VERSION ""

NS_ :

BS_:

BU_: GW_ABFD ADCU3_ABFD

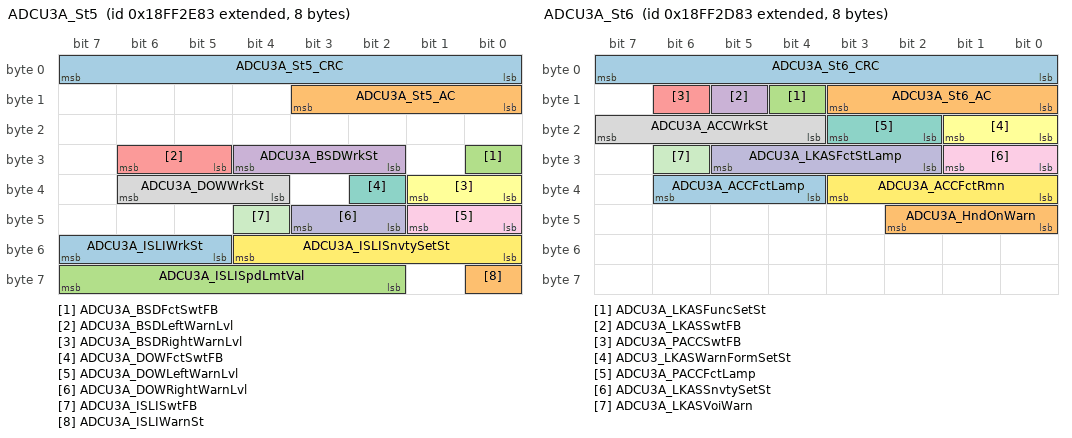
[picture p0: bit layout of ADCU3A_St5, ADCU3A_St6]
BO_ 2566860419 ADCU3A_St5: 8 ADCU3_ABFD
 SG_ ADCU3A_St5_CRC : 0|8@1+ (1,0) [0|255] "" Vector__XXX
 SG_ ADCU3A_St5_AC : 8|4@1+ (1,0) [0|14] "" Vector__XXX
 SG_ ADCU3A_BSDFctSwtFB : 24|1@1+ (1,0) [0|1] "" Vector__XXX
 SG_ ADCU3A_BSDWrkSt : 26|3@1+ (1,0) [0|7] "" Vector__XXX
 SG_ ADCU3A_BSDLeftWarnLvl : 29|2@1+ (1,0) [0|3] "" Vector__XXX
 SG_ ADCU3A_BSDRightWarnLvl : 32|2@1+ (1,0) [0|3] "" Vector__XXX
 SG_ ADCU3A_DOWFctSwtFB : 34|1@1+ (1,0) [0|1] "" Vector__XXX
 SG_ ADCU3A_DOWWrkSt : 36|3@1+ (1,0) [0|7] "" Vector__XXX
 SG_ ADCU3A_DOWLeftWarnLvl : 40|2@1+ (1,0) [0|3] "" Vector__XXX
 SG_ ADCU3A_DOWRightWarnLvl : 42|2@1+ (1,0) [0|3] "" Vector__XXX
 SG_ ADCU3A_ISLISwtFB : 44|1@1+ (1,0) [0|1] "" Vector__XXX
 SG_ ADCU3A_ISLISnvtySetSt : 48|5@1+ (1,-15) [-15|15] "km/h" Vector__XXX
 SG_ ADCU3A_ISLIWrkSt : 53|3@1+ (1,0) [0|7] "" Vector__XXX
 SG_ ADCU3A_ISLIWarnSt : 56|1@1+ (1,0) [0|1] "" Vector__XXX
 SG_ ADCU3A_ISLISpdLmtVal : 58|6@1+ (1,0) [0|63] "" Vector__XXX

BO_ 2566860163 ADCU3A_St6: 8 ADCU3_ABFD
 SG_ ADCU3A_St6_CRC : 0|8@1+ (1,0) [0|255] "" Vector__XXX
 SG_ ADCU3A_St6_AC : 8|4@1+ (1,0) [0|14] "" Vector__XXX
 SG_ ADCU3A_LKASFuncSetSt : 12|1@1+ (1,0) [0|1] "" Vector__XXX
 SG_ ADCU3A_LKASSwtFB : 13|1@1+ (1,0) [0|1] "" Vector__XXX
 SG_ ADCU3A_PACCSwtFB : 14|1@1+ (1,0) [0|1] "" Vector__XXX
 SG_ ADCU3_LKASWarnFormSetSt : 16|2@1+ (1,0) [0|3] "" Vector__XXX
 SG_ ADCU3A_PACCFctLamp : 18|2@1+ (1,0) [0|3] "" Vector__XXX
 SG_ ADCU3A_ACCWrkSt : 20|4@1+ (1,0) [0|15] "" Vector__XXX
 SG_ ADCU3A_LKASSnvtySetSt : 24|2@1+ (1,0) [0|3] "" Vector__XXX
 SG_ ADCU3A_LKASFctStLamp : 26|4@1+ (1,0) [0|15] "" Vector__XXX
 SG_ ADCU3A_LKASVoiWarn : 30|1@1+ (1,0) [0|1] "" Vector__XXX
 SG_ ADCU3A_ACCFctRmn : 32|4@1+ (1,0) [0|15] "" Vector__XXX
 SG_ ADCU3A_ACCFctLamp : 36|3@1+ (1,0) [0|7] "" Vector__XXX
 SG_ ADCU3A_HndOnWarn : 40|3@1+ (1,0) [0|7] "" Vector__XXX

BO_ 692 ADCU3A_St7: 16 ADCU3_ABFD
 SG_ ADCU3A_St7_CRC : 0|8@1+ (1,0) [0|255] "" Vector__XXX
 SG_ ADCU3A_St7_AC : 8|4@1+ (1,0) [0|14] "" Vector__XXX
 SG_ ADCU3A_AEBWrkSt : 12|3@1+ (1,0) [0|7] "" Vector__XXX
 SG_ ADCU3A_FwdCllsnPrevnSwtSt : 16|1@1+ (1,0) [0|1] "" Vector__XXX
 SG_ ADCU3A_FwdCllsnPrevnMdSwtSt : 17|1@1+ (1,0) [0|1] "" Vector__XXX
 SG_ ADCU3A_FwdCllsnPrevnSnvtySetSt : 18|2@1+ (1,0) [0|3] "" Vector__XXX
 SG_ ADCU3A_FCWAEBWarnLvl : 22|2@1+ (1,0) [0|3] "" Vector__XXX
 SG_ ADCU3A_FCWWrkSt : 24|3@1+ (1,0) [0|7] "" Vector__XXX
 SG_ ADCU3A_AEBTrgType : 27|2@1+ (1,0) [0|3] "" Vector__XXX
 SG_ ADCU3A_AEBTypeTar : 29|3@1+ (1,0) [0|7] "" Vector__XXX
 SG_ ADCU3A_AEBRelDst : 32|12@1+ (0.05,0) [0|204.75] "m" Vector__XXX
 SG_ ADCU3A_AEBRelSpd : 46|10@1+ (0.5,-255) [-255|255] "kph" Vector__XXX
 SG_ ADCU3A_AEBTTC : 56|8@1+ (0.05,0) [0|12.5] "s" Vector__XXX
 SG_ ADCU3A_FwdCllsnPrevnStLamp : 64|3@1+ (1,0) [0|7] "" Vector__XXX
 SG_ ADCU3A_FwdCllsnPrevnTstMsg : 67|3@1+ (1,0) [0|7] "" Vector__XXX
 SG_ ADCU3A_NightVisnSwtSt : 72|1@1+ (1,0) [0|1] "" Vector__XXX
 SG_ ADCU3A_NightVisnWarnMod : 73|2@1+ (1,0) [0|3] "" Vector__XXX
 SG_ ADCU3A_NightVisnFctWarn : 75|3@1+ (1,0) [0|7] "" Vector__XXX
 SG_ ADCU3A_NightVisnFctFlt : 78|1@1+ (1,0) [0|1] "" Vector__XXX

BO_ 1139 ADCU3A_Err: 16 ADCU3_ABFD
 SG_ ADCU3A_Err_CRC : 0|16@1+ (1,0) [0|65535] "" Vector__XXX
 SG_ ADCU3A_Err_AC : 16|8@1+ (1,0) [0|255] "" Vector__XXX
 SG_ ADCU3A_ADCU1Err : 24|2@1+ (1,0) [0|3] "" Vector__XXX
 SG_ ADCU3A_ADCU2Err : 26|2@1+ (1,0) [0|3] "" Vector__XXX
 SG_ ADCU3A_ADCU3Err : 28|2@1+ (1,0) [0|3] "" Vector__XXX
 SG_ ADCU3A_FrInfraredCamErr : 30|2@1+ (1,0) [0|3] "" Vector__XXX
 SG_ ADCU3A_FrRadarErr : 32|3@1+ (1,0) [0|7] "" Vector__XXX
 SG_ ADCU3A_LFCornrRadarErr : 35|3@1+ (1,0) [0|7] "" Vector__XXX
 SG_ ADCU3A_RFCornrRadarErr : 40|3@1+ (1,0) [0|7] "" Vector__XXX
 SG_ ADCU3A_LRCornrRadarErr : 43|3@1+ (1,0) [0|7] "" Vector__XXX
 SG_ ADCU3A_RRCornrRadarErr : 48|3@1+ (1,0) [0|7] "" Vector__XXX
 SG_ ADCU3A_LFSideViewCamErr : 53|2@1+ (1,0) [0|3] "" Vector__XXX
 SG_ ADCU3A_RFSideViewCamErr : 56|2@1+ (1,0) [0|3] "" Vector__XXX
 SG_ ADCU3A_LRSideViewCamErr : 58|2@1+ (1,0) [0|3] "" Vector__XXX
 SG_ ADCU3A_RRSideViewCamErr : 60|2@1+ (1,0) [0|3] "" Vector__XXX
 SG_ ADCU3A_FrSurrndViewCamErr : 62|2@1+ (1,0) [0|3] "" Vector__XXX
 SG_ ADCU3A_LFSurrndViewCamErr : 64|2@1+ (1,0) [0|3] "" Vector__XXX
 SG_ ADCU3A_RFSurrndViewCamErr : 66|2@1+ (1,0) [0|3] "" Vector__XXX
 SG_ ADCU3A_FrLidarErr : 68|2@1+ (1,0) [0|3] "" Vector__XXX
 SG_ ADCU3A_FrIntelgtCamErr : 72|3@1+ (1,0) [0|3] "" Vector__XXX
 SG_ ADCU3A_FrLongFocusCamErr : 75|2@1+ (1,0) [0|3] "" Vector__XXX
 SG_ ADCU3A_FrMidFocusCamErr : 77|2@1+ (1,0) [0|3] "" Vector__XXX
 SG_ ADCU3A_FrshrtFocusCamErr : 80|2@1+ (1,0) [0|3] "" Vector__XXX

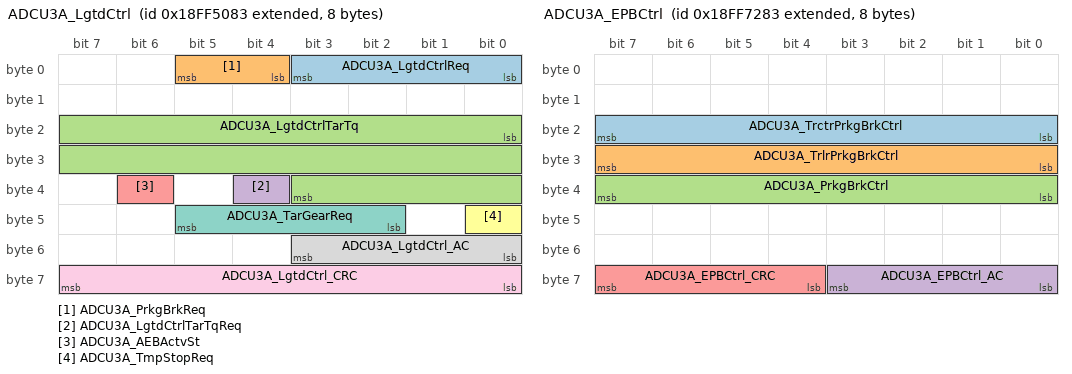
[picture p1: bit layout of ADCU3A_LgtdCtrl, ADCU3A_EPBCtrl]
BO_ 2566869123 ADCU3A_LgtdCtrl: 8 ADCU3_ABFD
 SG_ ADCU3A_LgtdCtrlReq : 0|4@1+ (1,0) [0|15] "" Vector__XXX
 SG_ ADCU3A_PrkgBrkReq : 4|2@1+ (1,0) [0|3] "" Vector__XXX
 SG_ ADCU3A_LgtdCtrlTarTq : 16|20@1+ (5,-150000) [-150000|150000] "Nm" Vector__XXX
 SG_ ADCU3A_LgtdCtrlTarTqReq : 36|1@1+ (1,0) [0|1] "" Vector__XXX
 SG_ ADCU3A_AEBActvSt : 38|1@1+ (1,0) [0|1] "" Vector__XXX
 SG_ ADCU3A_TmpStopReq : 40|1@1+ (1,0) [0|1] "" Vector__XXX
 SG_ ADCU3A_TarGearReq : 42|4@1+ (1,0) [0|15] "" Vector__XXX
 SG_ ADCU3A_LgtdCtrl_AC : 48|4@1+ (1,0) [0|14] "" Vector__XXX
 SG_ ADCU3A_LgtdCtrl_CRC : 56|8@1+ (1,0) [0|255] "" Vector__XXX

BO_ 2566877827 ADCU3A_EPBCtrl: 8 ADCU3_ABFD
 SG_ ADCU3A_TrctrPrkgBrkCtrl : 16|8@1+ (0.4,0) [0|100] "%" Vector__XXX
 SG_ ADCU3A_TrlrPrkgBrkCtrl : 24|8@1+ (0.4,0) [0|100] "%" Vector__XXX
 SG_ ADCU3A_PrkgBrkCtrl : 32|8@1+ (0.4,0) [0|100] "%" Vector__XXX
 SG_ ADCU3A_EPBCtrl_AC : 56|4@1+ (1,0) [0|15] "" Vector__XXX
 SG_ ADCU3A_EPBCtrl_CRC : 60|4@1+ (1,0) [0|15] "" Vector__XXX

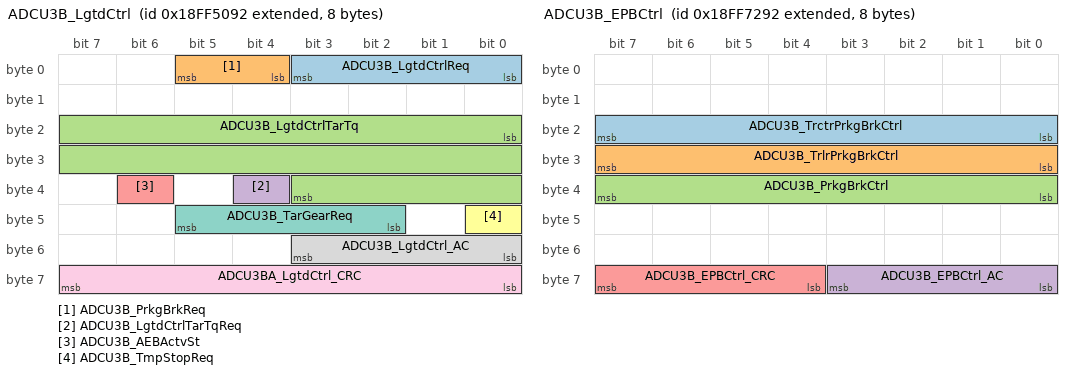
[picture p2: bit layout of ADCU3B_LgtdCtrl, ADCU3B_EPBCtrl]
BO_ 2566869138 ADCU3B_LgtdCtrl: 8 ADCU3_ABFD
 SG_ ADCU3B_LgtdCtrlReq : 0|4@1+ (1,0) [0|15] "" Vector__XXX
 SG_ ADCU3B_PrkgBrkReq : 4|2@1+ (1,0) [0|3] "" Vector__XXX
 SG_ ADCU3B_LgtdCtrlTarTq : 16|20@1+ (5,-150000) [-150000|150000] "Nm" Vector__XXX
 SG_ ADCU3B_LgtdCtrlTarTqReq : 36|1@1+ (1,0) [0|1] "" Vector__XXX
 SG_ ADCU3B_AEBActvSt : 38|1@1+ (1,0) [0|1] "" Vector__XXX
 SG_ ADCU3B_TmpStopReq : 40|1@1+ (1,0) [0|1] "" Vector__XXX
 SG_ ADCU3B_TarGearReq : 42|4@1+ (1,0) [0|15] "" Vector__XXX
 SG_ ADCU3B_LgtdCtrl_AC : 48|4@1+ (1,0) [0|14] "" Vector__XXX
 SG_ ADCU3BA_LgtdCtrl_CRC : 56|8@1+ (1,0) [0|255] "" Vector__XXX

BO_ 2566877842 ADCU3B_EPBCtrl: 8 ADCU3_ABFD
 SG_ ADCU3B_TrctrPrkgBrkCtrl : 16|8@1+ (0.4,0) [0|100] "%" Vector__XXX
 SG_ ADCU3B_TrlrPrkgBrkCtrl : 24|8@1+ (0.4,0) [0|100] "%" Vector__XXX
 SG_ ADCU3B_PrkgBrkCtrl : 32|8@1+ (0.4,0) [0|100] "%" Vector__XXX
 SG_ ADCU3B_EPBCtrl_AC : 56|4@1+ (1,0) [0|15] "" Vector__XXX
 SG_ ADCU3B_EPBCtrl_CRC : 60|4@1+ (1,0) [0|15] "" Vector__XXX

BO_ 2566860675 ADCU3A_BodyCtrl: 8 ADCU3_ABFD
 SG_ ADCU3A_BodyCtrl_CRC : 0|8@1+ (1,0) [0|255] "" Vector__XXX
 SG_ ADCU3A_BodyCtrl_AC : 8|4@1+ (1,0) [0|14] "" Vector__XXX
 SG_ ADCU3A_LeftTurnLgtReq : 12|2@1+ (1,0) [0|3] "" Vector__XXX
 SG_ ADCU3A_RightTurnLgtReq : 14|2@1+ (1,0) [0|3] "" Vector__XXX
 SG_ ADCU3A_HzrdLgtReq : 16|2@1+ (1,0) [0|3] "" Vector__XXX
 SG_ ADCU3A_LoLgtReq : 18|2@1+ (1,0) [0|3] "" Vector__XXX
 SG_ ADCU3A_OvtkLgtReq : 22|2@1+ (1,0) [0|3] "" Vector__XXX
 SG_ ADCU3A_SteerWhlVibrnReq : 24|2@1+ (1,0) [0|3] "" Vector__XXX
 SG_ ADCU3A_DrvrSeatVibrnReq : 26|2@1+ (1,0) [0|3] "" Vector__XXX
 SG_ ADCU3A_ClrCamReq : 28|2@1+ (1,0) [0|3] "" Vector__XXX
 SG_ ADCU3A_ClrLidarReq : 30|2@1+ (1,0) [0|3] "" Vector__XXX
 SG_ ADCU3A_DrvrSbltTightenUpReq : 32|2@1+ (1,0) [0|3] "" Vector__XXX
 SG_ ADCU3A_PsngerSbltTightenUpReq : 34|2@1+ (1,0) [0|3] "" Vector__XXX
 SG_ ADCU3A_WhistleReq : 36|2@1+ (1,0) [0|3] "" Vector__XXX
 SG_ ADCU3A_WindwClsdReq : 38|2@1+ (1,0) [0|3] "" Vector__XXX
 SG_ ADCU3A_VehLockdReq : 40|2@1+ (1,0) [0|3] "" Vector__XXX
 SG_ ADCU3A_MCUAErr : 43|1@1+ (1,0) [0|1] "" Vector__XXX
 SG_ ADCU3A_DrvgAutoGrd : 44|3@1+ (1,0) [0|7] "" Vector__XXX

BO_ 2566860690 ADCU3B_BodyCtrl: 8 ADCU3_ABFD
 SG_ ADCU3B_BodyCtrl_CRC : 0|8@1+ (1,0) [0|255] "" Vector__XXX
 SG_ ADCU3B_BodyCtrl_AC : 8|4@1+ (1,0) [0|14] "" Vector__XXX
 SG_ ADCU3B_LeftTurnLgtReq : 12|2@1+ (1,0) [0|3] "" Vector__XXX
 SG_ ADCU3B_RightTurnLgtReq : 14|2@1+ (1,0) [0|3] "" Vector__XXX
 SG_ ADCU3B_HzrdLgtReq : 16|2@1+ (1,0) [0|3] "" Vector__XXX
 SG_ ADCU3B_LoLgtReq : 18|2@1+ (1,0) [0|3] "" Vector__XXX
 SG_ ADCU3B_OvtkLgtReq : 22|2@1+ (1,0) [0|3] "" Vector__XXX
 SG_ ADCU3B_DrvrSeatVibrnReq : 26|2@1+ (1,0) [0|3] "" Vector__XXX
 SG_ ADCU3B_ClrCamReq : 28|2@1+ (1,0) [0|3] "" Vector__XXX
 SG_ ADCU3B_ClrLidarReq : 30|2@1+ (1,0) [0|3] "" Vector__XXX
 SG_ ADCU3B_DrvrSbltTightenUpReq : 32|2@1+ (1,0) [0|3] "" Vector__XXX
 SG_ ADCU3B_PsngerSbltTightenUpReq : 34|2@1+ (1,0) [0|3] "" Vector__XXX
 SG_ ADCU3B_WhistleReq : 36|2@1+ (1,0) [0|3] "" Vector__XXX
 SG_ ADCU3B_WindwClsdReq : 38|2@1+ (1,0) [0|3] "" Vector__XXX
 SG_ ADCU3B_VehLockdReq : 40|2@1+ (1,0) [0|3] "" Vector__XXX
 SG_ ADCU3B_MCUBErr : 43|1@1+ (1,0) [0|1] "" Vector__XXX
 SG_ ADCU3B_DrvgAutoGrd : 44|3@1+ (1,0) [0|7] "" Vector__XXX

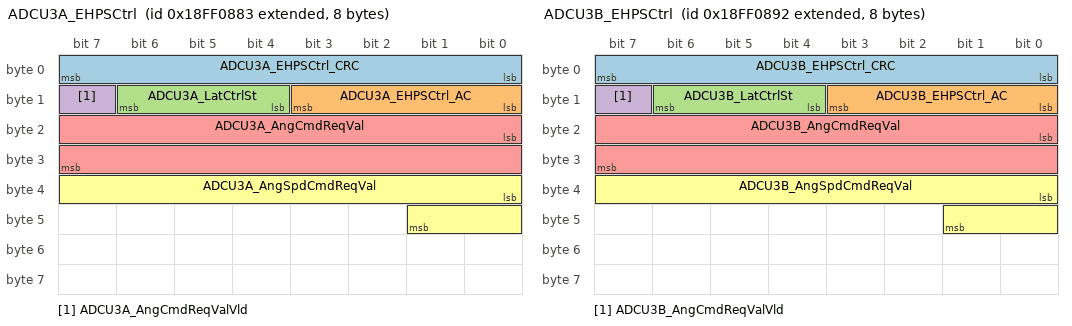
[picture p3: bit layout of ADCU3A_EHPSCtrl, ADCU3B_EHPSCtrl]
BO_ 2566850691 ADCU3A_EHPSCtrl: 8 ADCU3_ABFD
 SG_ ADCU3A_EHPSCtrl_CRC : 0|8@1+ (1,0) [0|255] "" Vector__XXX
 SG_ ADCU3A_EHPSCtrl_AC : 8|4@1+ (1,0) [0|14] "" Vector__XXX
 SG_ ADCU3A_LatCtrlSt : 12|3@1+ (1,0) [0|7] "" Vector__XXX
 SG_ ADCU3A_AngCmdReqValVld : 15|1@1+ (1,0) [0|1] "" Vector__XXX
 SG_ ADCU3A_AngCmdReqVal : 16|16@1+ (0.1,-1575) [-1575|1575] "" Vector__XXX
 SG_ ADCU3A_AngSpdCmdReqVal : 32|10@1+ (4,-1016) [-1016|1016] "" Vector__XXX

BO_ 2566850706 ADCU3B_EHPSCtrl: 8 ADCU3_ABFD
 SG_ ADCU3B_EHPSCtrl_CRC : 0|8@1+ (1,0) [0|255] "" Vector__XXX
 SG_ ADCU3B_EHPSCtrl_AC : 8|4@1+ (1,0) [0|14] "" Vector__XXX
 SG_ ADCU3B_LatCtrlSt : 12|3@1+ (1,0) [0|7] "" Vector__XXX
 SG_ ADCU3B_AngCmdReqValVld : 15|1@1+ (1,0) [0|1] "" Vector__XXX
 SG_ ADCU3B_AngCmdReqVal : 16|16@1+ (0.1,-1575) [-1575|1575] "deg" Vector__XXX
 SG_ ADCU3B_AngSpdCmdReqVal : 32|10@1+ (4,-1016) [-1016|1016] "deg/s" Vector__XXX

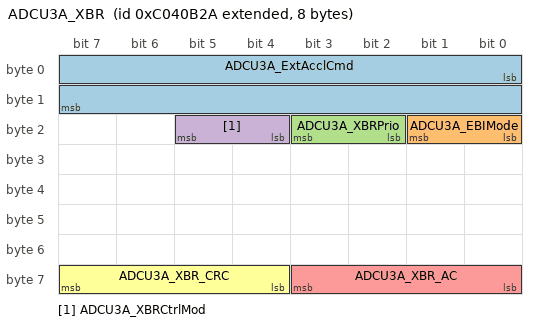
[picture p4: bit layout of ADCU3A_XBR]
BO_ 2349075242 ADCU3A_XBR: 8 ADCU3_ABFD
 SG_ ADCU3A_ExtAcclCmd : 0|16@1+ (0.00048828125,-15.687) [-10|10] "m/s^2" Vector__XXX
 SG_ ADCU3A_EBIMode : 16|2@1+ (1,0) [0|3] "" Vector__XXX
 SG_ ADCU3A_XBRPrio : 18|2@1+ (1,0) [0|3] "" Vector__XXX
 SG_ ADCU3A_XBRCtrlMod : 20|2@1+ (1,0) [0|3] "" Vector__XXX
 SG_ ADCU3A_XBR_AC : 56|4@1+ (1,0) [0|15] "" Vector__XXX
 SG_ ADCU3A_XBR_CRC : 60|4@1+ (1,0) [0|15] "" Vector__XXX

BO_ 563 ADCU3A_IMU: 16 ADCU3_ABFD
 SG_ ADCU3A_IMU_CRC : 0|16@1+ (1,0) [0|65535] "" Vector__XXX
 SG_ ADCU3A_IMU_AC : 16|8@1+ (1,0) [0|255] "" Vector__XXX
 SG_ ADCU3A_LgtdAccl : 24|12@1+ (0.01,-15) [-15|15] "m/s^2" Vector__XXX
 SG_ ADCU3A_LgtdAcclVld : 39|1@1+ (1,0) [0|1] "" Vector__XXX
 SG_ ADCU3A_LatAccl : 40|12@1+ (0.01,-15) [-15|15] "m/s^2" Vector__XXX
 SG_ ADCU3A_LatAcclVld : 55|1@1+ (1,0) [0|1] "" Vector__XXX
 SG_ ADCU3A_VertAccl : 56|12@1+ (0.01,-15) [-15|15] "m/s^2" Vector__XXX
 SG_ ADCU3A_VertAcclVld : 71|1@1+ (1,0) [0|1] "" Vector__XXX

CM_ SG_ 2566860419 ADCU3A_St5_CRC "CRC8";
CM_ SG_ 2566860419 ADCU3A_St5_AC "Alive Counter";
CM_ SG_ 2566860419 ADCU3A_BSDFctSwtFB "BSD function switch Feedback
BSD功能开关反馈状态";
CM_ SG_ 2566860419 ADCU3A_BSDWrkSt "BSD work state
BSD工作状态";
CM_ SG_ 2566860419 ADCU3A_BSDLeftWarnLvl "BSD left warning Level
BSD左侧报警等级";
CM_ SG_ 2566860419 ADCU3A_BSDRightWarnLvl "BSD right warning Level
BSD右侧报警等级";
CM_ SG_ 2566860419 ADCU3A_DOWFctSwtFB "DOW function switch Feedback
DOW功能开关状态";
CM_ SG_ 2566860419 ADCU3A_DOWWrkSt "DOW work state
DOW工作状态";
CM_ SG_ 2566860419 ADCU3A_DOWLeftWarnLvl "DOW left warning Level
DOW左侧报警等级";
CM_ SG_ 2566860419 ADCU3A_DOWRightWarnLvl "DOW right warning Level
DOW右侧报警等级";
CM_ SG_ 2566860419 ADCU3A_ISLISwtFB "ISLI switch Feedback
ISLI开关状态反馈";
CM_ SG_ 2566860419 ADCU3A_ISLISnvtySetSt "ISLI sensitivity set Feedback
ISLI限速灵敏度设置反馈状态";
CM_ SG_ 2566860419 ADCU3A_ISLIWrkSt "ISLI work state
ISLI工作状态";
CM_ SG_ 2566860419 ADCU3A_ISLIWarnSt "ISLI warning state
ISLI报警等级";
CM_ SG_ 2566860419 ADCU3A_ISLISpdLmtVal "ISLI speed limit Value
ISLI限速值";
CM_ SG_ 2566860163 ADCU3A_St6_CRC "CRC8";
CM_ SG_ 2566860163 ADCU3A_St6_AC "Alive Counter";
CM_ SG_ 2566860163 ADCU3A_LKASFuncSetSt "LKAS Function Setting state
LKAS辅助等级设置反馈状态";
CM_ SG_ 2566860163 ADCU3A_LKASSwtFB "LKAS switch Feedback
LKAS功能开关反馈状态";
CM_ SG_ 2566860163 ADCU3A_PACCSwtFB "PACC switch Feedback
PACC功能开关反馈状态";
CM_ SG_ 2566860163 ADCU3_LKASWarnFormSetSt "LKAS Warnning Form Setting state
LKAS提醒方式设置反馈状态";
CM_ SG_ 2566860163 ADCU3A_PACCFctLamp "PACC function state Indicated
PACC功能状态指示灯";
CM_ SG_ 2566860163 ADCU3A_ACCWrkSt "ACC Work State
ACC工作状态";
CM_ SG_ 2566860163 ADCU3A_LKASSnvtySetSt "LKAS Snvty Setting state
LKAS灵敏度设置反馈状态";
CM_ SG_ 2566860163 ADCU3A_LKASFctStLamp "LKAS Function State Lamp
LKAS功能指示灯";
CM_ SG_ 2566860163 ADCU3A_LKASVoiWarn "LKAS Function Sound Warnning
LKAS功能声音提醒";
CM_ SG_ 2566860163 ADCU3A_ACCFctRmn "ACC function reminder
ACC功能提醒";
CM_ SG_ 2566860163 ADCU3A_ACCFctLamp "ACC Function State Indicated
ACC功能状态指示灯";
CM_ SG_ 2566860163 ADCU3A_HndOnWarn "Hands off warning
脱手提醒";
CM_ SG_ 692 ADCU3A_St7_CRC "CRC8";
CM_ SG_ 692 ADCU3A_St7_AC "Alive Counter";
CM_ SG_ 692 ADCU3A_AEBWrkSt "AEB function state
AEB功能状态";
CM_ SG_ 692 ADCU3A_FwdCllsnPrevnSwtSt "Forward Collision Prevention  Switch State
前向防撞辅助开关反馈状态";
CM_ SG_ 692 ADCU3A_FwdCllsnPrevnMdSwtSt "Forward Collision Prevention  Mode Switch State
前向防撞辅助模式反馈状态";
CM_ SG_ 692 ADCU3A_FwdCllsnPrevnSnvtySetSt "Forward Collision Prevention  Sensitivity Set State
前向防撞辅助灵敏度设置确认反馈状态";
CM_ SG_ 692 ADCU3A_FCWAEBWarnLvl "FCW AEBwarning Level
FCW AEB报警等级";
CM_ SG_ 692 ADCU3A_FCWWrkSt "FCW functional state
FCW功能状态";
CM_ SG_ 692 ADCU3A_AEBTrgType "AEB trigger type
AEB触发类型";
CM_ SG_ 692 ADCU3A_AEBTypeTar "AEB type target
目标类型";
CM_ SG_ 692 ADCU3A_AEBRelDst "AEB relative distance
目标相对距离";
CM_ SG_ 692 ADCU3A_AEBRelSpd "AEB relative speed
目标相对速度";
CM_ SG_ 692 ADCU3A_AEBTTC "Time to collision with relevant object
距离碰撞时间TTC";
CM_ SG_ 692 ADCU3A_FwdCllsnPrevnStLamp "Forward Collision Prevention State Lamp
前向防撞辅助功能状态灯";
CM_ SG_ 692 ADCU3A_FwdCllsnPrevnTstMsg "Forward Collision Prevention Toast Message
前向防撞辅助弹窗提示信息";
CM_ SG_ 692 ADCU3A_NightVisnSwtSt "Night Vision Switch State
夜视辅助开关状态";
CM_ SG_ 692 ADCU3A_NightVisnWarnMod "Night Vision  Warning Mode
夜视辅助报警模式";
CM_ SG_ 692 ADCU3A_NightVisnFctWarn "Night Vision Function Warning
夜视辅助功能报警";
CM_ SG_ 692 ADCU3A_NightVisnFctFlt "Night Vision Function Fault
夜视辅助功能故障";
CM_ SG_ 1139 ADCU3A_Err_CRC "CRC16";
CM_ SG_ 1139 ADCU3A_Err_AC "Alive Counter";
CM_ SG_ 1139 ADCU3A_ADCU1Err "ADCU1 fault State
ADCU1故障状态";
CM_ SG_ 1139 ADCU3A_ADCU2Err "ADCU3 fault State
ADCU2故障状态";
CM_ SG_ 1139 ADCU3A_ADCU3Err "ADCU3 fault State
ADCU3故障状态";
CM_ SG_ 1139 ADCU3A_FrInfraredCamErr "Front Infrared camera Error
前红外摄像头故障";
CM_ SG_ 1139 ADCU3A_FrRadarErr "Front radar Error
前毫米波雷达故障";
CM_ SG_ 1139 ADCU3A_LFCornrRadarErr "Front left corner radar Error
左前角毫米波雷达故障";
CM_ SG_ 1139 ADCU3A_RFCornrRadarErr "Front Right corner radar Error
右前角毫米波雷达故障";
CM_ SG_ 1139 ADCU3A_LRCornrRadarErr "Rear Left corner radar Error
左后角毫米波雷达故障";
CM_ SG_ 1139 ADCU3A_RRCornrRadarErr "Rear Right corner radar Error
右后角毫米波雷达故障";
CM_ SG_ 1139 ADCU3A_LFSideViewCamErr "Left front Side View camera Error
侧视摄像头_左前故障";
CM_ SG_ 1139 ADCU3A_RFSideViewCamErr "Right front Side View camera Error
侧视摄像头_右前故障";
CM_ SG_ 1139 ADCU3A_LRSideViewCamErr "Left Rear Side View camera Error
侧视摄像头_左后故障";
CM_ SG_ 1139 ADCU3A_RRSideViewCamErr "Right Rear Side View camera Error
侧视摄像头_右后故障";
CM_ SG_ 1139 ADCU3A_FrSurrndViewCamErr "Front surround View camera Error
环视摄像头_前故障";
CM_ SG_ 1139 ADCU3A_LFSurrndViewCamErr "Left Front surround View camera Error
环视摄像头_左前故障";
CM_ SG_ 1139 ADCU3A_RFSurrndViewCamErr "Right Front surround View camera Error
环视摄像头_右前故障";
CM_ SG_ 1139 ADCU3A_FrLidarErr "Front Lidar Error
激光雷达故障";
CM_ SG_ 1139 ADCU3A_FrIntelgtCamErr "Front Intelligent camera Error
前视智能摄像头故障";
CM_ SG_ 1139 ADCU3A_FrLongFocusCamErr "Front long focus camera Error
前视摄像头_远距故障";
CM_ SG_ 1139 ADCU3A_FrMidFocusCamErr "Front middle focus camera Error
前视摄像头_中距故障";
CM_ SG_ 1139 ADCU3A_FrshrtFocusCamErr "Front short focus camera Error
前视摄像头_短距故障";
CM_ SG_ 2566869123 ADCU3A_LgtdCtrlReq "Longitudial control request
纵向控制请求";
CM_ SG_ 2566869123 ADCU3A_PrkgBrkReq "Parking brake Request
驻车制动请求";
CM_ SG_ 2566869123 ADCU3A_LgtdCtrlTarTq "Longitudial control Target Torque
纵向控制目标扭矩";
CM_ SG_ 2566869123 ADCU3A_LgtdCtrlTarTqReq "Longitudinal control target torque request
纵向控制目标扭矩请求";
CM_ SG_ 2566869123 ADCU3A_AEBActvSt "AEB Active State
AEB激活状态";
CM_ SG_ 2566869123 ADCU3A_TmpStopReq "EBS Temporary Stop Request
EBS临停保压请求";
CM_ SG_ 2566869123 ADCU3A_TarGearReq "Targer Gear request
目标档位请求";
CM_ SG_ 2566869123 ADCU3A_LgtdCtrl_AC "Alive Counter";
CM_ SG_ 2566877827 ADCU3A_TrctrPrkgBrkCtrl "Tractor Parking brake control
主车驻车制动控制";
CM_ SG_ 2566877827 ADCU3A_TrlrPrkgBrkCtrl "Trailer Parking brake control
挂车驻车制动控制";
CM_ SG_ 2566877827 ADCU3A_PrkgBrkCtrl "Tractor and Trailer Parking brake control
主车挂车驻车制动控制";
CM_ SG_ 2566877827 ADCU3A_EPBCtrl_AC "Alive Counter";
CM_ SG_ 2566877827 ADCU3A_EPBCtrl_CRC "CRC";
CM_ SG_ 2566869138 ADCU3B_LgtdCtrlReq "Longitudial control request
纵向控制请求";
CM_ SG_ 2566869138 ADCU3B_PrkgBrkReq "Parking brake Request
驻车制动请求";
CM_ SG_ 2566869138 ADCU3B_LgtdCtrlTarTq "Longitudial control Target Torque
纵向控制目标扭矩";
CM_ SG_ 2566869138 ADCU3B_LgtdCtrlTarTqReq "Longitudinal control target torque request
纵向控制目标扭矩请求";
CM_ SG_ 2566869138 ADCU3B_AEBActvSt "AEB Active State
AEB激活状态";
CM_ SG_ 2566869138 ADCU3B_TmpStopReq "EBS  pressure holding request
EBS临停保压请求";
CM_ SG_ 2566869138 ADCU3B_TarGearReq "Targer Gear request
目标档位请求";
CM_ SG_ 2566869138 ADCU3B_LgtdCtrl_AC "Alive Counter";
CM_ SG_ 2566877842 ADCU3B_TrctrPrkgBrkCtrl "Tractor Parking brake control
主车驻车制动控制";
CM_ SG_ 2566877842 ADCU3B_TrlrPrkgBrkCtrl "Trailer Parking brake control
挂车驻车制动控制";
CM_ SG_ 2566877842 ADCU3B_PrkgBrkCtrl "Tractor and Trailer Parking brake control
主车挂车驻车制动控制";
CM_ SG_ 2566877842 ADCU3B_EPBCtrl_AC "Alive Counter";
CM_ SG_ 2566860675 ADCU3A_BodyCtrl_CRC "CRC8";
CM_ SG_ 2566860675 ADCU3A_BodyCtrl_AC "Alive Counter";
CM_ SG_ 2566860675 ADCU3A_LeftTurnLgtReq "Left turn light request
左转向灯请求";
CM_ SG_ 2566860675 ADCU3A_RightTurnLgtReq "Right trun light request
右转向灯请求";
CM_ SG_ 2566860675 ADCU3A_HzrdLgtReq "Hazard light request
双闪灯请求";
CM_ SG_ 2566860675 ADCU3A_LoLgtReq "Low Light request
近光灯请求";
CM_ SG_ 2566860675 ADCU3A_OvtkLgtReq "Overtake Light request
超车灯请求";
CM_ SG_ 2566860675 ADCU3A_SteerWhlVibrnReq "Steering Wheel Vibrate request 
方向盘振动请求";
CM_ SG_ 2566860675 ADCU3A_DrvrSeatVibrnReq "Driver Seat Vibration request
主驾座椅振动请求";
CM_ SG_ 2566860675 ADCU3A_ClrCamReq "Clear Camera request
摄像头清洁请求";
CM_ SG_ 2566860675 ADCU3A_ClrLidarReq "Clear Lidar request
激光雷达清洁请求";
CM_ SG_ 2566860675 ADCU3A_DrvrSbltTightenUpReq "Driver Seatbelt Tighten Up request
主驾安全带预紧请求";
CM_ SG_ 2566860675 ADCU3A_PsngerSbltTightenUpReq "Passenger Seatbelt Tighten Up request
副驾安全带预紧请求";
CM_ SG_ 2566860675 ADCU3A_WhistleReq "Whistle request
鸣笛请求";
CM_ SG_ 2566860675 ADCU3A_WindwClsdReq "Window Closed request
自动代客泊车关窗请求";
CM_ SG_ 2566860675 ADCU3A_VehLockdReq "Vehicle Locked request
锁车请求";
CM_ SG_ 2566860675 ADCU3A_MCUAErr "MCUA fault state
MCUA故障状态";
CM_ SG_ 2566860675 ADCU3A_DrvgAutoGrd "Driving Atuomation Grade
自动驾驶等级";
CM_ SG_ 2566860690 ADCU3B_BodyCtrl_CRC "CRC8";
CM_ SG_ 2566860690 ADCU3B_BodyCtrl_AC "Alive Counter";
CM_ SG_ 2566860690 ADCU3B_LeftTurnLgtReq "Left turn light request
左转向灯请求";
CM_ SG_ 2566860690 ADCU3B_RightTurnLgtReq "Right trun light request
右转向灯请求";
CM_ SG_ 2566860690 ADCU3B_HzrdLgtReq "Hazard light request
双闪灯请求";
CM_ SG_ 2566860690 ADCU3B_LoLgtReq "Low light request
近光灯请求";
CM_ SG_ 2566860690 ADCU3B_OvtkLgtReq "Overtake light request
超车灯请求";
CM_ SG_ 2566860690 ADCU3B_DrvrSeatVibrnReq "Driver seat vibration request
主驾座椅振动请求";
CM_ SG_ 2566860690 ADCU3B_ClrCamReq "Clear camera request
摄像头清洁请求";
CM_ SG_ 2566860690 ADCU3B_ClrLidarReq "Clear lidar request
激光雷达清洁请求";
CM_ SG_ 2566860690 ADCU3B_DrvrSbltTightenUpReq "Driver seatbelt tighten up request
主驾安全带预紧请求";
CM_ SG_ 2566860690 ADCU3B_PsngerSbltTightenUpReq "Passenger seatbelt tighten up request
副驾安全带预紧请求";
CM_ SG_ 2566860690 ADCU3B_WhistleReq "Whistle request
鸣笛请求";
CM_ SG_ 2566860690 ADCU3B_WindwClsdReq "Window closed request
自动代客泊车关窗请求";
CM_ SG_ 2566860690 ADCU3B_VehLockdReq "Vehicle locked request
锁车请求";
CM_ SG_ 2566860690 ADCU3B_MCUBErr "MCUA fault state
MCUB故障状态";
CM_ SG_ 2566860690 ADCU3B_DrvgAutoGrd "Driving atuomation grade
自动驾驶等级";
CM_ SG_ 2566850691 ADCU3A_EHPSCtrl_CRC "CRC8";
CM_ SG_ 2566850691 ADCU3A_EHPSCtrl_AC "Alive Counter";
CM_ SG_ 2566850691 ADCU3A_LatCtrlSt "Lateral control request
横向控制请求";
CM_ SG_ 2566850691 ADCU3A_AngCmdReqValVld "Angle command request Value Valid
方向盘目标转角有效性";
CM_ SG_ 2566850691 ADCU3A_AngCmdReqVal "Angle command request Value
方向盘目标转角请求值";
CM_ SG_ 2566850691 ADCU3A_AngSpdCmdReqVal "Angle speed command request Value
方向盘转速目标";
CM_ SG_ 2566850706 ADCU3B_EHPSCtrl_CRC "CRC8";
CM_ SG_ 2566850706 ADCU3B_EHPSCtrl_AC "Alive Counter";
CM_ SG_ 2566850706 ADCU3B_LatCtrlSt "Lateral control request
横向控制请求";
CM_ SG_ 2566850706 ADCU3B_AngCmdReqValVld "Angle command request Value Valid
方向盘目标转角有效性";
CM_ SG_ 2566850706 ADCU3B_AngCmdReqVal "Angle command request Value
方向盘目标转角请求值";
CM_ SG_ 2566850706 ADCU3B_AngSpdCmdReqVal "Angle speed command request Value
方向盘转速目标";
CM_ SG_ 2349075242 ADCU3A_ExtAcclCmd "External acceleration command
外部加速度命令";
CM_ SG_ 2349075242 ADCU3A_EBIMode "XBR EBI mode
持久制动集成模式";
CM_ SG_ 2349075242 ADCU3A_XBRPrio "XBR priority
优先级";
CM_ SG_ 2349075242 ADCU3A_XBRCtrlMod "XBR Control Mode
XBR控制模式";
CM_ SG_ 2349075242 ADCU3A_XBR_AC "XBR Message Counter";
CM_ SG_ 2349075242 ADCU3A_XBR_CRC "XBR Message Checksum";
CM_ SG_ 563 ADCU3A_IMU_CRC "CRC16";
CM_ SG_ 563 ADCU3A_IMU_AC "Alive Counter";
CM_ SG_ 563 ADCU3A_LgtdAccl "Longitudinal Acceleration
IMU纵向加速度";
CM_ SG_ 563 ADCU3A_LgtdAcclVld "Longitudinal Acceleration Validity
IMU纵向加速度有效性";
CM_ SG_ 563 ADCU3A_LatAccl "Lateral Acceleration
IMU横向加速度";
CM_ SG_ 563 ADCU3A_LatAcclVld "Lateral Acceleration Validity
IMU横向加速度有效性";
CM_ SG_ 563 ADCU3A_VertAccl "Vertical Acceleration
IMU垂向加速度";
CM_ SG_ 563 ADCU3A_VertAcclVld "Vertical Acceleration Validity
IMU垂向加速度有效性";
BA_DEF_ BO_  "DiagState" ENUM  "No","Yes";
BA_DEF_ BO_  "GenMsgSendType" ENUM  "Cyclic","Event","IfActive","CE","CA","NoMsgSendType";
BA_DEF_ BO_  "GenMsgCycleTime" INT 0 0;
BA_DEF_ SG_  "GenSigSendType" ENUM  "Cyclic","OnChange","OnWrite","IfActive","OnChangeWithRepetition","OnWriteWithRepetition","IfActiveWithRepetition","NoSigSendType","OnChangeAndIfActive","OnChangeAndIfActiveWithRepetition","CA","CE","Event";
BA_DEF_ SG_  "GenSigStartValue" INT 0 0;
BA_DEF_ BO_  "GenMsgCycleTimeFast" INT 0 0;
BA_DEF_ BO_  "CANFD_BRS" ENUM  "0","1";
BA_DEF_ BO_  "VFrameFormat" ENUM  "StandardCAN","ExtendedCAN","reserved","reserved","reserved","reserved","reserved","reserved","reserved","reserved","reserved","reserved","reserved","reserved","StandardCAN_FD","ExtendedCAN_FD";
BA_DEF_DEF_  "DiagState" "No";
BA_DEF_DEF_  "GenMsgSendType" "Cyclic";
BA_DEF_DEF_  "GenMsgCycleTime" 0;
BA_DEF_DEF_  "GenSigSendType" "Cyclic";
BA_DEF_DEF_  "GenSigStartValue" 0;
BA_DEF_DEF_  "GenMsgCycleTimeFast" 0;
BA_DEF_DEF_  "CANFD_BRS" "1";
BA_DEF_DEF_  "VFrameFormat" "StandardCAN_FD";
BA_ "GenMsgCycleTime" BO_ 2566860419 50;
BA_ "VFrameFormat" BO_ 2566860419 15;
BA_ "GenMsgCycleTime" BO_ 2566860163 50;
BA_ "VFrameFormat" BO_ 2566860163 15;
BA_ "GenMsgCycleTime" BO_ 692 50;
BA_ "GenMsgCycleTime" BO_ 1139 200;
BA_ "GenMsgCycleTime" BO_ 2566869123 20;
BA_ "VFrameFormat" BO_ 2566869123 15;
BA_ "GenMsgCycleTime" BO_ 2566877827 20;
BA_ "VFrameFormat" BO_ 2566877827 15;
BA_ "GenMsgCycleTime" BO_ 2566869138 20;
BA_ "VFrameFormat" BO_ 2566869138 15;
BA_ "GenMsgCycleTime" BO_ 2566877842 20;
BA_ "VFrameFormat" BO_ 2566877842 15;
BA_ "GenMsgCycleTime" BO_ 2566860675 50;
BA_ "VFrameFormat" BO_ 2566860675 15;
BA_ "GenMsgCycleTime" BO_ 2566860690 50;
BA_ "VFrameFormat" BO_ 2566860690 15;
BA_ "GenMsgCycleTime" BO_ 2566850691 20;
BA_ "VFrameFormat" BO_ 2566850691 15;
BA_ "GenMsgCycleTime" BO_ 2566850706 20;
BA_ "VFrameFormat" BO_ 2566850706 15;
BA_ "GenMsgCycleTimeFast" BO_ 2349075242 20;
BA_ "GenMsgCycleTime" BO_ 2349075242 200;
BA_ "GenMsgSendType" BO_ 2349075242 4;
BA_ "VFrameFormat" BO_ 2349075242 15;
BA_ "GenMsgCycleTime" BO_ 563 20;
BA_ "GenSigStartValue" SG_ 2566860419 ADCU3A_ISLISnvtySetSt 15;
BA_ "GenSigStartValue" SG_ 2566860163 ADCU3A_LKASSwtFB 1;
BA_ "GenSigStartValue" SG_ 692 ADCU3A_FwdCllsnPrevnSwtSt 1;
BA_ "GenSigStartValue" SG_ 692 ADCU3A_FwdCllsnPrevnMdSwtSt 1;
BA_ "GenSigStartValue" SG_ 692 ADCU3A_AEBRelDst 4094;
BA_ "GenSigStartValue" SG_ 692 ADCU3A_AEBRelSpd 1020;
BA_ "GenSigStartValue" SG_ 692 ADCU3A_AEBTTC 250;
BA_ "GenSigSendType" SG_ 2349075242 ADCU3A_ExtAcclCmd 3;
BA_ "GenSigSendType" SG_ 2349075242 ADCU3A_EBIMode 3;
BA_ "GenSigSendType" SG_ 2349075242 ADCU3A_XBRPrio 3;
BA_ "GenSigSendType" SG_ 2349075242 ADCU3A_XBRCtrlMod 3;
VAL_ 2566860419 ADCU3A_BSDFctSwtFB 1 "On" 0 "Off" ;
VAL_ 2566860419 ADCU3A_BSDWrkSt 7 "Reserved" 6 "Reserved" 5 "Reserved" 4 "Reserved" 3 "Fault" 2 "Active" 1 "Stand by" 0 "Off" ;
VAL_ 2566860419 ADCU3A_BSDLeftWarnLvl 3 "Reserved" 2 "Warning Level 2-Highest" 1 "Warning Level 1 - Lowest" 0 "No Warning" ;
VAL_ 2566860419 ADCU3A_BSDRightWarnLvl 3 "Reserved" 2 "Warning Level 2-Highest" 1 "Warning Level 1 - Lowest" 0 "No Warning" ;
VAL_ 2566860419 ADCU3A_DOWFctSwtFB 1 "On" 0 "Off" ;
VAL_ 2566860419 ADCU3A_DOWWrkSt 7 "Reserved" 6 "Reserved" 5 "Reserved" 4 "Reserved" 3 "Fault" 2 "Active" 1 "Stand by" 0 "Off" ;
VAL_ 2566860419 ADCU3A_DOWLeftWarnLvl 3 "Reserved" 2 "Warning Level 2-Highest" 1 "Warning Level 1 - Lowest" 0 "No Warning" ;
VAL_ 2566860419 ADCU3A_DOWRightWarnLvl 3 "Reserved" 2 "Warning Level 2-Highest" 1 "Warning Level 1 - Lowest" 0 "No Warning" ;
VAL_ 2566860419 ADCU3A_ISLISwtFB 1 "On" 0 "Off" ;
VAL_ 2566860419 ADCU3A_ISLISnvtySetSt 31 "Invalid" ;
VAL_ 2566860419 ADCU3A_ISLIWrkSt 7 "Reserved" 6 "Reserved" 5 "Reserved" 4 "Reserved" 3 "Fault" 2 "Active" 1 "Stand by" 0 "Off" ;
VAL_ 2566860419 ADCU3A_ISLIWarnSt 1 "Warning" 0 "No Warning" ;
VAL_ 2566860419 ADCU3A_ISLISpdLmtVal 63 "Invalid" 62 "Reserved" 61 "Reserved" 60 "Reserved" 59 "Reserved" 58 "Reserved" 57 "Reserved" 56 "Reserved" 55 "Reserved" 54 "Reserved" 53 "Reserved" 52 "Reserved" 51 "Reserved" 50 "Reserved" 49 "Reserved" 48 "Reserved" 47 "Reserved" 46 "Reserved" 45 "Reserved" 44 "Reserved" 43 "Reserved" 42 "Reserved" 41 "Reserved" 40 "Reserved" 39 "Reserved" 38 "Reserved" 37 "Reserved" 36 "Reserved" 35 "Reserved" 34 "Reserved" 33 "Reserved" 32 "Reserved" 31 "Reserved" 30 "SPL 150" 29 "SPL 145" 28 "SPL 140" 27 "SPL 135" 26 "SPL 130" 25 "SPL 125" 24 "SPL 120" 23 "SPL 115" 22 "SPL 110" 21 "SPL 105" 20 "SPL 100" 19 "SPL 95" 18 "SPL 90" 17 "SPL 85" 16 "SPL 80" 15 "SPL 75" 14 "SPL 70" 13 "SPL 65" 12 "SPL 60" 11 "SPL 55" 10 "SPL 50" 9 "SPL 45" 8 "SPL 40" 7 "SPL 35" 6 "SPL 30" 5 "SPL 25" 4 "SPL 20" 3 "SPL 15" 2 "SPL 10" 1 "SPL 5" 0 "No Display" ;
VAL_ 2566860163 ADCU3A_LKASFuncSetSt 1 "LKA on" 0 "LDW on" ;
VAL_ 2566860163 ADCU3A_LKASSwtFB 1 "On" 0 "Off" ;
VAL_ 2566860163 ADCU3A_PACCSwtFB 1 "On" 0 "Off" ;
VAL_ 2566860163 ADCU3_LKASWarnFormSetSt 3 "Reserved" 2 "Voice and Haptic" 1 "Haptic" 0 "Voice" ;
VAL_ 2566860163 ADCU3A_PACCFctLamp 3 "Reserved" 2 "Reserved" 1 "On" 0 "Off" ;
VAL_ 2566860163 ADCU3A_ACCWrkSt 15 "Reserved" 14 "Reserved" 13 "Reserved" 12 "Reserved" 11 "Reserved" 10 "Reserved" 9 "Reserved" 8 "BrakeOnly" 7 "Override" 6 "StandWait" 5 "StandActive" 4 "Active Control" 3 "Ready" 2 "Reject" 1 "Failure" 0 "Off" ;
VAL_ 2566860163 ADCU3A_LKASSnvtySetSt 3 "Reserved" 2 "Low Sensitivity" 1 "High Sensitivity" 0 "Normal" ;
VAL_ 2566860163 ADCU3A_LKASFctStLamp 15 "Reserved" 14 "Reserved" 13 "Reserved" 12 "Reserved" 11 "Reserved" 10 "Reserved" 9 "Reserved" 8 "Reserved" 7 "LKAS Fail" 6 "LKA Right Active" 5 "LKA Left Active" 4 "LDW Right Active" 3 "LDW Left Active" 2 "LKAS Ready" 1 "LKAS Reject" 0 "LKAS Off" ;
VAL_ 2566860163 ADCU3A_LKASVoiWarn 1 "Warning" 0 "No Warning" ;
VAL_ 2566860163 ADCU3A_ACCFctRmn 15 "Reserved" 14 "Reserved" 13 "Reserved" 12 "Reserved" 11 "Reserved" 10 "ACC Function Degraded" 9 "Out of Operational Design Domain" 8 "ACC Function Override" 7 "ACC Function Standwait" 6 "ACC Function Failure" 5 "ACC Function Active" 4 "ACC Function Cancel" 3 "Take Over Request" 2 "Object too Near" 1 "ACC Function Not Active" 0 "No Display" ;
VAL_ 2566860163 ADCU3A_ACCFctLamp 7 "Reserved" 6 "Reserved" 5 "Reserved" 4 "Failure" 3 "Active" 2 "Ready" 1 "Reject" 0 "Off" ;
VAL_ 2566860163 ADCU3A_HndOnWarn 7 "Reserved" 6 "Reserved" 5 "Reserved" 4 "Level 4 Warning" 3 "Level 3 Warning" 2 "Level 2 Warning" 1 "Level 1 Warning" 0 "No Warning" ;
VAL_ 692 ADCU3A_AEBWrkSt 7 "Reserved" 6 "Reserved" 5 "Reserved" 4 "Reserved" 3 "fault" 2 "Active" 1 "Stand by" 0 "Off" ;
VAL_ 692 ADCU3A_FwdCllsnPrevnSwtSt 1 "On" 0 "Off" ;
VAL_ 692 ADCU3A_FwdCllsnPrevnMdSwtSt 1 "AEB On" 0 "FCW On" ;
VAL_ 692 ADCU3A_FwdCllsnPrevnSnvtySetSt 3 "Reserved" 2 "low Sensitivity" 1 "High Sensitivity" 0 "Normal" ;
VAL_ 692 ADCU3A_FCWAEBWarnLvl 3 "Warning Level 3" 2 "Warning Level 2" 1 "Warning Level 1" 0 "No Warning" ;
VAL_ 692 ADCU3A_FCWWrkSt 7 "Reserved" 6 "Reserved" 5 "Reserved" 4 "Reserved" 3 "fault" 2 "Active" 1 "Stand by" 0 "Off" ;
VAL_ 692 ADCU3A_AEBTrgType 3 "Reserved" 2 "EBA Trigger" 1 "AEB Trigger" 0 "No Trigger" ;
VAL_ 692 ADCU3A_AEBTypeTar 7 "Reserved" 6 "Reserved" 5 "Reserved" 4 "others" 3 "Bicycle" 2 "Pedestrian" 1 "Vehicle" 0 "No target" ;
VAL_ 692 ADCU3A_AEBRelDst 4095 "Invalid value" ;
VAL_ 692 ADCU3A_AEBRelSpd 1023 "Invalid value" ;
VAL_ 692 ADCU3A_AEBTTC 255 "Invalid value" ;
VAL_ 692 ADCU3A_FwdCllsnPrevnStLamp 7 "Reserved" 6 "Reserved" 5 "fault" 4 "AEB Active" 3 "FCW Ative" 2 "Ready" 1 "Reject" 0 "Off" ;
VAL_ 692 ADCU3A_FwdCllsnPrevnTstMsg 7 "Reserved" 6 "Reserved" 5 "Reserved" 4 "Reserved" 3 "Reserved" 2 "AEB Off" 1 "AEB On" 0 "No toast" ;
VAL_ 692 ADCU3A_NightVisnSwtSt 1 "On" 0 "Off" ;
VAL_ 692 ADCU3A_NightVisnWarnMod 3 "Reserved" 2 "Pedestrian and Animal Warning" 1 "Pedestrian Warning" 0 "No Warning" ;
VAL_ 692 ADCU3A_NightVisnFctWarn 7 "Reserved" 6 "Reserved" 5 "Reserved" 4 "Animal Collision Warning Level 2" 3 "Animal Collision Warning Level 1" 2 "Pedestrian Collision Warning Level 2" 1 "Pedestrian Collision Warning Level 1" 0 "No Warning" ;
VAL_ 692 ADCU3A_NightVisnFctFlt 1 "Fault" 0 "Normal" ;
VAL_ 1139 ADCU3A_ADCU1Err 3 "Reserved" 2 "Reserved" 1 "Failure" 0 "Normal" ;
VAL_ 1139 ADCU3A_ADCU2Err 3 "Reserved" 2 "Reserved" 1 "Failure" 0 "Normal" ;
VAL_ 1139 ADCU3A_ADCU3Err 3 "Reserved" 2 "Reserved" 1 "Failure" 0 "Normal" ;
VAL_ 1139 ADCU3A_FrInfraredCamErr 3 "Reserved" 2 "Obstruct" 1 "Failure" 0 "Normal" ;
VAL_ 1139 ADCU3A_FrRadarErr 7 "Reserved" 6 "Reserved" 5 "Failure in Vertical" 4 "Failure in Horizontal" 3 "Calibration Missing Or Failure" 2 "Obstruct" 1 "Failure" 0 "Normal" ;
VAL_ 1139 ADCU3A_LFCornrRadarErr 7 "Reserved" 6 "Reserved" 5 "Failure in Vertical" 4 "Failure in Horizontal" 3 "Calibration Missing Or Failure" 2 "Obstruct" 1 "Failure" 0 "Normal" ;
VAL_ 1139 ADCU3A_RFCornrRadarErr 7 "Reserved" 6 "Reserved" 5 "Failure in Vertical" 4 "Failure in Horizontal" 3 "Calibration Missing Or Failure" 2 "Obstruct" 1 "Failure" 0 "Normal" ;
VAL_ 1139 ADCU3A_LRCornrRadarErr 7 "Reserved" 6 "Reserved" 5 "Failure in Vertical" 4 "Failure in Horizontal" 3 "Calibration Missing Or Failure" 2 "Obstruct" 1 "Failure" 0 "Normal" ;
VAL_ 1139 ADCU3A_RRCornrRadarErr 7 "Reserved" 6 "Reserved" 5 "Failure in Vertical" 4 "Failure in Horizontal" 3 "Calibration Missing Or Failure" 2 "Obstruct" 1 "Failure" 0 "Normal" ;
VAL_ 1139 ADCU3A_LFSideViewCamErr 3 "Reserved" 2 "Obstruct" 1 "Failure" 0 "Normal" ;
VAL_ 1139 ADCU3A_RFSideViewCamErr 3 "Reserved" 2 "Obstruct" 1 "Failure" 0 "Normal" ;
VAL_ 1139 ADCU3A_LRSideViewCamErr 3 "Reserved" 2 "Obstruct" 1 "Failure" 0 "Normal" ;
VAL_ 1139 ADCU3A_RRSideViewCamErr 3 "Reserved" 2 "Obstruct" 1 "Failure" 0 "Normal" ;
VAL_ 1139 ADCU3A_FrSurrndViewCamErr 3 "Reserved" 2 "Obstruct" 1 "Failure" 0 "Normal" ;
VAL_ 1139 ADCU3A_LFSurrndViewCamErr 3 "Reserved" 2 "Obstruct" 1 "Failure" 0 "Normal" ;
VAL_ 1139 ADCU3A_RFSurrndViewCamErr 3 "Reserved" 2 "Obstruct" 1 "Failure" 0 "Normal" ;
VAL_ 1139 ADCU3A_FrLidarErr 3 "Reserved" 2 "Obstruct" 1 "Failure" 0 "Normal" ;
VAL_ 1139 ADCU3A_FrIntelgtCamErr 7 "Reserved" 6 "Reserved" 5 "Reserved" 4 "Reserved" 3 "Calibration Missing Or Failure" 2 "Obstruct" 1 "Failure" 0 "Normal" ;
VAL_ 1139 ADCU3A_FrLongFocusCamErr 3 "Reserved" 2 "Obstruct" 1 "Failure" 0 "Normal" ;
VAL_ 1139 ADCU3A_FrMidFocusCamErr 3 "Reserved" 2 "Obstruct" 1 "Failure" 0 "Normal" ;
VAL_ 1139 ADCU3A_FrshrtFocusCamErr 3 "Reserved" 2 "Obstruct" 1 "Failure" 0 "Normal" ;
VAL_ 2566869123 ADCU3A_LgtdCtrlReq 7 "Failure" 6 "Reserved" 5 "Reserved" 4 "Reserved" 3 "Reserved" 2 "L3" 1 "L2 and Below" 0 "Disabled" ;
VAL_ 2566869123 ADCU3A_PrkgBrkReq 3 "Not Available" 2 "Error" 1 "Request" 0 "No Request" ;
VAL_ 2566869123 ADCU3A_LgtdCtrlTarTqReq 1 "Request" 0 "No Request" ;
VAL_ 2566869123 ADCU3A_AEBActvSt 1 "Active" 0 "Inactive" ;
VAL_ 2566869123 ADCU3A_TmpStopReq 1 "Request" 0 "Not Request" ;
VAL_ 2566869123 ADCU3A_TarGearReq 15 "Invalid" 14 "Invalid" 13 "Invalid" 12 "Invalid" 11 "Invalid" 10 "Invalid" 9 "Invalid" 8 "Invalid" 7 "Invalid" 6 "Invalid" 5 "Invalid" 4 "D" 3 "N" 2 "R" 1 "Reserved" 0 "No Request" ;
VAL_ 2566869123 ADCU3A_LgtdCtrl_AC 15 "Error" ;
VAL_ 2566877827 ADCU3A_EPBCtrl_AC 15 "Error" ;
VAL_ 2566869138 ADCU3B_LgtdCtrlReq 7 "Failure" 6 "Reserved" 5 "Reserved" 4 "Reserved" 3 "Reserved" 2 "L3" 1 "L2 and Below" 0 "Disabled" ;
VAL_ 2566869138 ADCU3B_PrkgBrkReq 3 "Not Available" 2 "Error" 1 "Request" 0 "No Request" ;
VAL_ 2566869138 ADCU3B_LgtdCtrlTarTqReq 1 "Request" 0 "No Request" ;
VAL_ 2566869138 ADCU3B_AEBActvSt 1 "Active" 0 "Inactive" ;
VAL_ 2566869138 ADCU3B_TmpStopReq 1 "Request" 0 "Not Request" ;
VAL_ 2566869138 ADCU3B_TarGearReq 15 "Invalid" 14 "Invalid" 13 "Invalid" 12 "Invalid" 11 "Invalid" 10 "Invalid" 9 "Invalid" 8 "Invalid" 7 "Invalid" 6 "Invalid" 5 "Invalid" 4 "D" 3 "N" 2 "R" 1 "Reserved" 0 "No Request" ;
VAL_ 2566869138 ADCU3B_LgtdCtrl_AC 15 "Error" ;
VAL_ 2566877842 ADCU3B_EPBCtrl_AC 15 "Error" ;
VAL_ 2566860675 ADCU3A_LeftTurnLgtReq 3 "Reserved" 2 "ON" 1 "OFF" 0 "No Request" ;
VAL_ 2566860675 ADCU3A_RightTurnLgtReq 3 "Reserved" 2 "ON" 1 "OFF" 0 "No Request" ;
VAL_ 2566860675 ADCU3A_HzrdLgtReq 3 "Reserved" 2 "ON" 1 "OFF" 0 "No Request" ;
VAL_ 2566860675 ADCU3A_LoLgtReq 3 "Reserved" 2 "Reserved" 1 "On" 0 "Off" ;
VAL_ 2566860675 ADCU3A_OvtkLgtReq 3 "Reserved" 2 "Reserved" 1 "Request" 0 "No Request" ;
VAL_ 2566860675 ADCU3A_SteerWhlVibrnReq 3 "Reserved" 2 "Request Level2" 1 "Request Level1" 0 "No Request" ;
VAL_ 2566860675 ADCU3A_DrvrSeatVibrnReq 3 "Reserved" 2 "Reserved" 1 "Request" 0 "No Request" ;
VAL_ 2566860675 ADCU3A_ClrCamReq 3 "Reserved" 2 "Reserved" 1 "Request" 0 "No Request" ;
VAL_ 2566860675 ADCU3A_ClrLidarReq 3 "Reserved" 2 "Reserved" 1 "Request" 0 "No Request" ;
VAL_ 2566860675 ADCU3A_DrvrSbltTightenUpReq 3 "Reserved" 2 "Reserved" 1 "Request" 0 "No Request" ;
VAL_ 2566860675 ADCU3A_PsngerSbltTightenUpReq 3 "Reserved" 2 "Reserved" 1 "Request" 0 "No Request" ;
VAL_ 2566860675 ADCU3A_WhistleReq 3 "Reseved" 2 "Air Horn Request" 1 "Electric Horn Request" 0 "No Request" ;
VAL_ 2566860675 ADCU3A_WindwClsdReq 3 "Reserved" 2 "Reserved" 1 "Request" 0 "No Request" ;
VAL_ 2566860675 ADCU3A_VehLockdReq 3 "Reseved" 2 "Unlock" 1 "Lock" 0 "No Request" ;
VAL_ 2566860675 ADCU3A_MCUAErr 1 "Warning" 0 "No Warning" ;
VAL_ 2566860675 ADCU3A_DrvgAutoGrd 7 "Resered" 6 "Level 5 Driving Automation" 5 "Level 4 Driving Automation" 4 "Level 3 Driving Automation" 3 "Level 2 Driving Automation" 2 "Level 1 Driving Automation" 1 "Level 0 Driving Automation" 0 "No HIS" ;
VAL_ 2566860690 ADCU3B_LeftTurnLgtReq 3 "Reserved" 2 "ON" 1 "OFF" 0 "No Request" ;
VAL_ 2566860690 ADCU3B_RightTurnLgtReq 3 "Reserved" 2 "ON" 1 "OFF" 0 "No Request" ;
VAL_ 2566860690 ADCU3B_HzrdLgtReq 3 "Reserved" 2 "ON" 1 "OFF" 0 "No Request" ;
VAL_ 2566860690 ADCU3B_LoLgtReq 3 "Reserved" 2 "Reserved" 1 "ON" 0 "OFF" ;
VAL_ 2566860690 ADCU3B_OvtkLgtReq 3 "Reserved" 2 "Reserved" 1 "Request" 0 "No Request" ;
VAL_ 2566860690 ADCU3B_DrvrSeatVibrnReq 3 "Reserved" 2 "Reserved" 1 "Request" 0 "No Request" ;
VAL_ 2566860690 ADCU3B_ClrCamReq 3 "Reserved" 2 "Reserved" 1 "Request" 0 "No Request" ;
VAL_ 2566860690 ADCU3B_ClrLidarReq 3 "Reserved" 2 "Reserved" 1 "Request" 0 "No Request" ;
VAL_ 2566860690 ADCU3B_DrvrSbltTightenUpReq 3 "Reserved" 2 "Reserved" 1 "Request" 0 "No Request" ;
VAL_ 2566860690 ADCU3B_PsngerSbltTightenUpReq 3 "Reserved" 2 "Reserved" 1 "Request" 0 "No Request" ;
VAL_ 2566860690 ADCU3B_WhistleReq 3 "Reseved" 2 "Air Horn Request" 1 "Electric Horn Request" 0 "No Request" ;
VAL_ 2566860690 ADCU3B_WindwClsdReq 3 "Reserved" 2 "Reserved" 1 "Request" 0 "No Request" ;
VAL_ 2566860690 ADCU3B_VehLockdReq 3 "Reseved" 2 "Unlock" 1 "Lock" 0 "No Request" ;
VAL_ 2566860690 ADCU3B_MCUBErr 1 "Warning" 0 "No Warning" ;
VAL_ 2566860690 ADCU3B_DrvgAutoGrd 7 "Reseeved" 6 "Level 5 Driving Atuomation" 5 "Level 4 Driving Atuomation" 4 "Level 3 Driving Atuomation" 3 "Level 2 Driving Atuomation" 2 "Level 1 Driving Atuomation" 1 "Level 0 Driving Atuomation" 0 "No HIS" ;
VAL_ 2566850691 ADCU3A_LatCtrlSt 7 "Failure" 6 "Reserved" 5 "Reserved" 4 "Reserved" 3 "HWP Request" 2 "ESA Request" 1 "LKA Request" 0 "No Request" ;
VAL_ 2566850691 ADCU3A_AngCmdReqValVld 1 "valid" 0 "Invalid" ;
VAL_ 2566850706 ADCU3B_LatCtrlSt 7 "Failure" 6 "Reserved" 5 "Reserved" 4 "Reserved" 3 "HWP Request" 2 "ESA Request" 1 "LKA Request" 0 "No Request" ;
VAL_ 2566850706 ADCU3B_AngCmdReqValVld 1 "valid" 0 "Invalid" ;
VAL_ 2349075242 ADCU3A_EBIMode 3 "Not defined" 2 "Endurance Brake Integration allowed" 1 "Only Endurance Brakes allowed" 0 "No Endurance Brake Integration allowed" ;
VAL_ 2349075242 ADCU3A_XBRPrio 3 "Low" 2 "Medium" 1 "High" 0 "Highest" ;
VAL_ 2349075242 ADCU3A_XBRCtrlMod 3 "Not Available" 2 "Maximum Mode" 1 "Addition Mode" 0 "Override Disabled" ;
VAL_ 563 ADCU3A_LgtdAccl 4095 "Invalid" 3000 "Value" 2999 "Value" 2998 "Value" 2997 "Value" 2996 "Value" 2995 "Value" 2994 "Value" 2993 "Value" 2992 "Value" 2991 "Value" 2990 "Value" 2989 "Value" 2988 "Value" 2987 "Value" 2986 "Value" 2985 "Value" 2984 "Value" 2983 "Value" 2982 "Value" 2981 "Value" 2980 "Value" 2979 "Value" 2978 "Value" 2977 "Value" 2976 "Value" 2975 "Value" 2974 "Value" 2973 "Value" 2972 "Value" 2971 "Value" 2970 "Value" 2969 "Value" 2968 "Value" 2967 "Value" 2966 "Value" 2965 "Value" 2964 "Value" 2963 "Value" 2962 "Value" 2961 "Value" 2960 "Value" 2959 "Value" 2958 "Value" 2957 "Value" 2956 "Value" 2955 "Value" 2954 "Value" 2953 "Value" 2952 "Value" 2951 "Value" 2950 "Value" 2949 "Value" 2948 "Value" 2947 "Value" 2946 "Value" 2945 "Value" 2944 "Value" 2943 "Value" 2942 "Value" 2941 "Value" 2940 "Value" 2939 "Value" 2938 "Value" 2937 "Value" 2936 "Value" 2935 "Value" 2934 "Value" 2933 "Value" 2932 "Value" 2931 "Value" 2930 "Value" 2929 "Value" 2928 "Value" 2927 "Value" 2926 "Value" 2925 "Value" 2924 "Value" 2923 "Value" 2922 "Value" 2921 "Value" 2920 "Value" 2919 "Value" 2918 "Value" 2917 "Value" 2916 "Value" 2915 "Value" 2914 "Value" 2913 "Value" 2912 "Value" 2911 "Value" 2910 "Value" 2909 "Value" 2908 "Value" 2907 "Value" 2906 "Value" 2905 "Value" 2904 "Value" 2903 "Value" 2902 "Value" 2901 "Value" 2900 "Value" 2899 "Value" 2898 "Value" 2897 "Value" 2896 "Value" 2895 "Value" 2894 "Value" 2893 "Value" 2892 "Value" 2891 "Value" 2890 "Value" 2889 "Value" 2888 "Value" 2887 "Value" 2886 "Value" 2885 "Value" 2884 "Value" 2883 "Value" 2882 "Value" 2881 "Value" 2880 "Value" 2879 "Value" 2878 "Value" 2877 "Value" 2876 "Value" 2875 "Value" 2874 "Value" 2873 "Value" 2872 "Value" 2871 "Value" 2870 "Value" 2869 "Value" 2868 "Value" 2867 "Value" 2866 "Value" 2865 "Value" 2864 "Value" 2863 "Value" 2862 "Value" 2861 "Value" 2860 "Value" 2859 "Value" 2858 "Value" 2857 "Value" 2856 "Value" 2855 "Value" 2854 "Value" 2853 "Value" 2852 "Value" 2851 "Value" 2850 "Value" 2849 "Value" 2848 "Value" 2847 "Value" 2846 "Value" 2845 "Value" 2844 "Value" 2843 "Value" 2842 "Value" 2841 "Value" 2840 "Value" 2839 "Value" 2838 "Value" 2837 "Value" 2836 "Value" 2835 "Value" 2834 "Value" 2833 "Value" 2832 "Value" 2831 "Value" 2830 "Value" 2829 "Value" 2828 "Value" 2827 "Value" 2826 "Value" 2825 "Value" 2824 "Value" 2823 "Value" 2822 "Value" 2821 "Value" 2820 "Value" 2819 "Value" 2818 "Value" 2817 "Value" 2816 "Value" 2815 "Value" 2814 "Value" 2813 "Value" 2812 "Value" 2811 "Value" 2810 "Value" 2809 "Value" 2808 "Value" 2807 "Value" 2806 "Value" 2805 "Value" 2804 "Value" 2803 "Value" 2802 "Value" 2801 "Value" 2800 "Value" 2799 "Value" 2798 "Value" 2797 "Value" 2796 "Value" 2795 "Value" 2794 "Value" 2793 "Value" 2792 "Value" 2791 "Value" 2790 "Value" 2789 "Value" 2788 "Value" 2787 "Value" 2786 "Value" 2785 "Value" 2784 "Value" 2783 "Value" 2782 "Value" 2781 "Value" 2780 "Value" 2779 "Value" 2778 "Value" 2777 "Value" 2776 "Value" 2775 "Value" 2774 "Value" 2773 "Value" 2772 "Value" 2771 "Value" 2770 "Value" 2769 "Value" 2768 "Value" 2767 "Value" 2766 "Value" 2765 "Value" 2764 "Value" 2763 "Value" 2762 "Value" 2761 "Value" 2760 "Value" 2759 "Value" 2758 "Value" 2757 "Value" 2756 "Value" 2755 "Value" 2754 "Value" 2753 "Value" 2752 "Value" 2751 "Value" 2750 "Value" 2749 "Value" 2748 "Value" 2747 "Value" 2746 "Value" 2745 "Value" 2744 "Value" 2743 "Value" 2742 "Value" 2741 "Value" 2740 "Value" 2739 "Value" 2738 "Value" 2737 "Value" 2736 "Value" 2735 "Value" 2734 "Value" 2733 "Value" 2732 "Value" 2731 "Value" 2730 "Value" 2729 "Value" 2728 "Value" 2727 "Value" 2726 "Value" 2725 "Value" 2724 "Value" 2723 "Value" 2722 "Value" 2721 "Value" 2720 "Value" 2719 "Value" 2718 "Value" 2717 "Value" 2716 "Value" 2715 "Value" 2714 "Value" 2713 "Value" 2712 "Value" 2711 "Value" 2710 "Value" 2709 "Value" 2708 "Value" 2707 "Value" 2706 "Value" 2705 "Value" 2704 "Value" 2703 "Value" 2702 "Value" 2701 "Value" 2700 "Value" 2699 "Value" 2698 "Value" 2697 "Value" 2696 "Value" 2695 "Value" 2694 "Value" 2693 "Value" 2692 "Value" 2691 "Value" 2690 "Value" 2689 "Value" 2688 "Value" 2687 "Value" 2686 "Value" 2685 "Value" 2684 "Value" 2683 "Value" 2682 "Value" 2681 "Value" 2680 "Value" 2679 "Value" 2678 "Value" 2677 "Value" 2676 "Value" 2675 "Value" 2674 "Value" 2673 "Value" 2672 "Value" 2671 "Value" 2670 "Value" 2669 "Value" 2668 "Value" 2667 "Value" 2666 "Value" 2665 "Value" 2664 "Value" 2663 "Value" 2662 "Value" 2661 "Value" 2660 "Value" 2659 "Value" 2658 "Value" 2657 "Value" 2656 "Value" 2655 "Value" 2654 "Value" 2653 "Value" 2652 "Value" 2651 "Value" 2650 "Value" 2649 "Value" 2648 "Value" 2647 "Value" 2646 "Value" 2645 "Value" 2644 "Value" 2643 "Value" 2642 "Value" 2641 "Value" 2640 "Value" 2639 "Value" 2638 "Value" 2637 "Value" 2636 "Value" 2635 "Value" 2634 "Value" 2633 "Value" 2632 "Value" 2631 "Value" 2630 "Value" 2629 "Value" 2628 "Value" 2627 "Value" 2626 "Value" 2625 "Value" 2624 "Value" 2623 "Value" 2622 "Value" 2621 "Value" 2620 "Value" 2619 "Value" 2618 "Value" 2617 "Value" 2616 "Value" 2615 "Value" 2614 "Value" 2613 "Value" 2612 "Value" 2611 "Value" 2610 "Value" 2609 "Value" 2608 "Value" 2607 "Value" 2606 "Value" 2605 "Value" 2604 "Value" 2603 "Value" 2602 "Value" 2601 "Value" 2600 "Value" 2599 "Value" 2598 "Value" 2597 "Value" 2596 "Value" 2595 "Value" 2594 "Value" 2593 "Value" 2592 "Value" 2591 "Value" 2590 "Value" 2589 "Value" 2588 "Value" 2587 "Value" 2586 "Value" 2585 "Value" 2584 "Value" 2583 "Value" 2582 "Value" 2581 "Value" 2580 "Value" 2579 "Value" 2578 "Value" 2577 "Value" 2576 "Value" 2575 "Value" 2574 "Value" 2573 "Value" 2572 "Value" 2571 "Value" 2570 "Value" 2569 "Value" 2568 "Value" 2567 "Value" 2566 "Value" 2565 "Value" 2564 "Value" 2563 "Value" 2562 "Value" 2561 "Value" 2560 "Value" 2559 "Value" 2558 "Value" 2557 "Value" 2556 "Value" 2555 "Value" 2554 "Value" 2553 "Value" 2552 "Value" 2551 "Value" 2550 "Value" 2549 "Value" 2548 "Value" 2547 "Value" 2546 "Value" 2545 "Value" 2544 "Value" 2543 "Value" 2542 "Value" 2541 "Value" 2540 "Value" 2539 "Value" 2538 "Value" 2537 "Value" 2536 "Value" 2535 "Value" 2534 "Value" 2533 "Value" 2532 "Value" 2531 "Value" 2530 "Value" 2529 "Value" 2528 "Value" 2527 "Value" 2526 "Value" 2525 "Value" 2524 "Value" 2523 "Value" 2522 "Value" 2521 "Value" 2520 "Value" 2519 "Value" 2518 "Value" 2517 "Value" 2516 "Value" 2515 "Value" 2514 "Value" 2513 "Value" 2512 "Value" 2511 "Value" 2510 "Value" 2509 "Value" 2508 "Value" 2507 "Value" 2506 "Value" 2505 "Value" 2504 "Value" 2503 "Value" 2502 "Value" 2501 "Value" 2500 "Value" 2499 "Value" 2498 "Value" 2497 "Value" 2496 "Value" 2495 "Value" 2494 "Value" 2493 "Value" 2492 "Value" 2491 "Value" 2490 "Value" 2489 "Value" 2488 "Value" 2487 "Value" 2486 "Value" 2485 "Value" 2484 "Value" 2483 "Value" 2482 "Value" 2481 "Value" 2480 "Value" 2479 "Value" 2478 "Value" 2477 "Value" 2476 "Value" 2475 "Value" 2474 "Value" 2473 "Value" 2472 "Value" 2471 "Value" 2470 "Value" 2469 "Value" 2468 "Value" 2467 "Value" 2466 "Value" 2465 "Value" 2464 "Value" 2463 "Value" 2462 "Value" 2461 "Value" 2460 "Value" 2459 "Value" 2458 "Value" 2457 "Value" 2456 "Value" 2455 "Value" 2454 "Value" 2453 "Value" 2452 "Value" 2451 "Value" 2450 "Value" 2449 "Value" 2448 "Value" 2447 "Value" 2446 "Value" 2445 "Value" 2444 "Value" 2443 "Value" 2442 "Value" 2441 "Value" 2440 "Value" 2439 "Value" 2438 "Value" 2437 "Value" 2436 "Value" 2435 "Value" 2434 "Value" 2433 "Value" 2432 "Value" 2431 "Value" 2430 "Value" 2429 "Value" 2428 "Value" 2427 "Value" 2426 "Value" 2425 "Value" 2424 "Value" 2423 "Value" 2422 "Value" 2421 "Value" 2420 "Value" 2419 "Value" 2418 "Value" 2417 "Value" 2416 "Value" 2415 "Value" 2414 "Value" 2413 "Value" 2412 "Value" 2411 "Value" 2410 "Value" 2409 "Value" 2408 "Value" 2407 "Value" 2406 "Value" 2405 "Value" 2404 "Value" 2403 "Value" 2402 "Value" 2401 "Value" 2400 "Value" 2399 "Value" 2398 "Value" 2397 "Value" 2396 "Value" 2395 "Value" 2394 "Value" 2393 "Value" 2392 "Value" 2391 "Value" 2390 "Value" 2389 "Value" 2388 "Value" 2387 "Value" 2386 "Value" 2385 "Value" 2384 "Value" 2383 "Value" 2382 "Value" 2381 "Value" 2380 "Value" 2379 "Value" 2378 "Value" 2377 "Value" 2376 "Value" 2375 "Value" 2374 "Value" 2373 "Value" 2372 "Value" 2371 "Value" 2370 "Value" 2369 "Value" 2368 "Value" 2367 "Value" 2366 "Value" 2365 "Value" 2364 "Value" 2363 "Value" 2362 "Value" 2361 "Value" 2360 "Value" 2359 "Value" 2358 "Value" 2357 "Value" 2356 "Value" 2355 "Value" 2354 "Value" 2353 "Value" 2352 "Value" 2351 "Value" 2350 "Value" 2349 "Value" 2348 "Value" 2347 "Value" 2346 "Value" 2345 "Value" 2344 "Value" 2343 "Value" 2342 "Value" 2341 "Value" 2340 "Value" 2339 "Value" 2338 "Value" 2337 "Value" 2336 "Value" 2335 "Value" 2334 "Value" 2333 "Value" 2332 "Value" 2331 "Value" 2330 "Value" 2329 "Value" 2328 "Value" 2327 "Value" 2326 "Value" 2325 "Value" 2324 "Value" 2323 "Value" 2322 "Value" 2321 "Value" 2320 "Value" 2319 "Value" 2318 "Value" 2317 "Value" 2316 "Value" 2315 "Value" 2314 "Value" 2313 "Value" 2312 "Value" 2311 "Value" 2310 "Value" 2309 "Value" 2308 "Value" 2307 "Value" 2306 "Value" 2305 "Value" 2304 "Value" 2303 "Value" 2302 "Value" 2301 "Value" 2300 "Value" 2299 "Value" 2298 "Value" 2297 "Value" 2296 "Value" 2295 "Value" 2294 "Value" 2293 "Value" 2292 "Value" 2291 "Value" 2290 "Value" 2289 "Value" 2288 "Value" 2287 "Value" 2286 "Value" 2285 "Value" 2284 "Value" 2283 "Value" 2282 "Value" 2281 "Value" 2280 "Value" 2279 "Value" 2278 "Value" 2277 "Value" 2276 "Value" 2275 "Value" 2274 "Value" 2273 "Value" 2272 "Value" 2271 "Value" 2270 "Value" 2269 "Value" 2268 "Value" 2267 "Value" 2266 "Value" 2265 "Value" 2264 "Value" 2263 "Value" 2262 "Value" 2261 "Value" 2260 "Value" 2259 "Value" 2258 "Value" 2257 "Value" 2256 "Value" 2255 "Value" 2254 "Value" 2253 "Value" 2252 "Value" 2251 "Value" 2250 "Value" 2249 "Value" 2248 "Value" 2247 "Value" 2246 "Value" 2245 "Value" 2244 "Value" 2243 "Value" 2242 "Value" 2241 "Value" 2240 "Value" 2239 "Value" 2238 "Value" 2237 "Value" 2236 "Value" 2235 "Value" 2234 "Value" 2233 "Value" 2232 "Value" 2231 "Value" 2230 "Value" 2229 "Value" 2228 "Value" 2227 "Value" 2226 "Value" 2225 "Value" 2224 "Value" 2223 "Value" 2222 "Value" 2221 "Value" 2220 "Value" 2219 "Value" 2218 "Value" 2217 "Value" 2216 "Value" 2215 "Value" 2214 "Value" 2213 "Value" 2212 "Value" 2211 "Value" 2210 "Value" 2209 "Value" 2208 "Value" 2207 "Value" 2206 "Value" 2205 "Value" 2204 "Value" 2203 "Value" 2202 "Value" 2201 "Value" 2200 "Value" 2199 "Value" 2198 "Value" 2197 "Value" 2196 "Value" 2195 "Value" 2194 "Value" 2193 "Value" 2192 "Value" 2191 "Value" 2190 "Value" 2189 "Value" 2188 "Value" 2187 "Value" 2186 "Value" 2185 "Value" 2184 "Value" 2183 "Value" 2182 "Value" 2181 "Value" 2180 "Value" 2179 "Value" 2178 "Value" 2177 "Value" 2176 "Value" 2175 "Value" 2174 "Value" 2173 "Value" 2172 "Value" 2171 "Value" 2170 "Value" 2169 "Value" 2168 "Value" 2167 "Value" 2166 "Value" 2165 "Value" 2164 "Value" 2163 "Value" 2162 "Value" 2161 "Value" 2160 "Value" 2159 "Value" 2158 "Value" 2157 "Value" 2156 "Value" 2155 "Value" 2154 "Value" 2153 "Value" 2152 "Value" 2151 "Value" 2150 "Value" 2149 "Value" 2148 "Value" 2147 "Value" 2146 "Value" 2145 "Value" 2144 "Value" 2143 "Value" 2142 "Value" 2141 "Value" 2140 "Value" 2139 "Value" 2138 "Value" 2137 "Value" 2136 "Value" 2135 "Value" 2134 "Value" 2133 "Value" 2132 "Value" 2131 "Value" 2130 "Value" 2129 "Value" 2128 "Value" 2127 "Value" 2126 "Value" 2125 "Value" 2124 "Value" 2123 "Value" 2122 "Value" 2121 "Value" 2120 "Value" 2119 "Value" 2118 "Value" 2117 "Value" 2116 "Value" 2115 "Value" 2114 "Value" 2113 "Value" 2112 "Value" 2111 "Value" 2110 "Value" 2109 "Value" 2108 "Value" 2107 "Value" 2106 "Value" 2105 "Value" 2104 "Value" 2103 "Value" 2102 "Value" 2101 "Value" 2100 "Value" 2099 "Value" 2098 "Value" 2097 "Value" 2096 "Value" 2095 "Value" 2094 "Value" 2093 "Value" 2092 "Value" 2091 "Value" 2090 "Value" 2089 "Value" 2088 "Value" 2087 "Value" 2086 "Value" 2085 "Value" 2084 "Value" 2083 "Value" 2082 "Value" 2081 "Value" 2080 "Value" 2079 "Value" 2078 "Value" 2077 "Value" 2076 "Value" 2075 "Value" 2074 "Value" 2073 "Value" 2072 "Value" 2071 "Value" 2070 "Value" 2069 "Value" 2068 "Value" 2067 "Value" 2066 "Value" 2065 "Value" 2064 "Value" 2063 "Value" 2062 "Value" 2061 "Value" 2060 "Value" 2059 "Value" 2058 "Value" 2057 "Value" 2056 "Value" 2055 "Value" 2054 "Value" 2053 "Value" 2052 "Value" 2051 "Value" 2050 "Value" 2049 "Value" 2048 "Value" 2047 "Value" 2046 "Value" 2045 "Value" 2044 "Value" 2043 "Value" 2042 "Value" 2041 "Value" 2040 "Value" 2039 "Value" 2038 "Value" 2037 "Value" 2036 "Value" 2035 "Value" 2034 "Value" 2033 "Value" 2032 "Value" 2031 "Value" 2030 "Value" 2029 "Value" 2028 "Value" 2027 "Value" 2026 "Value" 2025 "Value" 2024 "Value" 2023 "Value" 2022 "Value" 2021 "Value" 2020 "Value" 2019 "Value" 2018 "Value" 2017 "Value" 2016 "Value" 2015 "Value" 2014 "Value" 2013 "Value" 2012 "Value" 2011 "Value" 2010 "Value" 2009 "Value" 2008 "Value" 2007 "Value" 2006 "Value" 2005 "Value" 2004 "Value" 2003 "Value" 2002 "Value" 2001 "Value" 2000 "Value" 1999 "Value" 1998 "Value" 1997 "Value" 1996 "Value" 1995 "Value" 1994 "Value" 1993 "Value" 1992 "Value" 1991 "Value" 1990 "Value" 1989 "Value" 1988 "Value" 1987 "Value" 1986 "Value" 1985 "Value" 1984 "Value" 1983 "Value" 1982 "Value" 1981 "Value" 1980 "Value" 1979 "Value" 1978 "Value" 1977 "Value" 1976 "Value" 1975 "Value" 1974 "Value" 1973 "Value" 1972 "Value" 1971 "Value" 1970 "Value" 1969 "Value" 1968 "Value" 1967 "Value" 1966 "Value" 1965 "Value" 1964 "Value" 1963 "Value" 1962 "Value" 1961 "Value" 1960 "Value" 1959 "Value" 1958 "Value" 1957 "Value" 1956 "Value" 1955 "Value" 1954 "Value" 1953 "Value" 1952 "Value" 1951 "Value" 1950 "Value" 1949 "Value" 1948 "Value" 1947 "Value" 1946 "Value" 1945 "Value" 1944 "Value" 1943 "Value" 1942 "Value" 1941 "Value" 1940 "Value" 1939 "Value" 1938 "Value" 1937 "Value" 1936 "Value" 1935 "Value" 1934 "Value" 1933 "Value" 1932 "Value" 1931 "Value" 1930 "Value" 1929 "Value" 1928 "Value" 1927 "Value" 1926 "Value" 1925 "Value" 1924 "Value" 1923 "Value" 1922 "Value" 1921 "Value" 1920 "Value" 1919 "Value" 1918 "Value" 1917 "Value" 1916 "Value" 1915 "Value" 1914 "Value" 1913 "Value" 1912 "Value" 1911 "Value" 1910 "Value" 1909 "Value" 1908 "Value" 1907 "Value" 1906 "Value" 1905 "Value" 1904 "Value" 1903 "Value" 1902 "Value" 1901 "Value" 1900 "Value" 1899 "Value" 1898 "Value" 1897 "Value" 1896 "Value" 1895 "Value" 1894 "Value" 1893 "Value" 1892 "Value" 1891 "Value" 1890 "Value" 1889 "Value" 1888 "Value" 1887 "Value" 1886 "Value" 1885 "Value" 1884 "Value" 1883 "Value" 1882 "Value" 1881 "Value" 1880 "Value" 1879 "Value" 1878 "Value" 1877 "Value" 1876 "Value" 1875 "Value" 1874 "Value" 1873 "Value" 1872 "Value" 1871 "Value" 1870 "Value" 1869 "Value" 1868 "Value" 1867 "Value" 1866 "Value" 1865 "Value" 1864 "Value" 1863 "Value" 1862 "Value" 1861 "Value" 1860 "Value" 1859 "Value" 1858 "Value" 1857 "Value" 1856 "Value" 1855 "Value" 1854 "Value" 1853 "Value" 1852 "Value" 1851 "Value" 1850 "Value" 1849 "Value" 1848 "Value" 1847 "Value" 1846 "Value" 1845 "Value" 1844 "Value" 1843 "Value" 1842 "Value" 1841 "Value" 1840 "Value" 1839 "Value" 1838 "Value" 1837 "Value" 1836 "Value" 1835 "Value" 1834 "Value" 1833 "Value" 1832 "Value" 1831 "Value" 1830 "Value" 1829 "Value" 1828 "Value" 1827 "Value" 1826 "Value" 1825 "Value" 1824 "Value" 1823 "Value" 1822 "Value" 1821 "Value" 1820 "Value" 1819 "Value" 1818 "Value" 1817 "Value" 1816 "Value" 1815 "Value" 1814 "Value" 1813 "Value" 1812 "Value" 1811 "Value" 1810 "Value" 1809 "Value" 1808 "Value" 1807 "Value" 1806 "Value" 1805 "Value" 1804 "Value" 1803 "Value" 1802 "Value" 1801 "Value" 1800 "Value" 1799 "Value" 1798 "Value" 1797 "Value" 1796 "Value" 1795 "Value" 1794 "Value" 1793 "Value" 1792 "Value" 1791 "Value" 1790 "Value" 1789 "Value" 1788 "Value" 1787 "Value" 1786 "Value" 1785 "Value" 1784 "Value" 1783 "Value" 1782 "Value" 1781 "Value" 1780 "Value" 1779 "Value" 1778 "Value" 1777 "Value" 1776 "Value" 1775 "Value" 1774 "Value" 1773 "Value" 1772 "Value" 1771 "Value" 1770 "Value" 1769 "Value" 1768 "Value" 1767 "Value" 1766 "Value" 1765 "Value" 1764 "Value" 1763 "Value" 1762 "Value" 1761 "Value" 1760 "Value" 1759 "Value" 1758 "Value" 1757 "Value" 1756 "Value" 1755 "Value" 1754 "Value" 1753 "Value" 1752 "Value" 1751 "Value" 1750 "Value" 1749 "Value" 1748 "Value" 1747 "Value" 1746 "Value" 1745 "Value" 1744 "Value" 1743 "Value" 1742 "Value" 1741 "Value" 1740 "Value" 1739 "Value" 1738 "Value" 1737 "Value" 1736 "Value" 1735 "Value" 1734 "Value" 1733 "Value" 1732 "Value" 1731 "Value" 1730 "Value" 1729 "Value" 1728 "Value" 1727 "Value" 1726 "Value" 1725 "Value" 1724 "Value" 1723 "Value" 1722 "Value" 1721 "Value" 1720 "Value" 1719 "Value" 1718 "Value" 1717 "Value" 1716 "Value" 1715 "Value" 1714 "Value" 1713 "Value" 1712 "Value" 1711 "Value" 1710 "Value" 1709 "Value" 1708 "Value" 1707 "Value" 1706 "Value" 1705 "Value" 1704 "Value" 1703 "Value" 1702 "Value" 1701 "Value" 1700 "Value" 1699 "Value" 1698 "Value" 1697 "Value" 1696 "Value" 1695 "Value" 1694 "Value" 1693 "Value" 1692 "Value" 1691 "Value" 1690 "Value" 1689 "Value" 1688 "Value" 1687 "Value" 1686 "Value" 1685 "Value" 1684 "Value" 1683 "Value" 1682 "Value" 1681 "Value" 1680 "Value" 1679 "Value" 1678 "Value" 1677 "Value" 1676 "Value" 1675 "Value" 1674 "Value" 1673 "Value" 1672 "Value" 1671 "Value" 1670 "Value" 1669 "Value" 1668 "Value" 1667 "Value" 1666 "Value" 1665 "Value" 1664 "Value" 1663 "Value" 1662 "Value" 1661 "Value" 1660 "Value" 1659 "Value" 1658 "Value" 1657 "Value" 1656 "Value" 1655 "Value" 1654 "Value" 1653 "Value" 1652 "Value" 1651 "Value" 1650 "Value" 1649 "Value" 1648 "Value" 1647 "Value" 1646 "Value" 1645 "Value" 1644 "Value" 1643 "Value" 1642 "Value" 1641 "Value" 1640 "Value" 1639 "Value" 1638 "Value" 1637 "Value" 1636 "Value" 1635 "Value" 1634 "Value" 1633 "Value" 1632 "Value" 1631 "Value" 1630 "Value" 1629 "Value" 1628 "Value" 1627 "Value" 1626 "Value" 1625 "Value" 1624 "Value" 1623 "Value" 1622 "Value" 1621 "Value" 1620 "Value" 1619 "Value" 1618 "Value" 1617 "Value" 1616 "Value" 1615 "Value" 1614 "Value" 1613 "Value" 1612 "Value" 1611 "Value" 1610 "Value" 1609 "Value" 1608 "Value" 1607 "Value" 1606 "Value" 1605 "Value" 1604 "Value" 1603 "Value" 1602 "Value" 1601 "Value" 1600 "Value" 1599 "Value" 1598 "Value" 1597 "Value" 1596 "Value" 1595 "Value" 1594 "Value" 1593 "Value" 1592 "Value" 1591 "Value" 1590 "Value" 1589 "Value" 1588 "Value" 1587 "Value" 1586 "Value" 1585 "Value" 1584 "Value" 1583 "Value" 1582 "Value" 1581 "Value" 1580 "Value" 1579 "Value" 1578 "Value" 1577 "Value" 1576 "Value" 1575 "Value" 1574 "Value" 1573 "Value" 1572 "Value" 1571 "Value" 1570 "Value" 1569 "Value" 1568 "Value" 1567 "Value" 1566 "Value" 1565 "Value" 1564 "Value" 1563 "Value" 1562 "Value" 1561 "Value" 1560 "Value" 1559 "Value" 1558 "Value" 1557 "Value" 1556 "Value" 1555 "Value" 1554 "Value" 1553 "Value" 1552 "Value" 1551 "Value" 1550 "Value" 1549 "Value" 1548 "Value" 1547 "Value" 1546 "Value" 1545 "Value" 1544 "Value" 1543 "Value" 1542 "Value" 1541 "Value" 1540 "Value" 1539 "Value" 1538 "Value" 1537 "Value" 1536 "Value" 1535 "Value" 1534 "Value" 1533 "Value" 1532 "Value" 1531 "Value" 1530 "Value" 1529 "Value" 1528 "Value" 1527 "Value" 1526 "Value" 1525 "Value" 1524 "Value" 1523 "Value" 1522 "Value" 1521 "Value" 1520 "Value" 1519 "Value" 1518 "Value" 1517 "Value" 1516 "Value" 1515 "Value" 1514 "Value" 1513 "Value" 1512 "Value" 1511 "Value" 1510 "Value" 1509 "Value" 1508 "Value" 1507 "Value" 1506 "Value" 1505 "Value" 1504 "Value" 1503 "Value" 1502 "Value" 1501 "Value" 1500 "Value" 1499 "Value" 1498 "Value" 1497 "Value" 1496 "Value" 1495 "Value" 1494 "Value" 1493 "Value" 1492 "Value" 1491 "Value" 1490 "Value" 1489 "Value" 1488 "Value" 1487 "Value" 1486 "Value" 1485 "Value" 1484 "Value" 1483 "Value" 1482 "Value" 1481 "Value" 1480 "Value" 1479 "Value" 1478 "Value" 1477 "Value" 1476 "Value" 1475 "Value" 1474 "Value" 1473 "Value" 1472 "Value" 1471 "Value" 1470 "Value" 1469 "Value" 1468 "Value" 1467 "Value" 1466 "Value" 1465 "Value" 1464 "Value" 1463 "Value" 1462 "Value" 1461 "Value" 1460 "Value" 1459 "Value" 1458 "Value" 1457 "Value" 1456 "Value" 1455 "Value" 1454 "Value" 1453 "Value" 1452 "Value" 1451 "Value" 1450 "Value" 1449 "Value" 1448 "Value" 1447 "Value" 1446 "Value" 1445 "Value" 1444 "Value" 1443 "Value" 1442 "Value" 1441 "Value" 1440 "Value" 1439 "Value" 1438 "Value" 1437 "Value" 1436 "Value" 1435 "Value" 1434 "Value" 1433 "Value" 1432 "Value" 1431 "Value" 1430 "Value" 1429 "Value" 1428 "Value" 1427 "Value" 1426 "Value" 1425 "Value" 1424 "Value" 1423 "Value" 1422 "Value" 1421 "Value" 1420 "Value" 1419 "Value" 1418 "Value" 1417 "Value" 1416 "Value" 1415 "Value" 1414 "Value" 1413 "Value" 1412 "Value" 1411 "Value" 1410 "Value" 1409 "Value" 1408 "Value" 1407 "Value" 1406 "Value" 1405 "Value" 1404 "Value" 1403 "Value" 1402 "Value" 1401 "Value" 1400 "Value" 1399 "Value" 1398 "Value" 1397 "Value" 1396 "Value" 1395 "Value" 1394 "Value" 1393 "Value" 1392 "Value" 1391 "Value" 1390 "Value" 1389 "Value" 1388 "Value" 1387 "Value" 1386 "Value" 1385 "Value" 1384 "Value" 1383 "Value" 1382 "Value" 1381 "Value" 1380 "Value" 1379 "Value" 1378 "Value" 1377 "Value" 1376 "Value" 1375 "Value" 1374 "Value" 1373 "Value" 1372 "Value" 1371 "Value" 1370 "Value" 1369 "Value" 1368 "Value" 1367 "Value" 1366 "Value" 1365 "Value" 1364 "Value" 1363 "Value" 1362 "Value" 1361 "Value" 1360 "Value" 1359 "Value" 1358 "Value" 1357 "Value" 1356 "Value" 1355 "Value" 1354 "Value" 1353 "Value" 1352 "Value" 1351 "Value" 1350 "Value" 1349 "Value" 1348 "Value" 1347 "Value" 1346 "Value" 1345 "Value" 1344 "Value" 1343 "Value" 1342 "Value" 1341 "Value" 1340 "Value" 1339 "Value" 1338 "Value" 1337 "Value" 1336 "Value" 1335 "Value" 1334 "Value" 1333 "Value" 1332 "Value" 1331 "Value" 1330 "Value" 1329 "Value" 1328 "Value" 1327 "Value" 1326 "Value" 1325 "Value" 1324 "Value" 1323 "Value" 1322 "Value" 1321 "Value" 1320 "Value" 1319 "Value" 1318 "Value" 1317 "Value" 1316 "Value" 1315 "Value" 1314 "Value" 1313 "Value" 1312 "Value" 1311 "Value" 1310 "Value" 1309 "Value" 1308 "Value" 1307 "Value" 1306 "Value" 1305 "Value" 1304 "Value" 1303 "Value" 1302 "Value" 1301 "Value" 1300 "Value" 1299 "Value" 1298 "Value" 1297 "Value" 1296 "Value" 1295 "Value" 1294 "Value" 1293 "Value" 1292 "Value" 1291 "Value" 1290 "Value" 1289 "Value" 1288 "Value" 1287 "Value" 1286 "Value" 1285 "Value" 1284 "Value" 1283 "Value" 1282 "Value" 1281 "Value" 1280 "Value" 1279 "Value" 1278 "Value" 1277 "Value" 1276 "Value" 1275 "Value" 1274 "Value" 1273 "Value" 1272 "Value" 1271 "Value" 1270 "Value" 1269 "Value" 1268 "Value" 1267 "Value" 1266 "Value" 1265 "Value" 1264 "Value" 1263 "Value" 1262 "Value" 1261 "Value" 1260 "Value" 1259 "Value" 1258 "Value" 1257 "Value" 1256 "Value" 1255 "Value" 1254 "Value" 1253 "Value" 1252 "Value" 1251 "Value" 1250 "Value" 1249 "Value" 1248 "Value" 1247 "Value" 1246 "Value" 1245 "Value" 1244 "Value" 1243 "Value" 1242 "Value" 1241 "Value" 1240 "Value" 1239 "Value" 1238 "Value" 1237 "Value" 1236 "Value" 1235 "Value" 1234 "Value" 1233 "Value" 1232 "Value" 1231 "Value" 1230 "Value" 1229 "Value" 1228 "Value" 1227 "Value" 1226 "Value" 1225 "Value" 1224 "Value" 1223 "Value" 1222 "Value" 1221 "Value" 1220 "Value" 1219 "Value" 1218 "Value" 1217 "Value" 1216 "Value" 1215 "Value" 1214 "Value" 1213 "Value" 1212 "Value" 1211 "Value" 1210 "Value" 1209 "Value" 1208 "Value" 1207 "Value" 1206 "Value" 1205 "Value" 1204 "Value" 1203 "Value" 1202 "Value" 1201 "Value" 1200 "Value" 1199 "Value" 1198 "Value" 1197 "Value" 1196 "Value" 1195 "Value" 1194 "Value" 1193 "Value" 1192 "Value" 1191 "Value" 1190 "Value" 1189 "Value" 1188 "Value" 1187 "Value" 1186 "Value" 1185 "Value" 1184 "Value" 1183 "Value" 1182 "Value" 1181 "Value" 1180 "Value" 1179 "Value" 1178 "Value" 1177 "Value" 1176 "Value" 1175 "Value" 1174 "Value" 1173 "Value" 1172 "Value" 1171 "Value" 1170 "Value" 1169 "Value" 1168 "Value" 1167 "Value" 1166 "Value" 1165 "Value" 1164 "Value" 1163 "Value" 1162 "Value" 1161 "Value" 1160 "Value" 1159 "Value" 1158 "Value" 1157 "Value" 1156 "Value" 1155 "Value" 1154 "Value" 1153 "Value" 1152 "Value" 1151 "Value" 1150 "Value" 1149 "Value" 1148 "Value" 1147 "Value" 1146 "Value" 1145 "Value" 1144 "Value" 1143 "Value" 1142 "Value" 1141 "Value" 1140 "Value" 1139 "Value" 1138 "Value" 1137 "Value" 1136 "Value" 1135 "Value" 1134 "Value" 1133 "Value" 1132 "Value" 1131 "Value" 1130 "Value" 1129 "Value" 1128 "Value" 1127 "Value" 1126 "Value" 1125 "Value" 1124 "Value" 1123 "Value" 1122 "Value" 1121 "Value" 1120 "Value" 1119 "Value" 1118 "Value" 1117 "Value" 1116 "Value" 1115 "Value" 1114 "Value" 1113 "Value" 1112 "Value" 1111 "Value" 1110 "Value" 1109 "Value" 1108 "Value" 1107 "Value" 1106 "Value" 1105 "Value" 1104 "Value" 1103 "Value" 1102 "Value" 1101 "Value" 1100 "Value" 1099 "Value" 1098 "Value" 1097 "Value" 1096 "Value" 1095 "Value" 1094 "Value" 1093 "Value" 1092 "Value" 1091 "Value" 1090 "Value" 1089 "Value" 1088 "Value" 1087 "Value" 1086 "Value" 1085 "Value" 1084 "Value" 1083 "Value" 1082 "Value" 1081 "Value" 1080 "Value" 1079 "Value" 1078 "Value" 1077 "Value" 1076 "Value" 1075 "Value" 1074 "Value" 1073 "Value" 1072 "Value" 1071 "Value" 1070 "Value" 1069 "Value" 1068 "Value" 1067 "Value" 1066 "Value" 1065 "Value" 1064 "Value" 1063 "Value" 1062 "Value" 1061 "Value" 1060 "Value" 1059 "Value" 1058 "Value" 1057 "Value" 1056 "Value" 1055 "Value" 1054 "Value" 1053 "Value" 1052 "Value" 1051 "Value" 1050 "Value" 1049 "Value" 1048 "Value" 1047 "Value" 1046 "Value" 1045 "Value" 1044 "Value" 1043 "Value" 1042 "Value" 1041 "Value" 1040 "Value" 1039 "Value" 1038 "Value" 1037 "Value" 1036 "Value" 1035 "Value" 1034 "Value" 1033 "Value" 1032 "Value" 1031 "Value" 1030 "Value" 1029 "Value" 1028 "Value" 1027 "Value" 1026 "Value" 1025 "Value" 1024 "Value" 1023 "Value" 1022 "Value" 1021 "Value" 1020 "Value" 1019 "Value" 1018 "Value" 1017 "Value" 1016 "Value" 1015 "Value" 1014 "Value" 1013 "Value" 1012 "Value" 1011 "Value" 1010 "Value" 1009 "Value" 1008 "Value" 1007 "Value" 1006 "Value" 1005 "Value" 1004 "Value" 1003 "Value" 1002 "Value" 1001 "Value" 1000 "Value" 999 "Value" 998 "Value" 997 "Value" 996 "Value" 995 "Value" 994 "Value" 993 "Value" 992 "Value" 991 "Value" 990 "Value" 989 "Value" 988 "Value" 987 "Value" 986 "Value" 985 "Value" 984 "Value" 983 "Value" 982 "Value" 981 "Value" 980 "Value" 979 "Value" 978 "Value" 977 "Value" 976 "Value" 975 "Value" 974 "Value" 973 "Value" 972 "Value" 971 "Value" 970 "Value" 969 "Value" 968 "Value" 967 "Value" 966 "Value" 965 "Value" 964 "Value" 963 "Value" 962 "Value" 961 "Value" 960 "Value" 959 "Value" 958 "Value" 957 "Value" 956 "Value" 955 "Value" 954 "Value" 953 "Value" 952 "Value" 951 "Value" 950 "Value" 949 "Value" 948 "Value" 947 "Value" 946 "Value" 945 "Value" 944 "Value" 943 "Value" 942 "Value" 941 "Value" 940 "Value" 939 "Value" 938 "Value" 937 "Value" 936 "Value" 935 "Value" 934 "Value" 933 "Value" 932 "Value" 931 "Value" 930 "Value" 929 "Value" 928 "Value" 927 "Value" 926 "Value" 925 "Value" 924 "Value" 923 "Value" 922 "Value" 921 "Value" 920 "Value" 919 "Value" 918 "Value" 917 "Value" 916 "Value" 915 "Value" 914 "Value" 913 "Value" 912 "Value" 911 "Value" 910 "Value" 909 "Value" 908 "Value" 907 "Value" 906 "Value" 905 "Value" 904 "Value" 903 "Value" 902 "Value" 901 "Value" 900 "Value" 899 "Value" 898 "Value" 897 "Value" 896 "Value" 895 "Value" 894 "Value" 893 "Value" 892 "Value" 891 "Value" 890 "Value" 889 "Value" 888 "Value" 887 "Value" 886 "Value" 885 "Value" 884 "Value" 883 "Value" 882 "Value" 881 "Value" 880 "Value" 879 "Value" 878 "Value" 877 "Value" 876 "Value" 875 "Value" 874 "Value" 873 "Value" 872 "Value" 871 "Value" 870 "Value" 869 "Value" 868 "Value" 867 "Value" 866 "Value" 865 "Value" 864 "Value" 863 "Value" 862 "Value" 861 "Value" 860 "Value" 859 "Value" 858 "Value" 857 "Value" 856 "Value" 855 "Value" 854 "Value" 853 "Value" 852 "Value" 851 "Value" 850 "Value" 849 "Value" 848 "Value" 847 "Value" 846 "Value" 845 "Value" 844 "Value" 843 "Value" 842 "Value" 841 "Value" 840 "Value" 839 "Value" 838 "Value" 837 "Value" 836 "Value" 835 "Value" 834 "Value" 833 "Value" 832 "Value" 831 "Value" 830 "Value" 829 "Value" 828 "Value" 827 "Value" 826 "Value" 825 "Value" 824 "Value" 823 "Value" 822 "Value" 821 "Value" 820 "Value" 819 "Value" 818 "Value" 817 "Value" 816 "Value" 815 "Value" 814 "Value" 813 "Value" 812 "Value" 811 "Value" 810 "Value" 809 "Value" 808 "Value" 807 "Value" 806 "Value" 805 "Value" 804 "Value" 803 "Value" 802 "Value" 801 "Value" 800 "Value" 799 "Value" 798 "Value" 797 "Value" 796 "Value" 795 "Value" 794 "Value" 793 "Value" 792 "Value" 791 "Value" 790 "Value" 789 "Value" 788 "Value" 787 "Value" 786 "Value" 785 "Value" 784 "Value" 783 "Value" 782 "Value" 781 "Value" 780 "Value" 779 "Value" 778 "Value" 777 "Value" 776 "Value" 775 "Value" 774 "Value" 773 "Value" 772 "Value" 771 "Value" 770 "Value" 769 "Value" 768 "Value" 767 "Value" 766 "Value" 765 "Value" 764 "Value" 763 "Value" 762 "Value" 761 "Value" 760 "Value" 759 "Value" 758 "Value" 757 "Value" 756 "Value" 755 "Value" 754 "Value" 753 "Value" 752 "Value" 751 "Value" 750 "Value" 749 "Value" 748 "Value" 747 "Value" 746 "Value" 745 "Value" 744 "Value" 743 "Value" 742 "Value" 741 "Value" 740 "Value" 739 "Value" 738 "Value" 737 "Value" 736 "Value" 735 "Value" 734 "Value" 733 "Value" 732 "Value" 731 "Value" 730 "Value" 729 "Value" 728 "Value" 727 "Value" 726 "Value" 725 "Value" 724 "Value" 723 "Value" 722 "Value" 721 "Value" 720 "Value" 719 "Value" 718 "Value" 717 "Value" 716 "Value" 715 "Value" 714 "Value" 713 "Value" 712 "Value" 711 "Value" 710 "Value" 709 "Value" 708 "Value" 707 "Value" 706 "Value" 705 "Value" 704 "Value" 703 "Value" 702 "Value" 701 "Value" 700 "Value" 699 "Value" 698 "Value" 697 "Value" 696 "Value" 695 "Value" 694 "Value" 693 "Value" 692 "Value" 691 "Value" 690 "Value" 689 "Value" 688 "Value" 687 "Value" 686 "Value" 685 "Value" 684 "Value" 683 "Value" 682 "Value" 681 "Value" 680 "Value" 679 "Value" 678 "Value" 677 "Value" 676 "Value" 675 "Value" 674 "Value" 673 "Value" 672 "Value" 671 "Value" 670 "Value" 669 "Value" 668 "Value" 667 "Value" 666 "Value" 665 "Value" 664 "Value" 663 "Value" 662 "Value" 661 "Value" 660 "Value" 659 "Value" 658 "Value" 657 "Value" 656 "Value" 655 "Value" 654 "Value" 653 "Value" 652 "Value" 651 "Value" 650 "Value" 649 "Value" 648 "Value" 647 "Value" 646 "Value" 645 "Value" 644 "Value" 643 "Value" 642 "Value" 641 "Value" 640 "Value" 639 "Value" 638 "Value" 637 "Value" 636 "Value" 635 "Value" 634 "Value" 633 "Value" 632 "Value" 631 "Value" 630 "Value" 629 "Value" 628 "Value" 627 "Value" 626 "Value" 625 "Value" 624 "Value" 623 "Value" 622 "Value" 621 "Value" 620 "Value" 619 "Value" 618 "Value" 617 "Value" 616 "Value" 615 "Value" 614 "Value" 613 "Value" 612 "Value" 611 "Value" 610 "Value" 609 "Value" 608 "Value" 607 "Value" 606 "Value" 605 "Value" 604 "Value" 603 "Value" 602 "Value" 601 "Value" 600 "Value" 599 "Value" 598 "Value" 597 "Value" 596 "Value" 595 "Value" 594 "Value" 593 "Value" 592 "Value" 591 "Value" 590 "Value" 589 "Value" 588 "Value" 587 "Value" 586 "Value" 585 "Value" 584 "Value" 583 "Value" 582 "Value" 581 "Value" 580 "Value" 579 "Value" 578 "Value" 577 "Value" 576 "Value" 575 "Value" 574 "Value" 573 "Value" 572 "Value" 571 "Value" 570 "Value" 569 "Value" 568 "Value" 567 "Value" 566 "Value" 565 "Value" 564 "Value" 563 "Value" 562 "Value" 561 "Value" 560 "Value" 559 "Value" 558 "Value" 557 "Value" 556 "Value" 555 "Value" 554 "Value" 553 "Value" 552 "Value" 551 "Value" 550 "Value" 549 "Value" 548 "Value" 547 "Value" 546 "Value" 545 "Value" 544 "Value" 543 "Value" 542 "Value" 541 "Value" 540 "Value" 539 "Value" 538 "Value" 537 "Value" 536 "Value" 535 "Value" 534 "Value" 533 "Value" 532 "Value" 531 "Value" 530 "Value" 529 "Value" 528 "Value" 527 "Value" 526 "Value" 525 "Value" 524 "Value" 523 "Value" 522 "Value" 521 "Value" 520 "Value" 519 "Value" 518 "Value" 517 "Value" 516 "Value" 515 "Value" 514 "Value" 513 "Value" 512 "Value" 511 "Value" 510 "Value" 509 "Value" 508 "Value" 507 "Value" 506 "Value" 505 "Value" 504 "Value" 503 "Value" 502 "Value" 501 "Value" 500 "Value" 499 "Value" 498 "Value" 497 "Value" 496 "Value" 495 "Value" 494 "Value" 493 "Value" 492 "Value" 491 "Value" 490 "Value" 489 "Value" 488 "Value" 487 "Value" 486 "Value" 485 "Value" 484 "Value" 483 "Value" 482 "Value" 481 "Value" 480 "Value" 479 "Value" 478 "Value" 477 "Value" 476 "Value" 475 "Value" 474 "Value" 473 "Value" 472 "Value" 471 "Value" 470 "Value" 469 "Value" 468 "Value" 467 "Value" 466 "Value" 465 "Value" 464 "Value" 463 "Value" 462 "Value" 461 "Value" 460 "Value" 459 "Value" 458 "Value" 457 "Value" 456 "Value" 455 "Value" 454 "Value" 453 "Value" 452 "Value" 451 "Value" 450 "Value" 449 "Value" 448 "Value" 447 "Value" 446 "Value" 445 "Value" 444 "Value" 443 "Value" 442 "Value" 441 "Value" 440 "Value" 439 "Value" 438 "Value" 437 "Value" 436 "Value" 435 "Value" 434 "Value" 433 "Value" 432 "Value" 431 "Value" 430 "Value" 429 "Value" 428 "Value" 427 "Value" 426 "Value" 425 "Value" 424 "Value" 423 "Value" 422 "Value" 421 "Value" 420 "Value" 419 "Value" 418 "Value" 417 "Value" 416 "Value" 415 "Value" 414 "Value" 413 "Value" 412 "Value" 411 "Value" 410 "Value" 409 "Value" 408 "Value" 407 "Value" 406 "Value" 405 "Value" 404 "Value" 403 "Value" 402 "Value" 401 "Value" 400 "Value" 399 "Value" 398 "Value" 397 "Value" 396 "Value" 395 "Value" 394 "Value" 393 "Value" 392 "Value" 391 "Value" 390 "Value" 389 "Value" 388 "Value" 387 "Value" 386 "Value" 385 "Value" 384 "Value" 383 "Value" 382 "Value" 381 "Value" 380 "Value" 379 "Value" 378 "Value" 377 "Value" 376 "Value" 375 "Value" 374 "Value" 373 "Value" 372 "Value" 371 "Value" 370 "Value" 369 "Value" 368 "Value" 367 "Value" 366 "Value" 365 "Value" 364 "Value" 363 "Value" 362 "Value" 361 "Value" 360 "Value" 359 "Value" 358 "Value" 357 "Value" 356 "Value" 355 "Value" 354 "Value" 353 "Value" 352 "Value" 351 "Value" 350 "Value" 349 "Value" 348 "Value" 347 "Value" 346 "Value" 345 "Value" 344 "Value" 343 "Value" 342 "Value" 341 "Value" 340 "Value" 339 "Value" 338 "Value" 337 "Value" 336 "Value" 335 "Value" 334 "Value" 333 "Value" 332 "Value" 331 "Value" 330 "Value" 329 "Value" 328 "Value" 327 "Value" 326 "Value" 325 "Value" 324 "Value" 323 "Value" 322 "Value" 321 "Value" 320 "Value" 319 "Value" 318 "Value" 317 "Value" 316 "Value" 315 "Value" 314 "Value" 313 "Value" 312 "Value" 311 "Value" 310 "Value" 309 "Value" 308 "Value" 307 "Value" 306 "Value" 305 "Value" 304 "Value" 303 "Value" 302 "Value" 301 "Value" 300 "Value" 299 "Value" 298 "Value" 297 "Value" 296 "Value" 295 "Value" 294 "Value" 293 "Value" 292 "Value" 291 "Value" 290 "Value" 289 "Value" 288 "Value" 287 "Value" 286 "Value" 285 "Value" 284 "Value" 283 "Value" 282 "Value" 281 "Value" 280 "Value" 279 "Value" 278 "Value" 277 "Value" 276 "Value" 275 "Value" 274 "Value" 273 "Value" 272 "Value" 271 "Value" 270 "Value" 269 "Value" 268 "Value" 267 "Value" 266 "Value" 265 "Value" 264 "Value" 263 "Value" 262 "Value" 261 "Value" 260 "Value" 259 "Value" 258 "Value" 257 "Value" 256 "Value" 255 "Value" 254 "Value" 253 "Value" 252 "Value" 251 "Value" 250 "Value" 249 "Value" 248 "Value" 247 "Value" 246 "Value" 245 "Value" 244 "Value" 243 "Value" 242 "Value" 241 "Value" 240 "Value" 239 "Value" 238 "Value" 237 "Value" 236 "Value" 235 "Value" 234 "Value" 233 "Value" 232 "Value" 231 "Value" 230 "Value" 229 "Value" 228 "Value" 227 "Value" 226 "Value" 225 "Value" 224 "Value" 223 "Value" 222 "Value" 221 "Value" 220 "Value" 219 "Value" 218 "Value" 217 "Value" 216 "Value" 215 "Value" 214 "Value" 213 "Value" 212 "Value" 211 "Value" 210 "Value" 209 "Value" 208 "Value" 207 "Value" 206 "Value" 205 "Value" 204 "Value" 203 "Value" 202 "Value" 201 "Value" 200 "Value" 199 "Value" 198 "Value" 197 "Value" 196 "Value" 195 "Value" 194 "Value" 193 "Value" 192 "Value" 191 "Value" 190 "Value" 189 "Value" 188 "Value" 187 "Value" 186 "Value" 185 "Value" 184 "Value" 183 "Value" 182 "Value" 181 "Value" 180 "Value" 179 "Value" 178 "Value" 177 "Value" 176 "Value" 175 "Value" 174 "Value" 173 "Value" 172 "Value" 171 "Value" 170 "Value" 169 "Value" 168 "Value" 167 "Value" 166 "Value" 165 "Value" 164 "Value" 163 "Value" 162 "Value" 161 "Value" 160 "Value" 159 "Value" 158 "Value" 157 "Value" 156 "Value" 155 "Value" 154 "Value" 153 "Value" 152 "Value" 151 "Value" 150 "Value" 149 "Value" 148 "Value" 147 "Value" 146 "Value" 145 "Value" 144 "Value" 143 "Value" 142 "Value" 141 "Value" 140 "Value" 139 "Value" 138 "Value" 137 "Value" 136 "Value" 135 "Value" 134 "Value" 133 "Value" 132 "Value" 131 "Value" 130 "Value" 129 "Value" 128 "Value" 127 "Value" 126 "Value" 125 "Value" 124 "Value" 123 "Value" 122 "Value" 121 "Value" 120 "Value" 119 "Value" 118 "Value" 117 "Value" 116 "Value" 115 "Value" 114 "Value" 113 "Value" 112 "Value" 111 "Value" 110 "Value" 109 "Value" 108 "Value" 107 "Value" 106 "Value" 105 "Value" 104 "Value" 103 "Value" 102 "Value" 101 "Value" 100 "Value" 99 "Value" 98 "Value" 97 "Value" 96 "Value" 95 "Value" 94 "Value" 93 "Value" 92 "Value" 91 "Value" 90 "Value" 89 "Value" 88 "Value" 87 "Value" 86 "Value" 85 "Value" 84 "Value" 83 "Value" 82 "Value" 81 "Value" 80 "Value" 79 "Value" 78 "Value" 77 "Value" 76 "Value" 75 "Value" 74 "Value" 73 "Value" 72 "Value" 71 "Value" 70 "Value" 69 "Value" 68 "Value" 67 "Value" 66 "Value" 65 "Value" 64 "Value" 63 "Value" 62 "Value" 61 "Value" 60 "Value" 59 "Value" 58 "Value" 57 "Value" 56 "Value" 55 "Value" 54 "Value" 53 "Value" 52 "Value" 51 "Value" 50 "Value" 49 "Value" 48 "Value" 47 "Value" 46 "Value" 45 "Value" 44 "Value" 43 "Value" 42 "Value" 41 "Value" 40 "Value" 39 "Value" 38 "Value" 37 "Value" 36 "Value" 35 "Value" 34 "Value" 33 "Value" 32 "Value" 31 "Value" 30 "Value" 29 "Value" 28 "Value" 27 "Value" 26 "Value" 25 "Value" 24 "Value" 23 "Value" 22 "Value" 21 "Value" 20 "Value" 19 "Value" 18 "Value" 17 "Value" 16 "Value" 15 "Value" 14 "Value" 13 "Value" 12 "Value" 11 "Value" 10 "Value" 9 "Value" 8 "Value" 7 "Value" 6 "Value" 5 "Value" 4 "Value" 3 "Value" 2 "Value" 1 "Value" 0 "Value" ;
VAL_ 563 ADCU3A_LgtdAcclVld 1 "Valid" 0 "Invalid" ;
VAL_ 563 ADCU3A_LatAccl 4095 "Invalid" 3000 "Value" 2999 "Value" 2998 "Value" 2997 "Value" 2996 "Value" 2995 "Value" 2994 "Value" 2993 "Value" 2992 "Value" 2991 "Value" 2990 "Value" 2989 "Value" 2988 "Value" 2987 "Value" 2986 "Value" 2985 "Value" 2984 "Value" 2983 "Value" 2982 "Value" 2981 "Value" 2980 "Value" 2979 "Value" 2978 "Value" 2977 "Value" 2976 "Value" 2975 "Value" 2974 "Value" 2973 "Value" 2972 "Value" 2971 "Value" 2970 "Value" 2969 "Value" 2968 "Value" 2967 "Value" 2966 "Value" 2965 "Value" 2964 "Value" 2963 "Value" 2962 "Value" 2961 "Value" 2960 "Value" 2959 "Value" 2958 "Value" 2957 "Value" 2956 "Value" 2955 "Value" 2954 "Value" 2953 "Value" 2952 "Value" 2951 "Value" 2950 "Value" 2949 "Value" 2948 "Value" 2947 "Value" 2946 "Value" 2945 "Value" 2944 "Value" 2943 "Value" 2942 "Value" 2941 "Value" 2940 "Value" 2939 "Value" 2938 "Value" 2937 "Value" 2936 "Value" 2935 "Value" 2934 "Value" 2933 "Value" 2932 "Value" 2931 "Value" 2930 "Value" 2929 "Value" 2928 "Value" 2927 "Value" 2926 "Value" 2925 "Value" 2924 "Value" 2923 "Value" 2922 "Value" 2921 "Value" 2920 "Value" 2919 "Value" 2918 "Value" 2917 "Value" 2916 "Value" 2915 "Value" 2914 "Value" 2913 "Value" 2912 "Value" 2911 "Value" 2910 "Value" 2909 "Value" 2908 "Value" 2907 "Value" 2906 "Value" 2905 "Value" 2904 "Value" 2903 "Value" 2902 "Value" 2901 "Value" 2900 "Value" 2899 "Value" 2898 "Value" 2897 "Value" 2896 "Value" 2895 "Value" 2894 "Value" 2893 "Value" 2892 "Value" 2891 "Value" 2890 "Value" 2889 "Value" 2888 "Value" 2887 "Value" 2886 "Value" 2885 "Value" 2884 "Value" 2883 "Value" 2882 "Value" 2881 "Value" 2880 "Value" 2879 "Value" 2878 "Value" 2877 "Value" 2876 "Value" 2875 "Value" 2874 "Value" 2873 "Value" 2872 "Value" 2871 "Value" 2870 "Value" 2869 "Value" 2868 "Value" 2867 "Value" 2866 "Value" 2865 "Value" 2864 "Value" 2863 "Value" 2862 "Value" 2861 "Value" 2860 "Value" 2859 "Value" 2858 "Value" 2857 "Value" 2856 "Value" 2855 "Value" 2854 "Value" 2853 "Value" 2852 "Value" 2851 "Value" 2850 "Value" 2849 "Value" 2848 "Value" 2847 "Value" 2846 "Value" 2845 "Value" 2844 "Value" 2843 "Value" 2842 "Value" 2841 "Value" 2840 "Value" 2839 "Value" 2838 "Value" 2837 "Value" 2836 "Value" 2835 "Value" 2834 "Value" 2833 "Value" 2832 "Value" 2831 "Value" 2830 "Value" 2829 "Value" 2828 "Value" 2827 "Value" 2826 "Value" 2825 "Value" 2824 "Value" 2823 "Value" 2822 "Value" 2821 "Value" 2820 "Value" 2819 "Value" 2818 "Value" 2817 "Value" 2816 "Value" 2815 "Value" 2814 "Value" 2813 "Value" 2812 "Value" 2811 "Value" 2810 "Value" 2809 "Value" 2808 "Value" 2807 "Value" 2806 "Value" 2805 "Value" 2804 "Value" 2803 "Value" 2802 "Value" 2801 "Value" 2800 "Value" 2799 "Value" 2798 "Value" 2797 "Value" 2796 "Value" 2795 "Value" 2794 "Value" 2793 "Value" 2792 "Value" 2791 "Value" 2790 "Value" 2789 "Value" 2788 "Value" 2787 "Value" 2786 "Value" 2785 "Value" 2784 "Value" 2783 "Value" 2782 "Value" 2781 "Value" 2780 "Value" 2779 "Value" 2778 "Value" 2777 "Value" 2776 "Value" 2775 "Value" 2774 "Value" 2773 "Value" 2772 "Value" 2771 "Value" 2770 "Value" 2769 "Value" 2768 "Value" 2767 "Value" 2766 "Value" 2765 "Value" 2764 "Value" 2763 "Value" 2762 "Value" 2761 "Value" 2760 "Value" 2759 "Value" 2758 "Value" 2757 "Value" 2756 "Value" 2755 "Value" 2754 "Value" 2753 "Value" 2752 "Value" 2751 "Value" 2750 "Value" 2749 "Value" 2748 "Value" 2747 "Value" 2746 "Value" 2745 "Value" 2744 "Value" 2743 "Value" 2742 "Value" 2741 "Value" 2740 "Value" 2739 "Value" 2738 "Value" 2737 "Value" 2736 "Value" 2735 "Value" 2734 "Value" 2733 "Value" 2732 "Value" 2731 "Value" 2730 "Value" 2729 "Value" 2728 "Value" 2727 "Value" 2726 "Value" 2725 "Value" 2724 "Value" 2723 "Value" 2722 "Value" 2721 "Value" 2720 "Value" 2719 "Value" 2718 "Value" 2717 "Value" 2716 "Value" 2715 "Value" 2714 "Value" 2713 "Value" 2712 "Value" 2711 "Value" 2710 "Value" 2709 "Value" 2708 "Value" 2707 "Value" 2706 "Value" 2705 "Value" 2704 "Value" 2703 "Value" 2702 "Value" 2701 "Value" 2700 "Value" 2699 "Value" 2698 "Value" 2697 "Value" 2696 "Value" 2695 "Value" 2694 "Value" 2693 "Value" 2692 "Value" 2691 "Value" 2690 "Value" 2689 "Value" 2688 "Value" 2687 "Value" 2686 "Value" 2685 "Value" 2684 "Value" 2683 "Value" 2682 "Value" 2681 "Value" 2680 "Value" 2679 "Value" 2678 "Value" 2677 "Value" 2676 "Value" 2675 "Value" 2674 "Value" 2673 "Value" 2672 "Value" 2671 "Value" 2670 "Value" 2669 "Value" 2668 "Value" 2667 "Value" 2666 "Value" 2665 "Value" 2664 "Value" 2663 "Value" 2662 "Value" 2661 "Value" 2660 "Value" 2659 "Value" 2658 "Value" 2657 "Value" 2656 "Value" 2655 "Value" 2654 "Value" 2653 "Value" 2652 "Value" 2651 "Value" 2650 "Value" 2649 "Value" 2648 "Value" 2647 "Value" 2646 "Value" 2645 "Value" 2644 "Value" 2643 "Value" 2642 "Value" 2641 "Value" 2640 "Value" 2639 "Value" 2638 "Value" 2637 "Value" 2636 "Value" 2635 "Value" 2634 "Value" 2633 "Value" 2632 "Value" 2631 "Value" 2630 "Value" 2629 "Value" 2628 "Value" 2627 "Value" 2626 "Value" 2625 "Value" 2624 "Value" 2623 "Value" 2622 "Value" 2621 "Value" 2620 "Value" 2619 "Value" 2618 "Value" 2617 "Value" 2616 "Value" 2615 "Value" 2614 "Value" 2613 "Value" 2612 "Value" 2611 "Value" 2610 "Value" 2609 "Value" 2608 "Value" 2607 "Value" 2606 "Value" 2605 "Value" 2604 "Value" 2603 "Value" 2602 "Value" 2601 "Value" 2600 "Value" 2599 "Value" 2598 "Value" 2597 "Value" 2596 "Value" 2595 "Value" 2594 "Value" 2593 "Value" 2592 "Value" 2591 "Value" 2590 "Value" 2589 "Value" 2588 "Value" 2587 "Value" 2586 "Value" 2585 "Value" 2584 "Value" 2583 "Value" 2582 "Value" 2581 "Value" 2580 "Value" 2579 "Value" 2578 "Value" 2577 "Value" 2576 "Value" 2575 "Value" 2574 "Value" 2573 "Value" 2572 "Value" 2571 "Value" 2570 "Value" 2569 "Value" 2568 "Value" 2567 "Value" 2566 "Value" 2565 "Value" 2564 "Value" 2563 "Value" 2562 "Value" 2561 "Value" 2560 "Value" 2559 "Value" 2558 "Value" 2557 "Value" 2556 "Value" 2555 "Value" 2554 "Value" 2553 "Value" 2552 "Value" 2551 "Value" 2550 "Value" 2549 "Value" 2548 "Value" 2547 "Value" 2546 "Value" 2545 "Value" 2544 "Value" 2543 "Value" 2542 "Value" 2541 "Value" 2540 "Value" 2539 "Value" 2538 "Value" 2537 "Value" 2536 "Value" 2535 "Value" 2534 "Value" 2533 "Value" 2532 "Value" 2531 "Value" 2530 "Value" 2529 "Value" 2528 "Value" 2527 "Value" 2526 "Value" 2525 "Value" 2524 "Value" 2523 "Value" 2522 "Value" 2521 "Value" 2520 "Value" 2519 "Value" 2518 "Value" 2517 "Value" 2516 "Value" 2515 "Value" 2514 "Value" 2513 "Value" 2512 "Value" 2511 "Value" 2510 "Value" 2509 "Value" 2508 "Value" 2507 "Value" 2506 "Value" 2505 "Value" 2504 "Value" 2503 "Value" 2502 "Value" 2501 "Value" 2500 "Value" 2499 "Value" 2498 "Value" 2497 "Value" 2496 "Value" 2495 "Value" 2494 "Value" 2493 "Value" 2492 "Value" 2491 "Value" 2490 "Value" 2489 "Value" 2488 "Value" 2487 "Value" 2486 "Value" 2485 "Value" 2484 "Value" 2483 "Value" 2482 "Value" 2481 "Value" 2480 "Value" 2479 "Value" 2478 "Value" 2477 "Value" 2476 "Value" 2475 "Value" 2474 "Value" 2473 "Value" 2472 "Value" 2471 "Value" 2470 "Value" 2469 "Value" 2468 "Value" 2467 "Value" 2466 "Value" 2465 "Value" 2464 "Value" 2463 "Value" 2462 "Value" 2461 "Value" 2460 "Value" 2459 "Value" 2458 "Value" 2457 "Value" 2456 "Value" 2455 "Value" 2454 "Value" 2453 "Value" 2452 "Value" 2451 "Value" 2450 "Value" 2449 "Value" 2448 "Value" 2447 "Value" 2446 "Value" 2445 "Value" 2444 "Value" 2443 "Value" 2442 "Value" 2441 "Value" 2440 "Value" 2439 "Value" 2438 "Value" 2437 "Value" 2436 "Value" 2435 "Value" 2434 "Value" 2433 "Value" 2432 "Value" 2431 "Value" 2430 "Value" 2429 "Value" 2428 "Value" 2427 "Value" 2426 "Value" 2425 "Value" 2424 "Value" 2423 "Value" 2422 "Value" 2421 "Value" 2420 "Value" 2419 "Value" 2418 "Value" 2417 "Value" 2416 "Value" 2415 "Value" 2414 "Value" 2413 "Value" 2412 "Value" 2411 "Value" 2410 "Value" 2409 "Value" 2408 "Value" 2407 "Value" 2406 "Value" 2405 "Value" 2404 "Value" 2403 "Value" 2402 "Value" 2401 "Value" 2400 "Value" 2399 "Value" 2398 "Value" 2397 "Value" 2396 "Value" 2395 "Value" 2394 "Value" 2393 "Value" 2392 "Value" 2391 "Value" 2390 "Value" 2389 "Value" 2388 "Value" 2387 "Value" 2386 "Value" 2385 "Value" 2384 "Value" 2383 "Value" 2382 "Value" 2381 "Value" 2380 "Value" 2379 "Value" 2378 "Value" 2377 "Value" 2376 "Value" 2375 "Value" 2374 "Value" 2373 "Value" 2372 "Value" 2371 "Value" 2370 "Value" 2369 "Value" 2368 "Value" 2367 "Value" 2366 "Value" 2365 "Value" 2364 "Value" 2363 "Value" 2362 "Value" 2361 "Value" 2360 "Value" 2359 "Value" 2358 "Value" 2357 "Value" 2356 "Value" 2355 "Value" 2354 "Value" 2353 "Value" 2352 "Value" 2351 "Value" 2350 "Value" 2349 "Value" 2348 "Value" 2347 "Value" 2346 "Value" 2345 "Value" 2344 "Value" 2343 "Value" 2342 "Value" 2341 "Value" 2340 "Value" 2339 "Value" 2338 "Value" 2337 "Value" 2336 "Value" 2335 "Value" 2334 "Value" 2333 "Value" 2332 "Value" 2331 "Value" 2330 "Value" 2329 "Value" 2328 "Value" 2327 "Value" 2326 "Value" 2325 "Value" 2324 "Value" 2323 "Value" 2322 "Value" 2321 "Value" 2320 "Value" 2319 "Value" 2318 "Value" 2317 "Value" 2316 "Value" 2315 "Value" 2314 "Value" 2313 "Value" 2312 "Value" 2311 "Value" 2310 "Value" 2309 "Value" 2308 "Value" 2307 "Value" 2306 "Value" 2305 "Value" 2304 "Value" 2303 "Value" 2302 "Value" 2301 "Value" 2300 "Value" 2299 "Value" 2298 "Value" 2297 "Value" 2296 "Value" 2295 "Value" 2294 "Value" 2293 "Value" 2292 "Value" 2291 "Value" 2290 "Value" 2289 "Value" 2288 "Value" 2287 "Value" 2286 "Value" 2285 "Value" 2284 "Value" 2283 "Value" 2282 "Value" 2281 "Value" 2280 "Value" 2279 "Value" 2278 "Value" 2277 "Value" 2276 "Value" 2275 "Value" 2274 "Value" 2273 "Value" 2272 "Value" 2271 "Value" 2270 "Value" 2269 "Value" 2268 "Value" 2267 "Value" 2266 "Value" 2265 "Value" 2264 "Value" 2263 "Value" 2262 "Value" 2261 "Value" 2260 "Value" 2259 "Value" 2258 "Value" 2257 "Value" 2256 "Value" 2255 "Value" 2254 "Value" 2253 "Value" 2252 "Value" 2251 "Value" 2250 "Value" 2249 "Value" 2248 "Value" 2247 "Value" 2246 "Value" 2245 "Value" 2244 "Value" 2243 "Value" 2242 "Value" 2241 "Value" 2240 "Value" 2239 "Value" 2238 "Value" 2237 "Value" 2236 "Value" 2235 "Value" 2234 "Value" 2233 "Value" 2232 "Value" 2231 "Value" 2230 "Value" 2229 "Value" 2228 "Value" 2227 "Value" 2226 "Value" 2225 "Value" 2224 "Value" 2223 "Value" 2222 "Value" 2221 "Value" 2220 "Value" 2219 "Value" 2218 "Value" 2217 "Value" 2216 "Value" 2215 "Value" 2214 "Value" 2213 "Value" 2212 "Value" 2211 "Value" 2210 "Value" 2209 "Value" 2208 "Value" 2207 "Value" 2206 "Value" 2205 "Value" 2204 "Value" 2203 "Value" 2202 "Value" 2201 "Value" 2200 "Value" 2199 "Value" 2198 "Value" 2197 "Value" 2196 "Value" 2195 "Value" 2194 "Value" 2193 "Value" 2192 "Value" 2191 "Value" 2190 "Value" 2189 "Value" 2188 "Value" 2187 "Value" 2186 "Value" 2185 "Value" 2184 "Value" 2183 "Value" 2182 "Value" 2181 "Value" 2180 "Value" 2179 "Value" 2178 "Value" 2177 "Value" 2176 "Value" 2175 "Value" 2174 "Value" 2173 "Value" 2172 "Value" 2171 "Value" 2170 "Value" 2169 "Value" 2168 "Value" 2167 "Value" 2166 "Value" 2165 "Value" 2164 "Value" 2163 "Value" 2162 "Value" 2161 "Value" 2160 "Value" 2159 "Value" 2158 "Value" 2157 "Value" 2156 "Value" 2155 "Value" 2154 "Value" 2153 "Value" 2152 "Value" 2151 "Value" 2150 "Value" 2149 "Value" 2148 "Value" 2147 "Value" 2146 "Value" 2145 "Value" 2144 "Value" 2143 "Value" 2142 "Value" 2141 "Value" 2140 "Value" 2139 "Value" 2138 "Value" 2137 "Value" 2136 "Value" 2135 "Value" 2134 "Value" 2133 "Value" 2132 "Value" 2131 "Value" 2130 "Value" 2129 "Value" 2128 "Value" 2127 "Value" 2126 "Value" 2125 "Value" 2124 "Value" 2123 "Value" 2122 "Value" 2121 "Value" 2120 "Value" 2119 "Value" 2118 "Value" 2117 "Value" 2116 "Value" 2115 "Value" 2114 "Value" 2113 "Value" 2112 "Value" 2111 "Value" 2110 "Value" 2109 "Value" 2108 "Value" 2107 "Value" 2106 "Value" 2105 "Value" 2104 "Value" 2103 "Value" 2102 "Value" 2101 "Value" 2100 "Value" 2099 "Value" 2098 "Value" 2097 "Value" 2096 "Value" 2095 "Value" 2094 "Value" 2093 "Value" 2092 "Value" 2091 "Value" 2090 "Value" 2089 "Value" 2088 "Value" 2087 "Value" 2086 "Value" 2085 "Value" 2084 "Value" 2083 "Value" 2082 "Value" 2081 "Value" 2080 "Value" 2079 "Value" 2078 "Value" 2077 "Value" 2076 "Value" 2075 "Value" 2074 "Value" 2073 "Value" 2072 "Value" 2071 "Value" 2070 "Value" 2069 "Value" 2068 "Value" 2067 "Value" 2066 "Value" 2065 "Value" 2064 "Value" 2063 "Value" 2062 "Value" 2061 "Value" 2060 "Value" 2059 "Value" 2058 "Value" 2057 "Value" 2056 "Value" 2055 "Value" 2054 "Value" 2053 "Value" 2052 "Value" 2051 "Value" 2050 "Value" 2049 "Value" 2048 "Value" 2047 "Value" 2046 "Value" 2045 "Value" 2044 "Value" 2043 "Value" 2042 "Value" 2041 "Value" 2040 "Value" 2039 "Value" 2038 "Value" 2037 "Value" 2036 "Value" 2035 "Value" 2034 "Value" 2033 "Value" 2032 "Value" 2031 "Value" 2030 "Value" 2029 "Value" 2028 "Value" 2027 "Value" 2026 "Value" 2025 "Value" 2024 "Value" 2023 "Value" 2022 "Value" 2021 "Value" 2020 "Value" 2019 "Value" 2018 "Value" 2017 "Value" 2016 "Value" 2015 "Value" 2014 "Value" 2013 "Value" 2012 "Value" 2011 "Value" 2010 "Value" 2009 "Value" 2008 "Value" 2007 "Value" 2006 "Value" 2005 "Value" 2004 "Value" 2003 "Value" 2002 "Value" 2001 "Value" 2000 "Value" 1999 "Value" 1998 "Value" 1997 "Value" 1996 "Value" 1995 "Value" 1994 "Value" 1993 "Value" 1992 "Value" 1991 "Value" 1990 "Value" 1989 "Value" 1988 "Value" 1987 "Value" 1986 "Value" 1985 "Value" 1984 "Value" 1983 "Value" 1982 "Value" 1981 "Value" 1980 "Value" 1979 "Value" 1978 "Value" 1977 "Value" 1976 "Value" 1975 "Value" 1974 "Value" 1973 "Value" 1972 "Value" 1971 "Value" 1970 "Value" 1969 "Value" 1968 "Value" 1967 "Value" 1966 "Value" 1965 "Value" 1964 "Value" 1963 "Value" 1962 "Value" 1961 "Value" 1960 "Value" 1959 "Value" 1958 "Value" 1957 "Value" 1956 "Value" 1955 "Value" 1954 "Value" 1953 "Value" 1952 "Value" 1951 "Value" 1950 "Value" 1949 "Value" 1948 "Value" 1947 "Value" 1946 "Value" 1945 "Value" 1944 "Value" 1943 "Value" 1942 "Value" 1941 "Value" 1940 "Value" 1939 "Value" 1938 "Value" 1937 "Value" 1936 "Value" 1935 "Value" 1934 "Value" 1933 "Value" 1932 "Value" 1931 "Value" 1930 "Value" 1929 "Value" 1928 "Value" 1927 "Value" 1926 "Value" 1925 "Value" 1924 "Value" 1923 "Value" 1922 "Value" 1921 "Value" 1920 "Value" 1919 "Value" 1918 "Value" 1917 "Value" 1916 "Value" 1915 "Value" 1914 "Value" 1913 "Value" 1912 "Value" 1911 "Value" 1910 "Value" 1909 "Value" 1908 "Value" 1907 "Value" 1906 "Value" 1905 "Value" 1904 "Value" 1903 "Value" 1902 "Value" 1901 "Value" 1900 "Value" 1899 "Value" 1898 "Value" 1897 "Value" 1896 "Value" 1895 "Value" 1894 "Value" 1893 "Value" 1892 "Value" 1891 "Value" 1890 "Value" 1889 "Value" 1888 "Value" 1887 "Value" 1886 "Value" 1885 "Value" 1884 "Value" 1883 "Value" 1882 "Value" 1881 "Value" 1880 "Value" 1879 "Value" 1878 "Value" 1877 "Value" 1876 "Value" 1875 "Value" 1874 "Value" 1873 "Value" 1872 "Value" 1871 "Value" 1870 "Value" 1869 "Value" 1868 "Value" 1867 "Value" 1866 "Value" 1865 "Value" 1864 "Value" 1863 "Value" 1862 "Value" 1861 "Value" 1860 "Value" 1859 "Value" 1858 "Value" 1857 "Value" 1856 "Value" 1855 "Value" 1854 "Value" 1853 "Value" 1852 "Value" 1851 "Value" 1850 "Value" 1849 "Value" 1848 "Value" 1847 "Value" 1846 "Value" 1845 "Value" 1844 "Value" 1843 "Value" 1842 "Value" 1841 "Value" 1840 "Value" 1839 "Value" 1838 "Value" 1837 "Value" 1836 "Value" 1835 "Value" 1834 "Value" 1833 "Value" 1832 "Value" 1831 "Value" 1830 "Value" 1829 "Value" 1828 "Value" 1827 "Value" 1826 "Value" 1825 "Value" 1824 "Value" 1823 "Value" 1822 "Value" 1821 "Value" 1820 "Value" 1819 "Value" 1818 "Value" 1817 "Value" 1816 "Value" 1815 "Value" 1814 "Value" 1813 "Value" 1812 "Value" 1811 "Value" 1810 "Value" 1809 "Value" 1808 "Value" 1807 "Value" 1806 "Value" 1805 "Value" 1804 "Value" 1803 "Value" 1802 "Value" 1801 "Value" 1800 "Value" 1799 "Value" 1798 "Value" 1797 "Value" 1796 "Value" 1795 "Value" 1794 "Value" 1793 "Value" 1792 "Value" 1791 "Value" 1790 "Value" 1789 "Value" 1788 "Value" 1787 "Value" 1786 "Value" 1785 "Value" 1784 "Value" 1783 "Value" 1782 "Value" 1781 "Value" 1780 "Value" 1779 "Value" 1778 "Value" 1777 "Value" 1776 "Value" 1775 "Value" 1774 "Value" 1773 "Value" 1772 "Value" 1771 "Value" 1770 "Value" 1769 "Value" 1768 "Value" 1767 "Value" 1766 "Value" 1765 "Value" 1764 "Value" 1763 "Value" 1762 "Value" 1761 "Value" 1760 "Value" 1759 "Value" 1758 "Value" 1757 "Value" 1756 "Value" 1755 "Value" 1754 "Value" 1753 "Value" 1752 "Value" 1751 "Value" 1750 "Value" 1749 "Value" 1748 "Value" 1747 "Value" 1746 "Value" 1745 "Value" 1744 "Value" 1743 "Value" 1742 "Value" 1741 "Value" 1740 "Value" 1739 "Value" 1738 "Value" 1737 "Value" 1736 "Value" 1735 "Value" 1734 "Value" 1733 "Value" 1732 "Value" 1731 "Value" 1730 "Value" 1729 "Value" 1728 "Value" 1727 "Value" 1726 "Value" 1725 "Value" 1724 "Value" 1723 "Value" 1722 "Value" 1721 "Value" 1720 "Value" 1719 "Value" 1718 "Value" 1717 "Value" 1716 "Value" 1715 "Value" 1714 "Value" 1713 "Value" 1712 "Value" 1711 "Value" 1710 "Value" 1709 "Value" 1708 "Value" 1707 "Value" 1706 "Value" 1705 "Value" 1704 "Value" 1703 "Value" 1702 "Value" 1701 "Value" 1700 "Value" 1699 "Value" 1698 "Value" 1697 "Value" 1696 "Value" 1695 "Value" 1694 "Value" 1693 "Value" 1692 "Value" 1691 "Value" 1690 "Value" 1689 "Value" 1688 "Value" 1687 "Value" 1686 "Value" 1685 "Value" 1684 "Value" 1683 "Value" 1682 "Value" 1681 "Value" 1680 "Value" 1679 "Value" 1678 "Value" 1677 "Value" 1676 "Value" 1675 "Value" 1674 "Value" 1673 "Value" 1672 "Value" 1671 "Value" 1670 "Value" 1669 "Value" 1668 "Value" 1667 "Value" 1666 "Value" 1665 "Value" 1664 "Value" 1663 "Value" 1662 "Value" 1661 "Value" 1660 "Value" 1659 "Value" 1658 "Value" 1657 "Value" 1656 "Value" 1655 "Value" 1654 "Value" 1653 "Value" 1652 "Value" 1651 "Value" 1650 "Value" 1649 "Value" 1648 "Value" 1647 "Value" 1646 "Value" 1645 "Value" 1644 "Value" 1643 "Value" 1642 "Value" 1641 "Value" 1640 "Value" 1639 "Value" 1638 "Value" 1637 "Value" 1636 "Value" 1635 "Value" 1634 "Value" 1633 "Value" 1632 "Value" 1631 "Value" 1630 "Value" 1629 "Value" 1628 "Value" 1627 "Value" 1626 "Value" 1625 "Value" 1624 "Value" 1623 "Value" 1622 "Value" 1621 "Value" 1620 "Value" 1619 "Value" 1618 "Value" 1617 "Value" 1616 "Value" 1615 "Value" 1614 "Value" 1613 "Value" 1612 "Value" 1611 "Value" 1610 "Value" 1609 "Value" 1608 "Value" 1607 "Value" 1606 "Value" 1605 "Value" 1604 "Value" 1603 "Value" 1602 "Value" 1601 "Value" 1600 "Value" 1599 "Value" 1598 "Value" 1597 "Value" 1596 "Value" 1595 "Value" 1594 "Value" 1593 "Value" 1592 "Value" 1591 "Value" 1590 "Value" 1589 "Value" 1588 "Value" 1587 "Value" 1586 "Value" 1585 "Value" 1584 "Value" 1583 "Value" 1582 "Value" 1581 "Value" 1580 "Value" 1579 "Value" 1578 "Value" 1577 "Value" 1576 "Value" 1575 "Value" 1574 "Value" 1573 "Value" 1572 "Value" 1571 "Value" 1570 "Value" 1569 "Value" 1568 "Value" 1567 "Value" 1566 "Value" 1565 "Value" 1564 "Value" 1563 "Value" 1562 "Value" 1561 "Value" 1560 "Value" 1559 "Value" 1558 "Value" 1557 "Value" 1556 "Value" 1555 "Value" 1554 "Value" 1553 "Value" 1552 "Value" 1551 "Value" 1550 "Value" 1549 "Value" 1548 "Value" 1547 "Value" 1546 "Value" 1545 "Value" 1544 "Value" 1543 "Value" 1542 "Value" 1541 "Value" 1540 "Value" 1539 "Value" 1538 "Value" 1537 "Value" 1536 "Value" 1535 "Value" 1534 "Value" 1533 "Value" 1532 "Value" 1531 "Value" 1530 "Value" 1529 "Value" 1528 "Value" 1527 "Value" 1526 "Value" 1525 "Value" 1524 "Value" 1523 "Value" 1522 "Value" 1521 "Value" 1520 "Value" 1519 "Value" 1518 "Value" 1517 "Value" 1516 "Value" 1515 "Value" 1514 "Value" 1513 "Value" 1512 "Value" 1511 "Value" 1510 "Value" 1509 "Value" 1508 "Value" 1507 "Value" 1506 "Value" 1505 "Value" 1504 "Value" 1503 "Value" 1502 "Value" 1501 "Value" 1500 "Value" 1499 "Value" 1498 "Value" 1497 "Value" 1496 "Value" 1495 "Value" 1494 "Value" 1493 "Value" 1492 "Value" 1491 "Value" 1490 "Value" 1489 "Value" 1488 "Value" 1487 "Value" 1486 "Value" 1485 "Value" 1484 "Value" 1483 "Value" 1482 "Value" 1481 "Value" 1480 "Value" 1479 "Value" 1478 "Value" 1477 "Value" 1476 "Value" 1475 "Value" 1474 "Value" 1473 "Value" 1472 "Value" 1471 "Value" 1470 "Value" 1469 "Value" 1468 "Value" 1467 "Value" 1466 "Value" 1465 "Value" 1464 "Value" 1463 "Value" 1462 "Value" 1461 "Value" 1460 "Value" 1459 "Value" 1458 "Value" 1457 "Value" 1456 "Value" 1455 "Value" 1454 "Value" 1453 "Value" 1452 "Value" 1451 "Value" 1450 "Value" 1449 "Value" 1448 "Value" 1447 "Value" 1446 "Value" 1445 "Value" 1444 "Value" 1443 "Value" 1442 "Value" 1441 "Value" 1440 "Value" 1439 "Value" 1438 "Value" 1437 "Value" 1436 "Value" 1435 "Value" 1434 "Value" 1433 "Value" 1432 "Value" 1431 "Value" 1430 "Value" 1429 "Value" 1428 "Value" 1427 "Value" 1426 "Value" 1425 "Value" 1424 "Value" 1423 "Value" 1422 "Value" 1421 "Value" 1420 "Value" 1419 "Value" 1418 "Value" 1417 "Value" 1416 "Value" 1415 "Value" 1414 "Value" 1413 "Value" 1412 "Value" 1411 "Value" 1410 "Value" 1409 "Value" 1408 "Value" 1407 "Value" 1406 "Value" 1405 "Value" 1404 "Value" 1403 "Value" 1402 "Value" 1401 "Value" 1400 "Value" 1399 "Value" 1398 "Value" 1397 "Value" 1396 "Value" 1395 "Value" 1394 "Value" 1393 "Value" 1392 "Value" 1391 "Value" 1390 "Value" 1389 "Value" 1388 "Value" 1387 "Value" 1386 "Value" 1385 "Value" 1384 "Value" 1383 "Value" 1382 "Value" 1381 "Value" 1380 "Value" 1379 "Value" 1378 "Value" 1377 "Value" 1376 "Value" 1375 "Value" 1374 "Value" 1373 "Value" 1372 "Value" 1371 "Value" 1370 "Value" 1369 "Value" 1368 "Value" 1367 "Value" 1366 "Value" 1365 "Value" 1364 "Value" 1363 "Value" 1362 "Value" 1361 "Value" 1360 "Value" 1359 "Value" 1358 "Value" 1357 "Value" 1356 "Value" 1355 "Value" 1354 "Value" 1353 "Value" 1352 "Value" 1351 "Value" 1350 "Value" 1349 "Value" 1348 "Value" 1347 "Value" 1346 "Value" 1345 "Value" 1344 "Value" 1343 "Value" 1342 "Value" 1341 "Value" 1340 "Value" 1339 "Value" 1338 "Value" 1337 "Value" 1336 "Value" 1335 "Value" 1334 "Value" 1333 "Value" 1332 "Value" 1331 "Value" 1330 "Value" 1329 "Value" 1328 "Value" 1327 "Value" 1326 "Value" 1325 "Value" 1324 "Value" 1323 "Value" 1322 "Value" 1321 "Value" 1320 "Value" 1319 "Value" 1318 "Value" 1317 "Value" 1316 "Value" 1315 "Value" 1314 "Value" 1313 "Value" 1312 "Value" 1311 "Value" 1310 "Value" 1309 "Value" 1308 "Value" 1307 "Value" 1306 "Value" 1305 "Value" 1304 "Value" 1303 "Value" 1302 "Value" 1301 "Value" 1300 "Value" 1299 "Value" 1298 "Value" 1297 "Value" 1296 "Value" 1295 "Value" 1294 "Value" 1293 "Value" 1292 "Value" 1291 "Value" 1290 "Value" 1289 "Value" 1288 "Value" 1287 "Value" 1286 "Value" 1285 "Value" 1284 "Value" 1283 "Value" 1282 "Value" 1281 "Value" 1280 "Value" 1279 "Value" 1278 "Value" 1277 "Value" 1276 "Value" 1275 "Value" 1274 "Value" 1273 "Value" 1272 "Value" 1271 "Value" 1270 "Value" 1269 "Value" 1268 "Value" 1267 "Value" 1266 "Value" 1265 "Value" 1264 "Value" 1263 "Value" 1262 "Value" 1261 "Value" 1260 "Value" 1259 "Value" 1258 "Value" 1257 "Value" 1256 "Value" 1255 "Value" 1254 "Value" 1253 "Value" 1252 "Value" 1251 "Value" 1250 "Value" 1249 "Value" 1248 "Value" 1247 "Value" 1246 "Value" 1245 "Value" 1244 "Value" 1243 "Value" 1242 "Value" 1241 "Value" 1240 "Value" 1239 "Value" 1238 "Value" 1237 "Value" 1236 "Value" 1235 "Value" 1234 "Value" 1233 "Value" 1232 "Value" 1231 "Value" 1230 "Value" 1229 "Value" 1228 "Value" 1227 "Value" 1226 "Value" 1225 "Value" 1224 "Value" 1223 "Value" 1222 "Value" 1221 "Value" 1220 "Value" 1219 "Value" 1218 "Value" 1217 "Value" 1216 "Value" 1215 "Value" 1214 "Value" 1213 "Value" 1212 "Value" 1211 "Value" 1210 "Value" 1209 "Value" 1208 "Value" 1207 "Value" 1206 "Value" 1205 "Value" 1204 "Value" 1203 "Value" 1202 "Value" 1201 "Value" 1200 "Value" 1199 "Value" 1198 "Value" 1197 "Value" 1196 "Value" 1195 "Value" 1194 "Value" 1193 "Value" 1192 "Value" 1191 "Value" 1190 "Value" 1189 "Value" 1188 "Value" 1187 "Value" 1186 "Value" 1185 "Value" 1184 "Value" 1183 "Value" 1182 "Value" 1181 "Value" 1180 "Value" 1179 "Value" 1178 "Value" 1177 "Value" 1176 "Value" 1175 "Value" 1174 "Value" 1173 "Value" 1172 "Value" 1171 "Value" 1170 "Value" 1169 "Value" 1168 "Value" 1167 "Value" 1166 "Value" 1165 "Value" 1164 "Value" 1163 "Value" 1162 "Value" 1161 "Value" 1160 "Value" 1159 "Value" 1158 "Value" 1157 "Value" 1156 "Value" 1155 "Value" 1154 "Value" 1153 "Value" 1152 "Value" 1151 "Value" 1150 "Value" 1149 "Value" 1148 "Value" 1147 "Value" 1146 "Value" 1145 "Value" 1144 "Value" 1143 "Value" 1142 "Value" 1141 "Value" 1140 "Value" 1139 "Value" 1138 "Value" 1137 "Value" 1136 "Value" 1135 "Value" 1134 "Value" 1133 "Value" 1132 "Value" 1131 "Value" 1130 "Value" 1129 "Value" 1128 "Value" 1127 "Value" 1126 "Value" 1125 "Value" 1124 "Value" 1123 "Value" 1122 "Value" 1121 "Value" 1120 "Value" 1119 "Value" 1118 "Value" 1117 "Value" 1116 "Value" 1115 "Value" 1114 "Value" 1113 "Value" 1112 "Value" 1111 "Value" 1110 "Value" 1109 "Value" 1108 "Value" 1107 "Value" 1106 "Value" 1105 "Value" 1104 "Value" 1103 "Value" 1102 "Value" 1101 "Value" 1100 "Value" 1099 "Value" 1098 "Value" 1097 "Value" 1096 "Value" 1095 "Value" 1094 "Value" 1093 "Value" 1092 "Value" 1091 "Value" 1090 "Value" 1089 "Value" 1088 "Value" 1087 "Value" 1086 "Value" 1085 "Value" 1084 "Value" 1083 "Value" 1082 "Value" 1081 "Value" 1080 "Value" 1079 "Value" 1078 "Value" 1077 "Value" 1076 "Value" 1075 "Value" 1074 "Value" 1073 "Value" 1072 "Value" 1071 "Value" 1070 "Value" 1069 "Value" 1068 "Value" 1067 "Value" 1066 "Value" 1065 "Value" 1064 "Value" 1063 "Value" 1062 "Value" 1061 "Value" 1060 "Value" 1059 "Value" 1058 "Value" 1057 "Value" 1056 "Value" 1055 "Value" 1054 "Value" 1053 "Value" 1052 "Value" 1051 "Value" 1050 "Value" 1049 "Value" 1048 "Value" 1047 "Value" 1046 "Value" 1045 "Value" 1044 "Value" 1043 "Value" 1042 "Value" 1041 "Value" 1040 "Value" 1039 "Value" 1038 "Value" 1037 "Value" 1036 "Value" 1035 "Value" 1034 "Value" 1033 "Value" 1032 "Value" 1031 "Value" 1030 "Value" 1029 "Value" 1028 "Value" 1027 "Value" 1026 "Value" 1025 "Value" 1024 "Value" 1023 "Value" 1022 "Value" 1021 "Value" 1020 "Value" 1019 "Value" 1018 "Value" 1017 "Value" 1016 "Value" 1015 "Value" 1014 "Value" 1013 "Value" 1012 "Value" 1011 "Value" 1010 "Value" 1009 "Value" 1008 "Value" 1007 "Value" 1006 "Value" 1005 "Value" 1004 "Value" 1003 "Value" 1002 "Value" 1001 "Value" 1000 "Value" 999 "Value" 998 "Value" 997 "Value" 996 "Value" 995 "Value" 994 "Value" 993 "Value" 992 "Value" 991 "Value" 990 "Value" 989 "Value" 988 "Value" 987 "Value" 986 "Value" 985 "Value" 984 "Value" 983 "Value" 982 "Value" 981 "Value" 980 "Value" 979 "Value" 978 "Value" 977 "Value" 976 "Value" 975 "Value" 974 "Value" 973 "Value" 972 "Value" 971 "Value" 970 "Value" 969 "Value" 968 "Value" 967 "Value" 966 "Value" 965 "Value" 964 "Value" 963 "Value" 962 "Value" 961 "Value" 960 "Value" 959 "Value" 958 "Value" 957 "Value" 956 "Value" 955 "Value" 954 "Value" 953 "Value" 952 "Value" 951 "Value" 950 "Value" 949 "Value" 948 "Value" 947 "Value" 946 "Value" 945 "Value" 944 "Value" 943 "Value" 942 "Value" 941 "Value" 940 "Value" 939 "Value" 938 "Value" 937 "Value" 936 "Value" 935 "Value" 934 "Value" 933 "Value" 932 "Value" 931 "Value" 930 "Value" 929 "Value" 928 "Value" 927 "Value" 926 "Value" 925 "Value" 924 "Value" 923 "Value" 922 "Value" 921 "Value" 920 "Value" 919 "Value" 918 "Value" 917 "Value" 916 "Value" 915 "Value" 914 "Value" 913 "Value" 912 "Value" 911 "Value" 910 "Value" 909 "Value" 908 "Value" 907 "Value" 906 "Value" 905 "Value" 904 "Value" 903 "Value" 902 "Value" 901 "Value" 900 "Value" 899 "Value" 898 "Value" 897 "Value" 896 "Value" 895 "Value" 894 "Value" 893 "Value" 892 "Value" 891 "Value" 890 "Value" 889 "Value" 888 "Value" 887 "Value" 886 "Value" 885 "Value" 884 "Value" 883 "Value" 882 "Value" 881 "Value" 880 "Value" 879 "Value" 878 "Value" 877 "Value" 876 "Value" 875 "Value" 874 "Value" 873 "Value" 872 "Value" 871 "Value" 870 "Value" 869 "Value" 868 "Value" 867 "Value" 866 "Value" 865 "Value" 864 "Value" 863 "Value" 862 "Value" 861 "Value" 860 "Value" 859 "Value" 858 "Value" 857 "Value" 856 "Value" 855 "Value" 854 "Value" 853 "Value" 852 "Value" 851 "Value" 850 "Value" 849 "Value" 848 "Value" 847 "Value" 846 "Value" 845 "Value" 844 "Value" 843 "Value" 842 "Value" 841 "Value" 840 "Value" 839 "Value" 838 "Value" 837 "Value" 836 "Value" 835 "Value" 834 "Value" 833 "Value" 832 "Value" 831 "Value" 830 "Value" 829 "Value" 828 "Value" 827 "Value" 826 "Value" 825 "Value" 824 "Value" 823 "Value" 822 "Value" 821 "Value" 820 "Value" 819 "Value" 818 "Value" 817 "Value" 816 "Value" 815 "Value" 814 "Value" 813 "Value" 812 "Value" 811 "Value" 810 "Value" 809 "Value" 808 "Value" 807 "Value" 806 "Value" 805 "Value" 804 "Value" 803 "Value" 802 "Value" 801 "Value" 800 "Value" 799 "Value" 798 "Value" 797 "Value" 796 "Value" 795 "Value" 794 "Value" 793 "Value" 792 "Value" 791 "Value" 790 "Value" 789 "Value" 788 "Value" 787 "Value" 786 "Value" 785 "Value" 784 "Value" 783 "Value" 782 "Value" 781 "Value" 780 "Value" 779 "Value" 778 "Value" 777 "Value" 776 "Value" 775 "Value" 774 "Value" 773 "Value" 772 "Value" 771 "Value" 770 "Value" 769 "Value" 768 "Value" 767 "Value" 766 "Value" 765 "Value" 764 "Value" 763 "Value" 762 "Value" 761 "Value" 760 "Value" 759 "Value" 758 "Value" 757 "Value" 756 "Value" 755 "Value" 754 "Value" 753 "Value" 752 "Value" 751 "Value" 750 "Value" 749 "Value" 748 "Value" 747 "Value" 746 "Value" 745 "Value" 744 "Value" 743 "Value" 742 "Value" 741 "Value" 740 "Value" 739 "Value" 738 "Value" 737 "Value" 736 "Value" 735 "Value" 734 "Value" 733 "Value" 732 "Value" 731 "Value" 730 "Value" 729 "Value" 728 "Value" 727 "Value" 726 "Value" 725 "Value" 724 "Value" 723 "Value" 722 "Value" 721 "Value" 720 "Value" 719 "Value" 718 "Value" 717 "Value" 716 "Value" 715 "Value" 714 "Value" 713 "Value" 712 "Value" 711 "Value" 710 "Value" 709 "Value" 708 "Value" 707 "Value" 706 "Value" 705 "Value" 704 "Value" 703 "Value" 702 "Value" 701 "Value" 700 "Value" 699 "Value" 698 "Value" 697 "Value" 696 "Value" 695 "Value" 694 "Value" 693 "Value" 692 "Value" 691 "Value" 690 "Value" 689 "Value" 688 "Value" 687 "Value" 686 "Value" 685 "Value" 684 "Value" 683 "Value" 682 "Value" 681 "Value" 680 "Value" 679 "Value" 678 "Value" 677 "Value" 676 "Value" 675 "Value" 674 "Value" 673 "Value" 672 "Value" 671 "Value" 670 "Value" 669 "Value" 668 "Value" 667 "Value" 666 "Value" 665 "Value" 664 "Value" 663 "Value" 662 "Value" 661 "Value" 660 "Value" 659 "Value" 658 "Value" 657 "Value" 656 "Value" 655 "Value" 654 "Value" 653 "Value" 652 "Value" 651 "Value" 650 "Value" 649 "Value" 648 "Value" 647 "Value" 646 "Value" 645 "Value" 644 "Value" 643 "Value" 642 "Value" 641 "Value" 640 "Value" 639 "Value" 638 "Value" 637 "Value" 636 "Value" 635 "Value" 634 "Value" 633 "Value" 632 "Value" 631 "Value" 630 "Value" 629 "Value" 628 "Value" 627 "Value" 626 "Value" 625 "Value" 624 "Value" 623 "Value" 622 "Value" 621 "Value" 620 "Value" 619 "Value" 618 "Value" 617 "Value" 616 "Value" 615 "Value" 614 "Value" 613 "Value" 612 "Value" 611 "Value" 610 "Value" 609 "Value" 608 "Value" 607 "Value" 606 "Value" 605 "Value" 604 "Value" 603 "Value" 602 "Value" 601 "Value" 600 "Value" 599 "Value" 598 "Value" 597 "Value" 596 "Value" 595 "Value" 594 "Value" 593 "Value" 592 "Value" 591 "Value" 590 "Value" 589 "Value" 588 "Value" 587 "Value" 586 "Value" 585 "Value" 584 "Value" 583 "Value" 582 "Value" 581 "Value" 580 "Value" 579 "Value" 578 "Value" 577 "Value" 576 "Value" 575 "Value" 574 "Value" 573 "Value" 572 "Value" 571 "Value" 570 "Value" 569 "Value" 568 "Value" 567 "Value" 566 "Value" 565 "Value" 564 "Value" 563 "Value" 562 "Value" 561 "Value" 560 "Value" 559 "Value" 558 "Value" 557 "Value" 556 "Value" 555 "Value" 554 "Value" 553 "Value" 552 "Value" 551 "Value" 550 "Value" 549 "Value" 548 "Value" 547 "Value" 546 "Value" 545 "Value" 544 "Value" 543 "Value" 542 "Value" 541 "Value" 540 "Value" 539 "Value" 538 "Value" 537 "Value" 536 "Value" 535 "Value" 534 "Value" 533 "Value" 532 "Value" 531 "Value" 530 "Value" 529 "Value" 528 "Value" 527 "Value" 526 "Value" 525 "Value" 524 "Value" 523 "Value" 522 "Value" 521 "Value" 520 "Value" 519 "Value" 518 "Value" 517 "Value" 516 "Value" 515 "Value" 514 "Value" 513 "Value" 512 "Value" 511 "Value" 510 "Value" 509 "Value" 508 "Value" 507 "Value" 506 "Value" 505 "Value" 504 "Value" 503 "Value" 502 "Value" 501 "Value" 500 "Value" 499 "Value" 498 "Value" 497 "Value" 496 "Value" 495 "Value" 494 "Value" 493 "Value" 492 "Value" 491 "Value" 490 "Value" 489 "Value" 488 "Value" 487 "Value" 486 "Value" 485 "Value" 484 "Value" 483 "Value" 482 "Value" 481 "Value" 480 "Value" 479 "Value" 478 "Value" 477 "Value" 476 "Value" 475 "Value" 474 "Value" 473 "Value" 472 "Value" 471 "Value" 470 "Value" 469 "Value" 468 "Value" 467 "Value" 466 "Value" 465 "Value" 464 "Value" 463 "Value" 462 "Value" 461 "Value" 460 "Value" 459 "Value" 458 "Value" 457 "Value" 456 "Value" 455 "Value" 454 "Value" 453 "Value" 452 "Value" 451 "Value" 450 "Value" 449 "Value" 448 "Value" 447 "Value" 446 "Value" 445 "Value" 444 "Value" 443 "Value" 442 "Value" 441 "Value" 440 "Value" 439 "Value" 438 "Value" 437 "Value" 436 "Value" 435 "Value" 434 "Value" 433 "Value" 432 "Value" 431 "Value" 430 "Value" 429 "Value" 428 "Value" 427 "Value" 426 "Value" 425 "Value" 424 "Value" 423 "Value" 422 "Value" 421 "Value" 420 "Value" 419 "Value" 418 "Value" 417 "Value" 416 "Value" 415 "Value" 414 "Value" 413 "Value" 412 "Value" 411 "Value" 410 "Value" 409 "Value" 408 "Value" 407 "Value" 406 "Value" 405 "Value" 404 "Value" 403 "Value" 402 "Value" 401 "Value" 400 "Value" 399 "Value" 398 "Value" 397 "Value" 396 "Value" 395 "Value" 394 "Value" 393 "Value" 392 "Value" 391 "Value" 390 "Value" 389 "Value" 388 "Value" 387 "Value" 386 "Value" 385 "Value" 384 "Value" 383 "Value" 382 "Value" 381 "Value" 380 "Value" 379 "Value" 378 "Value" 377 "Value" 376 "Value" 375 "Value" 374 "Value" 373 "Value" 372 "Value" 371 "Value" 370 "Value" 369 "Value" 368 "Value" 367 "Value" 366 "Value" 365 "Value" 364 "Value" 363 "Value" 362 "Value" 361 "Value" 360 "Value" 359 "Value" 358 "Value" 357 "Value" 356 "Value" 355 "Value" 354 "Value" 353 "Value" 352 "Value" 351 "Value" 350 "Value" 349 "Value" 348 "Value" 347 "Value" 346 "Value" 345 "Value" 344 "Value" 343 "Value" 342 "Value" 341 "Value" 340 "Value" 339 "Value" 338 "Value" 337 "Value" 336 "Value" 335 "Value" 334 "Value" 333 "Value" 332 "Value" 331 "Value" 330 "Value" 329 "Value" 328 "Value" 327 "Value" 326 "Value" 325 "Value" 324 "Value" 323 "Value" 322 "Value" 321 "Value" 320 "Value" 319 "Value" 318 "Value" 317 "Value" 316 "Value" 315 "Value" 314 "Value" 313 "Value" 312 "Value" 311 "Value" 310 "Value" 309 "Value" 308 "Value" 307 "Value" 306 "Value" 305 "Value" 304 "Value" 303 "Value" 302 "Value" 301 "Value" 300 "Value" 299 "Value" 298 "Value" 297 "Value" 296 "Value" 295 "Value" 294 "Value" 293 "Value" 292 "Value" 291 "Value" 290 "Value" 289 "Value" 288 "Value" 287 "Value" 286 "Value" 285 "Value" 284 "Value" 283 "Value" 282 "Value" 281 "Value" 280 "Value" 279 "Value" 278 "Value" 277 "Value" 276 "Value" 275 "Value" 274 "Value" 273 "Value" 272 "Value" 271 "Value" 270 "Value" 269 "Value" 268 "Value" 267 "Value" 266 "Value" 265 "Value" 264 "Value" 263 "Value" 262 "Value" 261 "Value" 260 "Value" 259 "Value" 258 "Value" 257 "Value" 256 "Value" 255 "Value" 254 "Value" 253 "Value" 252 "Value" 251 "Value" 250 "Value" 249 "Value" 248 "Value" 247 "Value" 246 "Value" 245 "Value" 244 "Value" 243 "Value" 242 "Value" 241 "Value" 240 "Value" 239 "Value" 238 "Value" 237 "Value" 236 "Value" 235 "Value" 234 "Value" 233 "Value" 232 "Value" 231 "Value" 230 "Value" 229 "Value" 228 "Value" 227 "Value" 226 "Value" 225 "Value" 224 "Value" 223 "Value" 222 "Value" 221 "Value" 220 "Value" 219 "Value" 218 "Value" 217 "Value" 216 "Value" 215 "Value" 214 "Value" 213 "Value" 212 "Value" 211 "Value" 210 "Value" 209 "Value" 208 "Value" 207 "Value" 206 "Value" 205 "Value" 204 "Value" 203 "Value" 202 "Value" 201 "Value" 200 "Value" 199 "Value" 198 "Value" 197 "Value" 196 "Value" 195 "Value" 194 "Value" 193 "Value" 192 "Value" 191 "Value" 190 "Value" 189 "Value" 188 "Value" 187 "Value" 186 "Value" 185 "Value" 184 "Value" 183 "Value" 182 "Value" 181 "Value" 180 "Value" 179 "Value" 178 "Value" 177 "Value" 176 "Value" 175 "Value" 174 "Value" 173 "Value" 172 "Value" 171 "Value" 170 "Value" 169 "Value" 168 "Value" 167 "Value" 166 "Value" 165 "Value" 164 "Value" 163 "Value" 162 "Value" 161 "Value" 160 "Value" 159 "Value" 158 "Value" 157 "Value" 156 "Value" 155 "Value" 154 "Value" 153 "Value" 152 "Value" 151 "Value" 150 "Value" 149 "Value" 148 "Value" 147 "Value" 146 "Value" 145 "Value" 144 "Value" 143 "Value" 142 "Value" 141 "Value" 140 "Value" 139 "Value" 138 "Value" 137 "Value" 136 "Value" 135 "Value" 134 "Value" 133 "Value" 132 "Value" 131 "Value" 130 "Value" 129 "Value" 128 "Value" 127 "Value" 126 "Value" 125 "Value" 124 "Value" 123 "Value" 122 "Value" 121 "Value" 120 "Value" 119 "Value" 118 "Value" 117 "Value" 116 "Value" 115 "Value" 114 "Value" 113 "Value" 112 "Value" 111 "Value" 110 "Value" 109 "Value" 108 "Value" 107 "Value" 106 "Value" 105 "Value" 104 "Value" 103 "Value" 102 "Value" 101 "Value" 100 "Value" 99 "Value" 98 "Value" 97 "Value" 96 "Value" 95 "Value" 94 "Value" 93 "Value" 92 "Value" 91 "Value" 90 "Value" 89 "Value" 88 "Value" 87 "Value" 86 "Value" 85 "Value" 84 "Value" 83 "Value" 82 "Value" 81 "Value" 80 "Value" 79 "Value" 78 "Value" 77 "Value" 76 "Value" 75 "Value" 74 "Value" 73 "Value" 72 "Value" 71 "Value" 70 "Value" 69 "Value" 68 "Value" 67 "Value" 66 "Value" 65 "Value" 64 "Value" 63 "Value" 62 "Value" 61 "Value" 60 "Value" 59 "Value" 58 "Value" 57 "Value" 56 "Value" 55 "Value" 54 "Value" 53 "Value" 52 "Value" 51 "Value" 50 "Value" 49 "Value" 48 "Value" 47 "Value" 46 "Value" 45 "Value" 44 "Value" 43 "Value" 42 "Value" 41 "Value" 40 "Value" 39 "Value" 38 "Value" 37 "Value" 36 "Value" 35 "Value" 34 "Value" 33 "Value" 32 "Value" 31 "Value" 30 "Value" 29 "Value" 28 "Value" 27 "Value" 26 "Value" 25 "Value" 24 "Value" 23 "Value" 22 "Value" 21 "Value" 20 "Value" 19 "Value" 18 "Value" 17 "Value" 16 "Value" 15 "Value" 14 "Value" 13 "Value" 12 "Value" 11 "Value" 10 "Value" 9 "Value" 8 "Value" 7 "Value" 6 "Value" 5 "Value" 4 "Value" 3 "Value" 2 "Value" 1 "Value" 0 "Value" ;
VAL_ 563 ADCU3A_LatAcclVld 1 "Valid" 0 "Invalid" ;
VAL_ 563 ADCU3A_VertAccl 4095 "Invalid" 3000 "Value" 2999 "Value" 2998 "Value" 2997 "Value" 2996 "Value" 2995 "Value" 2994 "Value" 2993 "Value" 2992 "Value" 2991 "Value" 2990 "Value" 2989 "Value" 2988 "Value" 2987 "Value" 2986 "Value" 2985 "Value" 2984 "Value" 2983 "Value" 2982 "Value" 2981 "Value" 2980 "Value" 2979 "Value" 2978 "Value" 2977 "Value" 2976 "Value" 2975 "Value" 2974 "Value" 2973 "Value" 2972 "Value" 2971 "Value" 2970 "Value" 2969 "Value" 2968 "Value" 2967 "Value" 2966 "Value" 2965 "Value" 2964 "Value" 2963 "Value" 2962 "Value" 2961 "Value" 2960 "Value" 2959 "Value" 2958 "Value" 2957 "Value" 2956 "Value" 2955 "Value" 2954 "Value" 2953 "Value" 2952 "Value" 2951 "Value" 2950 "Value" 2949 "Value" 2948 "Value" 2947 "Value" 2946 "Value" 2945 "Value" 2944 "Value" 2943 "Value" 2942 "Value" 2941 "Value" 2940 "Value" 2939 "Value" 2938 "Value" 2937 "Value" 2936 "Value" 2935 "Value" 2934 "Value" 2933 "Value" 2932 "Value" 2931 "Value" 2930 "Value" 2929 "Value" 2928 "Value" 2927 "Value" 2926 "Value" 2925 "Value" 2924 "Value" 2923 "Value" 2922 "Value" 2921 "Value" 2920 "Value" 2919 "Value" 2918 "Value" 2917 "Value" 2916 "Value" 2915 "Value" 2914 "Value" 2913 "Value" 2912 "Value" 2911 "Value" 2910 "Value" 2909 "Value" 2908 "Value" 2907 "Value" 2906 "Value" 2905 "Value" 2904 "Value" 2903 "Value" 2902 "Value" 2901 "Value" 2900 "Value" 2899 "Value" 2898 "Value" 2897 "Value" 2896 "Value" 2895 "Value" 2894 "Value" 2893 "Value" 2892 "Value" 2891 "Value" 2890 "Value" 2889 "Value" 2888 "Value" 2887 "Value" 2886 "Value" 2885 "Value" 2884 "Value" 2883 "Value" 2882 "Value" 2881 "Value" 2880 "Value" 2879 "Value" 2878 "Value" 2877 "Value" 2876 "Value" 2875 "Value" 2874 "Value" 2873 "Value" 2872 "Value" 2871 "Value" 2870 "Value" 2869 "Value" 2868 "Value" 2867 "Value" 2866 "Value" 2865 "Value" 2864 "Value" 2863 "Value" 2862 "Value" 2861 "Value" 2860 "Value" 2859 "Value" 2858 "Value" 2857 "Value" 2856 "Value" 2855 "Value" 2854 "Value" 2853 "Value" 2852 "Value" 2851 "Value" 2850 "Value" 2849 "Value" 2848 "Value" 2847 "Value" 2846 "Value" 2845 "Value" 2844 "Value" 2843 "Value" 2842 "Value" 2841 "Value" 2840 "Value" 2839 "Value" 2838 "Value" 2837 "Value" 2836 "Value" 2835 "Value" 2834 "Value" 2833 "Value" 2832 "Value" 2831 "Value" 2830 "Value" 2829 "Value" 2828 "Value" 2827 "Value" 2826 "Value" 2825 "Value" 2824 "Value" 2823 "Value" 2822 "Value" 2821 "Value" 2820 "Value" 2819 "Value" 2818 "Value" 2817 "Value" 2816 "Value" 2815 "Value" 2814 "Value" 2813 "Value" 2812 "Value" 2811 "Value" 2810 "Value" 2809 "Value" 2808 "Value" 2807 "Value" 2806 "Value" 2805 "Value" 2804 "Value" 2803 "Value" 2802 "Value" 2801 "Value" 2800 "Value" 2799 "Value" 2798 "Value" 2797 "Value" 2796 "Value" 2795 "Value" 2794 "Value" 2793 "Value" 2792 "Value" 2791 "Value" 2790 "Value" 2789 "Value" 2788 "Value" 2787 "Value" 2786 "Value" 2785 "Value" 2784 "Value" 2783 "Value" 2782 "Value" 2781 "Value" 2780 "Value" 2779 "Value" 2778 "Value" 2777 "Value" 2776 "Value" 2775 "Value" 2774 "Value" 2773 "Value" 2772 "Value" 2771 "Value" 2770 "Value" 2769 "Value" 2768 "Value" 2767 "Value" 2766 "Value" 2765 "Value" 2764 "Value" 2763 "Value" 2762 "Value" 2761 "Value" 2760 "Value" 2759 "Value" 2758 "Value" 2757 "Value" 2756 "Value" 2755 "Value" 2754 "Value" 2753 "Value" 2752 "Value" 2751 "Value" 2750 "Value" 2749 "Value" 2748 "Value" 2747 "Value" 2746 "Value" 2745 "Value" 2744 "Value" 2743 "Value" 2742 "Value" 2741 "Value" 2740 "Value" 2739 "Value" 2738 "Value" 2737 "Value" 2736 "Value" 2735 "Value" 2734 "Value" 2733 "Value" 2732 "Value" 2731 "Value" 2730 "Value" 2729 "Value" 2728 "Value" 2727 "Value" 2726 "Value" 2725 "Value" 2724 "Value" 2723 "Value" 2722 "Value" 2721 "Value" 2720 "Value" 2719 "Value" 2718 "Value" 2717 "Value" 2716 "Value" 2715 "Value" 2714 "Value" 2713 "Value" 2712 "Value" 2711 "Value" 2710 "Value" 2709 "Value" 2708 "Value" 2707 "Value" 2706 "Value" 2705 "Value" 2704 "Value" 2703 "Value" 2702 "Value" 2701 "Value" 2700 "Value" 2699 "Value" 2698 "Value" 2697 "Value" 2696 "Value" 2695 "Value" 2694 "Value" 2693 "Value" 2692 "Value" 2691 "Value" 2690 "Value" 2689 "Value" 2688 "Value" 2687 "Value" 2686 "Value" 2685 "Value" 2684 "Value" 2683 "Value" 2682 "Value" 2681 "Value" 2680 "Value" 2679 "Value" 2678 "Value" 2677 "Value" 2676 "Value" 2675 "Value" 2674 "Value" 2673 "Value" 2672 "Value" 2671 "Value" 2670 "Value" 2669 "Value" 2668 "Value" 2667 "Value" 2666 "Value" 2665 "Value" 2664 "Value" 2663 "Value" 2662 "Value" 2661 "Value" 2660 "Value" 2659 "Value" 2658 "Value" 2657 "Value" 2656 "Value" 2655 "Value" 2654 "Value" 2653 "Value" 2652 "Value" 2651 "Value" 2650 "Value" 2649 "Value" 2648 "Value" 2647 "Value" 2646 "Value" 2645 "Value" 2644 "Value" 2643 "Value" 2642 "Value" 2641 "Value" 2640 "Value" 2639 "Value" 2638 "Value" 2637 "Value" 2636 "Value" 2635 "Value" 2634 "Value" 2633 "Value" 2632 "Value" 2631 "Value" 2630 "Value" 2629 "Value" 2628 "Value" 2627 "Value" 2626 "Value" 2625 "Value" 2624 "Value" 2623 "Value" 2622 "Value" 2621 "Value" 2620 "Value" 2619 "Value" 2618 "Value" 2617 "Value" 2616 "Value" 2615 "Value" 2614 "Value" 2613 "Value" 2612 "Value" 2611 "Value" 2610 "Value" 2609 "Value" 2608 "Value" 2607 "Value" 2606 "Value" 2605 "Value" 2604 "Value" 2603 "Value" 2602 "Value" 2601 "Value" 2600 "Value" 2599 "Value" 2598 "Value" 2597 "Value" 2596 "Value" 2595 "Value" 2594 "Value" 2593 "Value" 2592 "Value" 2591 "Value" 2590 "Value" 2589 "Value" 2588 "Value" 2587 "Value" 2586 "Value" 2585 "Value" 2584 "Value" 2583 "Value" 2582 "Value" 2581 "Value" 2580 "Value" 2579 "Value" 2578 "Value" 2577 "Value" 2576 "Value" 2575 "Value" 2574 "Value" 2573 "Value" 2572 "Value" 2571 "Value" 2570 "Value" 2569 "Value" 2568 "Value" 2567 "Value" 2566 "Value" 2565 "Value" 2564 "Value" 2563 "Value" 2562 "Value" 2561 "Value" 2560 "Value" 2559 "Value" 2558 "Value" 2557 "Value" 2556 "Value" 2555 "Value" 2554 "Value" 2553 "Value" 2552 "Value" 2551 "Value" 2550 "Value" 2549 "Value" 2548 "Value" 2547 "Value" 2546 "Value" 2545 "Value" 2544 "Value" 2543 "Value" 2542 "Value" 2541 "Value" 2540 "Value" 2539 "Value" 2538 "Value" 2537 "Value" 2536 "Value" 2535 "Value" 2534 "Value" 2533 "Value" 2532 "Value" 2531 "Value" 2530 "Value" 2529 "Value" 2528 "Value" 2527 "Value" 2526 "Value" 2525 "Value" 2524 "Value" 2523 "Value" 2522 "Value" 2521 "Value" 2520 "Value" 2519 "Value" 2518 "Value" 2517 "Value" 2516 "Value" 2515 "Value" 2514 "Value" 2513 "Value" 2512 "Value" 2511 "Value" 2510 "Value" 2509 "Value" 2508 "Value" 2507 "Value" 2506 "Value" 2505 "Value" 2504 "Value" 2503 "Value" 2502 "Value" 2501 "Value" 2500 "Value" 2499 "Value" 2498 "Value" 2497 "Value" 2496 "Value" 2495 "Value" 2494 "Value" 2493 "Value" 2492 "Value" 2491 "Value" 2490 "Value" 2489 "Value" 2488 "Value" 2487 "Value" 2486 "Value" 2485 "Value" 2484 "Value" 2483 "Value" 2482 "Value" 2481 "Value" 2480 "Value" 2479 "Value" 2478 "Value" 2477 "Value" 2476 "Value" 2475 "Value" 2474 "Value" 2473 "Value" 2472 "Value" 2471 "Value" 2470 "Value" 2469 "Value" 2468 "Value" 2467 "Value" 2466 "Value" 2465 "Value" 2464 "Value" 2463 "Value" 2462 "Value" 2461 "Value" 2460 "Value" 2459 "Value" 2458 "Value" 2457 "Value" 2456 "Value" 2455 "Value" 2454 "Value" 2453 "Value" 2452 "Value" 2451 "Value" 2450 "Value" 2449 "Value" 2448 "Value" 2447 "Value" 2446 "Value" 2445 "Value" 2444 "Value" 2443 "Value" 2442 "Value" 2441 "Value" 2440 "Value" 2439 "Value" 2438 "Value" 2437 "Value" 2436 "Value" 2435 "Value" 2434 "Value" 2433 "Value" 2432 "Value" 2431 "Value" 2430 "Value" 2429 "Value" 2428 "Value" 2427 "Value" 2426 "Value" 2425 "Value" 2424 "Value" 2423 "Value" 2422 "Value" 2421 "Value" 2420 "Value" 2419 "Value" 2418 "Value" 2417 "Value" 2416 "Value" 2415 "Value" 2414 "Value" 2413 "Value" 2412 "Value" 2411 "Value" 2410 "Value" 2409 "Value" 2408 "Value" 2407 "Value" 2406 "Value" 2405 "Value" 2404 "Value" 2403 "Value" 2402 "Value" 2401 "Value" 2400 "Value" 2399 "Value" 2398 "Value" 2397 "Value" 2396 "Value" 2395 "Value" 2394 "Value" 2393 "Value" 2392 "Value" 2391 "Value" 2390 "Value" 2389 "Value" 2388 "Value" 2387 "Value" 2386 "Value" 2385 "Value" 2384 "Value" 2383 "Value" 2382 "Value" 2381 "Value" 2380 "Value" 2379 "Value" 2378 "Value" 2377 "Value" 2376 "Value" 2375 "Value" 2374 "Value" 2373 "Value" 2372 "Value" 2371 "Value" 2370 "Value" 2369 "Value" 2368 "Value" 2367 "Value" 2366 "Value" 2365 "Value" 2364 "Value" 2363 "Value" 2362 "Value" 2361 "Value" 2360 "Value" 2359 "Value" 2358 "Value" 2357 "Value" 2356 "Value" 2355 "Value" 2354 "Value" 2353 "Value" 2352 "Value" 2351 "Value" 2350 "Value" 2349 "Value" 2348 "Value" 2347 "Value" 2346 "Value" 2345 "Value" 2344 "Value" 2343 "Value" 2342 "Value" 2341 "Value" 2340 "Value" 2339 "Value" 2338 "Value" 2337 "Value" 2336 "Value" 2335 "Value" 2334 "Value" 2333 "Value" 2332 "Value" 2331 "Value" 2330 "Value" 2329 "Value" 2328 "Value" 2327 "Value" 2326 "Value" 2325 "Value" 2324 "Value" 2323 "Value" 2322 "Value" 2321 "Value" 2320 "Value" 2319 "Value" 2318 "Value" 2317 "Value" 2316 "Value" 2315 "Value" 2314 "Value" 2313 "Value" 2312 "Value" 2311 "Value" 2310 "Value" 2309 "Value" 2308 "Value" 2307 "Value" 2306 "Value" 2305 "Value" 2304 "Value" 2303 "Value" 2302 "Value" 2301 "Value" 2300 "Value" 2299 "Value" 2298 "Value" 2297 "Value" 2296 "Value" 2295 "Value" 2294 "Value" 2293 "Value" 2292 "Value" 2291 "Value" 2290 "Value" 2289 "Value" 2288 "Value" 2287 "Value" 2286 "Value" 2285 "Value" 2284 "Value" 2283 "Value" 2282 "Value" 2281 "Value" 2280 "Value" 2279 "Value" 2278 "Value" 2277 "Value" 2276 "Value" 2275 "Value" 2274 "Value" 2273 "Value" 2272 "Value" 2271 "Value" 2270 "Value" 2269 "Value" 2268 "Value" 2267 "Value" 2266 "Value" 2265 "Value" 2264 "Value" 2263 "Value" 2262 "Value" 2261 "Value" 2260 "Value" 2259 "Value" 2258 "Value" 2257 "Value" 2256 "Value" 2255 "Value" 2254 "Value" 2253 "Value" 2252 "Value" 2251 "Value" 2250 "Value" 2249 "Value" 2248 "Value" 2247 "Value" 2246 "Value" 2245 "Value" 2244 "Value" 2243 "Value" 2242 "Value" 2241 "Value" 2240 "Value" 2239 "Value" 2238 "Value" 2237 "Value" 2236 "Value" 2235 "Value" 2234 "Value" 2233 "Value" 2232 "Value" 2231 "Value" 2230 "Value" 2229 "Value" 2228 "Value" 2227 "Value" 2226 "Value" 2225 "Value" 2224 "Value" 2223 "Value" 2222 "Value" 2221 "Value" 2220 "Value" 2219 "Value" 2218 "Value" 2217 "Value" 2216 "Value" 2215 "Value" 2214 "Value" 2213 "Value" 2212 "Value" 2211 "Value" 2210 "Value" 2209 "Value" 2208 "Value" 2207 "Value" 2206 "Value" 2205 "Value" 2204 "Value" 2203 "Value" 2202 "Value" 2201 "Value" 2200 "Value" 2199 "Value" 2198 "Value" 2197 "Value" 2196 "Value" 2195 "Value" 2194 "Value" 2193 "Value" 2192 "Value" 2191 "Value" 2190 "Value" 2189 "Value" 2188 "Value" 2187 "Value" 2186 "Value" 2185 "Value" 2184 "Value" 2183 "Value" 2182 "Value" 2181 "Value" 2180 "Value" 2179 "Value" 2178 "Value" 2177 "Value" 2176 "Value" 2175 "Value" 2174 "Value" 2173 "Value" 2172 "Value" 2171 "Value" 2170 "Value" 2169 "Value" 2168 "Value" 2167 "Value" 2166 "Value" 2165 "Value" 2164 "Value" 2163 "Value" 2162 "Value" 2161 "Value" 2160 "Value" 2159 "Value" 2158 "Value" 2157 "Value" 2156 "Value" 2155 "Value" 2154 "Value" 2153 "Value" 2152 "Value" 2151 "Value" 2150 "Value" 2149 "Value" 2148 "Value" 2147 "Value" 2146 "Value" 2145 "Value" 2144 "Value" 2143 "Value" 2142 "Value" 2141 "Value" 2140 "Value" 2139 "Value" 2138 "Value" 2137 "Value" 2136 "Value" 2135 "Value" 2134 "Value" 2133 "Value" 2132 "Value" 2131 "Value" 2130 "Value" 2129 "Value" 2128 "Value" 2127 "Value" 2126 "Value" 2125 "Value" 2124 "Value" 2123 "Value" 2122 "Value" 2121 "Value" 2120 "Value" 2119 "Value" 2118 "Value" 2117 "Value" 2116 "Value" 2115 "Value" 2114 "Value" 2113 "Value" 2112 "Value" 2111 "Value" 2110 "Value" 2109 "Value" 2108 "Value" 2107 "Value" 2106 "Value" 2105 "Value" 2104 "Value" 2103 "Value" 2102 "Value" 2101 "Value" 2100 "Value" 2099 "Value" 2098 "Value" 2097 "Value" 2096 "Value" 2095 "Value" 2094 "Value" 2093 "Value" 2092 "Value" 2091 "Value" 2090 "Value" 2089 "Value" 2088 "Value" 2087 "Value" 2086 "Value" 2085 "Value" 2084 "Value" 2083 "Value" 2082 "Value" 2081 "Value" 2080 "Value" 2079 "Value" 2078 "Value" 2077 "Value" 2076 "Value" 2075 "Value" 2074 "Value" 2073 "Value" 2072 "Value" 2071 "Value" 2070 "Value" 2069 "Value" 2068 "Value" 2067 "Value" 2066 "Value" 2065 "Value" 2064 "Value" 2063 "Value" 2062 "Value" 2061 "Value" 2060 "Value" 2059 "Value" 2058 "Value" 2057 "Value" 2056 "Value" 2055 "Value" 2054 "Value" 2053 "Value" 2052 "Value" 2051 "Value" 2050 "Value" 2049 "Value" 2048 "Value" 2047 "Value" 2046 "Value" 2045 "Value" 2044 "Value" 2043 "Value" 2042 "Value" 2041 "Value" 2040 "Value" 2039 "Value" 2038 "Value" 2037 "Value" 2036 "Value" 2035 "Value" 2034 "Value" 2033 "Value" 2032 "Value" 2031 "Value" 2030 "Value" 2029 "Value" 2028 "Value" 2027 "Value" 2026 "Value" 2025 "Value" 2024 "Value" 2023 "Value" 2022 "Value" 2021 "Value" 2020 "Value" 2019 "Value" 2018 "Value" 2017 "Value" 2016 "Value" 2015 "Value" 2014 "Value" 2013 "Value" 2012 "Value" 2011 "Value" 2010 "Value" 2009 "Value" 2008 "Value" 2007 "Value" 2006 "Value" 2005 "Value" 2004 "Value" 2003 "Value" 2002 "Value" 2001 "Value" 2000 "Value" 1999 "Value" 1998 "Value" 1997 "Value" 1996 "Value" 1995 "Value" 1994 "Value" 1993 "Value" 1992 "Value" 1991 "Value" 1990 "Value" 1989 "Value" 1988 "Value" 1987 "Value" 1986 "Value" 1985 "Value" 1984 "Value" 1983 "Value" 1982 "Value" 1981 "Value" 1980 "Value" 1979 "Value" 1978 "Value" 1977 "Value" 1976 "Value" 1975 "Value" 1974 "Value" 1973 "Value" 1972 "Value" 1971 "Value" 1970 "Value" 1969 "Value" 1968 "Value" 1967 "Value" 1966 "Value" 1965 "Value" 1964 "Value" 1963 "Value" 1962 "Value" 1961 "Value" 1960 "Value" 1959 "Value" 1958 "Value" 1957 "Value" 1956 "Value" 1955 "Value" 1954 "Value" 1953 "Value" 1952 "Value" 1951 "Value" 1950 "Value" 1949 "Value" 1948 "Value" 1947 "Value" 1946 "Value" 1945 "Value" 1944 "Value" 1943 "Value" 1942 "Value" 1941 "Value" 1940 "Value" 1939 "Value" 1938 "Value" 1937 "Value" 1936 "Value" 1935 "Value" 1934 "Value" 1933 "Value" 1932 "Value" 1931 "Value" 1930 "Value" 1929 "Value" 1928 "Value" 1927 "Value" 1926 "Value" 1925 "Value" 1924 "Value" 1923 "Value" 1922 "Value" 1921 "Value" 1920 "Value" 1919 "Value" 1918 "Value" 1917 "Value" 1916 "Value" 1915 "Value" 1914 "Value" 1913 "Value" 1912 "Value" 1911 "Value" 1910 "Value" 1909 "Value" 1908 "Value" 1907 "Value" 1906 "Value" 1905 "Value" 1904 "Value" 1903 "Value" 1902 "Value" 1901 "Value" 1900 "Value" 1899 "Value" 1898 "Value" 1897 "Value" 1896 "Value" 1895 "Value" 1894 "Value" 1893 "Value" 1892 "Value" 1891 "Value" 1890 "Value" 1889 "Value" 1888 "Value" 1887 "Value" 1886 "Value" 1885 "Value" 1884 "Value" 1883 "Value" 1882 "Value" 1881 "Value" 1880 "Value" 1879 "Value" 1878 "Value" 1877 "Value" 1876 "Value" 1875 "Value" 1874 "Value" 1873 "Value" 1872 "Value" 1871 "Value" 1870 "Value" 1869 "Value" 1868 "Value" 1867 "Value" 1866 "Value" 1865 "Value" 1864 "Value" 1863 "Value" 1862 "Value" 1861 "Value" 1860 "Value" 1859 "Value" 1858 "Value" 1857 "Value" 1856 "Value" 1855 "Value" 1854 "Value" 1853 "Value" 1852 "Value" 1851 "Value" 1850 "Value" 1849 "Value" 1848 "Value" 1847 "Value" 1846 "Value" 1845 "Value" 1844 "Value" 1843 "Value" 1842 "Value" 1841 "Value" 1840 "Value" 1839 "Value" 1838 "Value" 1837 "Value" 1836 "Value" 1835 "Value" 1834 "Value" 1833 "Value" 1832 "Value" 1831 "Value" 1830 "Value" 1829 "Value" 1828 "Value" 1827 "Value" 1826 "Value" 1825 "Value" 1824 "Value" 1823 "Value" 1822 "Value" 1821 "Value" 1820 "Value" 1819 "Value" 1818 "Value" 1817 "Value" 1816 "Value" 1815 "Value" 1814 "Value" 1813 "Value" 1812 "Value" 1811 "Value" 1810 "Value" 1809 "Value" 1808 "Value" 1807 "Value" 1806 "Value" 1805 "Value" 1804 "Value" 1803 "Value" 1802 "Value" 1801 "Value" 1800 "Value" 1799 "Value" 1798 "Value" 1797 "Value" 1796 "Value" 1795 "Value" 1794 "Value" 1793 "Value" 1792 "Value" 1791 "Value" 1790 "Value" 1789 "Value" 1788 "Value" 1787 "Value" 1786 "Value" 1785 "Value" 1784 "Value" 1783 "Value" 1782 "Value" 1781 "Value" 1780 "Value" 1779 "Value" 1778 "Value" 1777 "Value" 1776 "Value" 1775 "Value" 1774 "Value" 1773 "Value" 1772 "Value" 1771 "Value" 1770 "Value" 1769 "Value" 1768 "Value" 1767 "Value" 1766 "Value" 1765 "Value" 1764 "Value" 1763 "Value" 1762 "Value" 1761 "Value" 1760 "Value" 1759 "Value" 1758 "Value" 1757 "Value" 1756 "Value" 1755 "Value" 1754 "Value" 1753 "Value" 1752 "Value" 1751 "Value" 1750 "Value" 1749 "Value" 1748 "Value" 1747 "Value" 1746 "Value" 1745 "Value" 1744 "Value" 1743 "Value" 1742 "Value" 1741 "Value" 1740 "Value" 1739 "Value" 1738 "Value" 1737 "Value" 1736 "Value" 1735 "Value" 1734 "Value" 1733 "Value" 1732 "Value" 1731 "Value" 1730 "Value" 1729 "Value" 1728 "Value" 1727 "Value" 1726 "Value" 1725 "Value" 1724 "Value" 1723 "Value" 1722 "Value" 1721 "Value" 1720 "Value" 1719 "Value" 1718 "Value" 1717 "Value" 1716 "Value" 1715 "Value" 1714 "Value" 1713 "Value" 1712 "Value" 1711 "Value" 1710 "Value" 1709 "Value" 1708 "Value" 1707 "Value" 1706 "Value" 1705 "Value" 1704 "Value" 1703 "Value" 1702 "Value" 1701 "Value" 1700 "Value" 1699 "Value" 1698 "Value" 1697 "Value" 1696 "Value" 1695 "Value" 1694 "Value" 1693 "Value" 1692 "Value" 1691 "Value" 1690 "Value" 1689 "Value" 1688 "Value" 1687 "Value" 1686 "Value" 1685 "Value" 1684 "Value" 1683 "Value" 1682 "Value" 1681 "Value" 1680 "Value" 1679 "Value" 1678 "Value" 1677 "Value" 1676 "Value" 1675 "Value" 1674 "Value" 1673 "Value" 1672 "Value" 1671 "Value" 1670 "Value" 1669 "Value" 1668 "Value" 1667 "Value" 1666 "Value" 1665 "Value" 1664 "Value" 1663 "Value" 1662 "Value" 1661 "Value" 1660 "Value" 1659 "Value" 1658 "Value" 1657 "Value" 1656 "Value" 1655 "Value" 1654 "Value" 1653 "Value" 1652 "Value" 1651 "Value" 1650 "Value" 1649 "Value" 1648 "Value" 1647 "Value" 1646 "Value" 1645 "Value" 1644 "Value" 1643 "Value" 1642 "Value" 1641 "Value" 1640 "Value" 1639 "Value" 1638 "Value" 1637 "Value" 1636 "Value" 1635 "Value" 1634 "Value" 1633 "Value" 1632 "Value" 1631 "Value" 1630 "Value" 1629 "Value" 1628 "Value" 1627 "Value" 1626 "Value" 1625 "Value" 1624 "Value" 1623 "Value" 1622 "Value" 1621 "Value" 1620 "Value" 1619 "Value" 1618 "Value" 1617 "Value" 1616 "Value" 1615 "Value" 1614 "Value" 1613 "Value" 1612 "Value" 1611 "Value" 1610 "Value" 1609 "Value" 1608 "Value" 1607 "Value" 1606 "Value" 1605 "Value" 1604 "Value" 1603 "Value" 1602 "Value" 1601 "Value" 1600 "Value" 1599 "Value" 1598 "Value" 1597 "Value" 1596 "Value" 1595 "Value" 1594 "Value" 1593 "Value" 1592 "Value" 1591 "Value" 1590 "Value" 1589 "Value" 1588 "Value" 1587 "Value" 1586 "Value" 1585 "Value" 1584 "Value" 1583 "Value" 1582 "Value" 1581 "Value" 1580 "Value" 1579 "Value" 1578 "Value" 1577 "Value" 1576 "Value" 1575 "Value" 1574 "Value" 1573 "Value" 1572 "Value" 1571 "Value" 1570 "Value" 1569 "Value" 1568 "Value" 1567 "Value" 1566 "Value" 1565 "Value" 1564 "Value" 1563 "Value" 1562 "Value" 1561 "Value" 1560 "Value" 1559 "Value" 1558 "Value" 1557 "Value" 1556 "Value" 1555 "Value" 1554 "Value" 1553 "Value" 1552 "Value" 1551 "Value" 1550 "Value" 1549 "Value" 1548 "Value" 1547 "Value" 1546 "Value" 1545 "Value" 1544 "Value" 1543 "Value" 1542 "Value" 1541 "Value" 1540 "Value" 1539 "Value" 1538 "Value" 1537 "Value" 1536 "Value" 1535 "Value" 1534 "Value" 1533 "Value" 1532 "Value" 1531 "Value" 1530 "Value" 1529 "Value" 1528 "Value" 1527 "Value" 1526 "Value" 1525 "Value" 1524 "Value" 1523 "Value" 1522 "Value" 1521 "Value" 1520 "Value" 1519 "Value" 1518 "Value" 1517 "Value" 1516 "Value" 1515 "Value" 1514 "Value" 1513 "Value" 1512 "Value" 1511 "Value" 1510 "Value" 1509 "Value" 1508 "Value" 1507 "Value" 1506 "Value" 1505 "Value" 1504 "Value" 1503 "Value" 1502 "Value" 1501 "Value" 1500 "Value" 1499 "Value" 1498 "Value" 1497 "Value" 1496 "Value" 1495 "Value" 1494 "Value" 1493 "Value" 1492 "Value" 1491 "Value" 1490 "Value" 1489 "Value" 1488 "Value" 1487 "Value" 1486 "Value" 1485 "Value" 1484 "Value" 1483 "Value" 1482 "Value" 1481 "Value" 1480 "Value" 1479 "Value" 1478 "Value" 1477 "Value" 1476 "Value" 1475 "Value" 1474 "Value" 1473 "Value" 1472 "Value" 1471 "Value" 1470 "Value" 1469 "Value" 1468 "Value" 1467 "Value" 1466 "Value" 1465 "Value" 1464 "Value" 1463 "Value" 1462 "Value" 1461 "Value" 1460 "Value" 1459 "Value" 1458 "Value" 1457 "Value" 1456 "Value" 1455 "Value" 1454 "Value" 1453 "Value" 1452 "Value" 1451 "Value" 1450 "Value" 1449 "Value" 1448 "Value" 1447 "Value" 1446 "Value" 1445 "Value" 1444 "Value" 1443 "Value" 1442 "Value" 1441 "Value" 1440 "Value" 1439 "Value" 1438 "Value" 1437 "Value" 1436 "Value" 1435 "Value" 1434 "Value" 1433 "Value" 1432 "Value" 1431 "Value" 1430 "Value" 1429 "Value" 1428 "Value" 1427 "Value" 1426 "Value" 1425 "Value" 1424 "Value" 1423 "Value" 1422 "Value" 1421 "Value" 1420 "Value" 1419 "Value" 1418 "Value" 1417 "Value" 1416 "Value" 1415 "Value" 1414 "Value" 1413 "Value" 1412 "Value" 1411 "Value" 1410 "Value" 1409 "Value" 1408 "Value" 1407 "Value" 1406 "Value" 1405 "Value" 1404 "Value" 1403 "Value" 1402 "Value" 1401 "Value" 1400 "Value" 1399 "Value" 1398 "Value" 1397 "Value" 1396 "Value" 1395 "Value" 1394 "Value" 1393 "Value" 1392 "Value" 1391 "Value" 1390 "Value" 1389 "Value" 1388 "Value" 1387 "Value" 1386 "Value" 1385 "Value" 1384 "Value" 1383 "Value" 1382 "Value" 1381 "Value" 1380 "Value" 1379 "Value" 1378 "Value" 1377 "Value" 1376 "Value" 1375 "Value" 1374 "Value" 1373 "Value" 1372 "Value" 1371 "Value" 1370 "Value" 1369 "Value" 1368 "Value" 1367 "Value" 1366 "Value" 1365 "Value" 1364 "Value" 1363 "Value" 1362 "Value" 1361 "Value" 1360 "Value" 1359 "Value" 1358 "Value" 1357 "Value" 1356 "Value" 1355 "Value" 1354 "Value" 1353 "Value" 1352 "Value" 1351 "Value" 1350 "Value" 1349 "Value" 1348 "Value" 1347 "Value" 1346 "Value" 1345 "Value" 1344 "Value" 1343 "Value" 1342 "Value" 1341 "Value" 1340 "Value" 1339 "Value" 1338 "Value" 1337 "Value" 1336 "Value" 1335 "Value" 1334 "Value" 1333 "Value" 1332 "Value" 1331 "Value" 1330 "Value" 1329 "Value" 1328 "Value" 1327 "Value" 1326 "Value" 1325 "Value" 1324 "Value" 1323 "Value" 1322 "Value" 1321 "Value" 1320 "Value" 1319 "Value" 1318 "Value" 1317 "Value" 1316 "Value" 1315 "Value" 1314 "Value" 1313 "Value" 1312 "Value" 1311 "Value" 1310 "Value" 1309 "Value" 1308 "Value" 1307 "Value" 1306 "Value" 1305 "Value" 1304 "Value" 1303 "Value" 1302 "Value" 1301 "Value" 1300 "Value" 1299 "Value" 1298 "Value" 1297 "Value" 1296 "Value" 1295 "Value" 1294 "Value" 1293 "Value" 1292 "Value" 1291 "Value" 1290 "Value" 1289 "Value" 1288 "Value" 1287 "Value" 1286 "Value" 1285 "Value" 1284 "Value" 1283 "Value" 1282 "Value" 1281 "Value" 1280 "Value" 1279 "Value" 1278 "Value" 1277 "Value" 1276 "Value" 1275 "Value" 1274 "Value" 1273 "Value" 1272 "Value" 1271 "Value" 1270 "Value" 1269 "Value" 1268 "Value" 1267 "Value" 1266 "Value" 1265 "Value" 1264 "Value" 1263 "Value" 1262 "Value" 1261 "Value" 1260 "Value" 1259 "Value" 1258 "Value" 1257 "Value" 1256 "Value" 1255 "Value" 1254 "Value" 1253 "Value" 1252 "Value" 1251 "Value" 1250 "Value" 1249 "Value" 1248 "Value" 1247 "Value" 1246 "Value" 1245 "Value" 1244 "Value" 1243 "Value" 1242 "Value" 1241 "Value" 1240 "Value" 1239 "Value" 1238 "Value" 1237 "Value" 1236 "Value" 1235 "Value" 1234 "Value" 1233 "Value" 1232 "Value" 1231 "Value" 1230 "Value" 1229 "Value" 1228 "Value" 1227 "Value" 1226 "Value" 1225 "Value" 1224 "Value" 1223 "Value" 1222 "Value" 1221 "Value" 1220 "Value" 1219 "Value" 1218 "Value" 1217 "Value" 1216 "Value" 1215 "Value" 1214 "Value" 1213 "Value" 1212 "Value" 1211 "Value" 1210 "Value" 1209 "Value" 1208 "Value" 1207 "Value" 1206 "Value" 1205 "Value" 1204 "Value" 1203 "Value" 1202 "Value" 1201 "Value" 1200 "Value" 1199 "Value" 1198 "Value" 1197 "Value" 1196 "Value" 1195 "Value" 1194 "Value" 1193 "Value" 1192 "Value" 1191 "Value" 1190 "Value" 1189 "Value" 1188 "Value" 1187 "Value" 1186 "Value" 1185 "Value" 1184 "Value" 1183 "Value" 1182 "Value" 1181 "Value" 1180 "Value" 1179 "Value" 1178 "Value" 1177 "Value" 1176 "Value" 1175 "Value" 1174 "Value" 1173 "Value" 1172 "Value" 1171 "Value" 1170 "Value" 1169 "Value" 1168 "Value" 1167 "Value" 1166 "Value" 1165 "Value" 1164 "Value" 1163 "Value" 1162 "Value" 1161 "Value" 1160 "Value" 1159 "Value" 1158 "Value" 1157 "Value" 1156 "Value" 1155 "Value" 1154 "Value" 1153 "Value" 1152 "Value" 1151 "Value" 1150 "Value" 1149 "Value" 1148 "Value" 1147 "Value" 1146 "Value" 1145 "Value" 1144 "Value" 1143 "Value" 1142 "Value" 1141 "Value" 1140 "Value" 1139 "Value" 1138 "Value" 1137 "Value" 1136 "Value" 1135 "Value" 1134 "Value" 1133 "Value" 1132 "Value" 1131 "Value" 1130 "Value" 1129 "Value" 1128 "Value" 1127 "Value" 1126 "Value" 1125 "Value" 1124 "Value" 1123 "Value" 1122 "Value" 1121 "Value" 1120 "Value" 1119 "Value" 1118 "Value" 1117 "Value" 1116 "Value" 1115 "Value" 1114 "Value" 1113 "Value" 1112 "Value" 1111 "Value" 1110 "Value" 1109 "Value" 1108 "Value" 1107 "Value" 1106 "Value" 1105 "Value" 1104 "Value" 1103 "Value" 1102 "Value" 1101 "Value" 1100 "Value" 1099 "Value" 1098 "Value" 1097 "Value" 1096 "Value" 1095 "Value" 1094 "Value" 1093 "Value" 1092 "Value" 1091 "Value" 1090 "Value" 1089 "Value" 1088 "Value" 1087 "Value" 1086 "Value" 1085 "Value" 1084 "Value" 1083 "Value" 1082 "Value" 1081 "Value" 1080 "Value" 1079 "Value" 1078 "Value" 1077 "Value" 1076 "Value" 1075 "Value" 1074 "Value" 1073 "Value" 1072 "Value" 1071 "Value" 1070 "Value" 1069 "Value" 1068 "Value" 1067 "Value" 1066 "Value" 1065 "Value" 1064 "Value" 1063 "Value" 1062 "Value" 1061 "Value" 1060 "Value" 1059 "Value" 1058 "Value" 1057 "Value" 1056 "Value" 1055 "Value" 1054 "Value" 1053 "Value" 1052 "Value" 1051 "Value" 1050 "Value" 1049 "Value" 1048 "Value" 1047 "Value" 1046 "Value" 1045 "Value" 1044 "Value" 1043 "Value" 1042 "Value" 1041 "Value" 1040 "Value" 1039 "Value" 1038 "Value" 1037 "Value" 1036 "Value" 1035 "Value" 1034 "Value" 1033 "Value" 1032 "Value" 1031 "Value" 1030 "Value" 1029 "Value" 1028 "Value" 1027 "Value" 1026 "Value" 1025 "Value" 1024 "Value" 1023 "Value" 1022 "Value" 1021 "Value" 1020 "Value" 1019 "Value" 1018 "Value" 1017 "Value" 1016 "Value" 1015 "Value" 1014 "Value" 1013 "Value" 1012 "Value" 1011 "Value" 1010 "Value" 1009 "Value" 1008 "Value" 1007 "Value" 1006 "Value" 1005 "Value" 1004 "Value" 1003 "Value" 1002 "Value" 1001 "Value" 1000 "Value" 999 "Value" 998 "Value" 997 "Value" 996 "Value" 995 "Value" 994 "Value" 993 "Value" 992 "Value" 991 "Value" 990 "Value" 989 "Value" 988 "Value" 987 "Value" 986 "Value" 985 "Value" 984 "Value" 983 "Value" 982 "Value" 981 "Value" 980 "Value" 979 "Value" 978 "Value" 977 "Value" 976 "Value" 975 "Value" 974 "Value" 973 "Value" 972 "Value" 971 "Value" 970 "Value" 969 "Value" 968 "Value" 967 "Value" 966 "Value" 965 "Value" 964 "Value" 963 "Value" 962 "Value" 961 "Value" 960 "Value" 959 "Value" 958 "Value" 957 "Value" 956 "Value" 955 "Value" 954 "Value" 953 "Value" 952 "Value" 951 "Value" 950 "Value" 949 "Value" 948 "Value" 947 "Value" 946 "Value" 945 "Value" 944 "Value" 943 "Value" 942 "Value" 941 "Value" 940 "Value" 939 "Value" 938 "Value" 937 "Value" 936 "Value" 935 "Value" 934 "Value" 933 "Value" 932 "Value" 931 "Value" 930 "Value" 929 "Value" 928 "Value" 927 "Value" 926 "Value" 925 "Value" 924 "Value" 923 "Value" 922 "Value" 921 "Value" 920 "Value" 919 "Value" 918 "Value" 917 "Value" 916 "Value" 915 "Value" 914 "Value" 913 "Value" 912 "Value" 911 "Value" 910 "Value" 909 "Value" 908 "Value" 907 "Value" 906 "Value" 905 "Value" 904 "Value" 903 "Value" 902 "Value" 901 "Value" 900 "Value" 899 "Value" 898 "Value" 897 "Value" 896 "Value" 895 "Value" 894 "Value" 893 "Value" 892 "Value" 891 "Value" 890 "Value" 889 "Value" 888 "Value" 887 "Value" 886 "Value" 885 "Value" 884 "Value" 883 "Value" 882 "Value" 881 "Value" 880 "Value" 879 "Value" 878 "Value" 877 "Value" 876 "Value" 875 "Value" 874 "Value" 873 "Value" 872 "Value" 871 "Value" 870 "Value" 869 "Value" 868 "Value" 867 "Value" 866 "Value" 865 "Value" 864 "Value" 863 "Value" 862 "Value" 861 "Value" 860 "Value" 859 "Value" 858 "Value" 857 "Value" 856 "Value" 855 "Value" 854 "Value" 853 "Value" 852 "Value" 851 "Value" 850 "Value" 849 "Value" 848 "Value" 847 "Value" 846 "Value" 845 "Value" 844 "Value" 843 "Value" 842 "Value" 841 "Value" 840 "Value" 839 "Value" 838 "Value" 837 "Value" 836 "Value" 835 "Value" 834 "Value" 833 "Value" 832 "Value" 831 "Value" 830 "Value" 829 "Value" 828 "Value" 827 "Value" 826 "Value" 825 "Value" 824 "Value" 823 "Value" 822 "Value" 821 "Value" 820 "Value" 819 "Value" 818 "Value" 817 "Value" 816 "Value" 815 "Value" 814 "Value" 813 "Value" 812 "Value" 811 "Value" 810 "Value" 809 "Value" 808 "Value" 807 "Value" 806 "Value" 805 "Value" 804 "Value" 803 "Value" 802 "Value" 801 "Value" 800 "Value" 799 "Value" 798 "Value" 797 "Value" 796 "Value" 795 "Value" 794 "Value" 793 "Value" 792 "Value" 791 "Value" 790 "Value" 789 "Value" 788 "Value" 787 "Value" 786 "Value" 785 "Value" 784 "Value" 783 "Value" 782 "Value" 781 "Value" 780 "Value" 779 "Value" 778 "Value" 777 "Value" 776 "Value" 775 "Value" 774 "Value" 773 "Value" 772 "Value" 771 "Value" 770 "Value" 769 "Value" 768 "Value" 767 "Value" 766 "Value" 765 "Value" 764 "Value" 763 "Value" 762 "Value" 761 "Value" 760 "Value" 759 "Value" 758 "Value" 757 "Value" 756 "Value" 755 "Value" 754 "Value" 753 "Value" 752 "Value" 751 "Value" 750 "Value" 749 "Value" 748 "Value" 747 "Value" 746 "Value" 745 "Value" 744 "Value" 743 "Value" 742 "Value" 741 "Value" 740 "Value" 739 "Value" 738 "Value" 737 "Value" 736 "Value" 735 "Value" 734 "Value" 733 "Value" 732 "Value" 731 "Value" 730 "Value" 729 "Value" 728 "Value" 727 "Value" 726 "Value" 725 "Value" 724 "Value" 723 "Value" 722 "Value" 721 "Value" 720 "Value" 719 "Value" 718 "Value" 717 "Value" 716 "Value" 715 "Value" 714 "Value" 713 "Value" 712 "Value" 711 "Value" 710 "Value" 709 "Value" 708 "Value" 707 "Value" 706 "Value" 705 "Value" 704 "Value" 703 "Value" 702 "Value" 701 "Value" 700 "Value" 699 "Value" 698 "Value" 697 "Value" 696 "Value" 695 "Value" 694 "Value" 693 "Value" 692 "Value" 691 "Value" 690 "Value" 689 "Value" 688 "Value" 687 "Value" 686 "Value" 685 "Value" 684 "Value" 683 "Value" 682 "Value" 681 "Value" 680 "Value" 679 "Value" 678 "Value" 677 "Value" 676 "Value" 675 "Value" 674 "Value" 673 "Value" 672 "Value" 671 "Value" 670 "Value" 669 "Value" 668 "Value" 667 "Value" 666 "Value" 665 "Value" 664 "Value" 663 "Value" 662 "Value" 661 "Value" 660 "Value" 659 "Value" 658 "Value" 657 "Value" 656 "Value" 655 "Value" 654 "Value" 653 "Value" 652 "Value" 651 "Value" 650 "Value" 649 "Value" 648 "Value" 647 "Value" 646 "Value" 645 "Value" 644 "Value" 643 "Value" 642 "Value" 641 "Value" 640 "Value" 639 "Value" 638 "Value" 637 "Value" 636 "Value" 635 "Value" 634 "Value" 633 "Value" 632 "Value" 631 "Value" 630 "Value" 629 "Value" 628 "Value" 627 "Value" 626 "Value" 625 "Value" 624 "Value" 623 "Value" 622 "Value" 621 "Value" 620 "Value" 619 "Value" 618 "Value" 617 "Value" 616 "Value" 615 "Value" 614 "Value" 613 "Value" 612 "Value" 611 "Value" 610 "Value" 609 "Value" 608 "Value" 607 "Value" 606 "Value" 605 "Value" 604 "Value" 603 "Value" 602 "Value" 601 "Value" 600 "Value" 599 "Value" 598 "Value" 597 "Value" 596 "Value" 595 "Value" 594 "Value" 593 "Value" 592 "Value" 591 "Value" 590 "Value" 589 "Value" 588 "Value" 587 "Value" 586 "Value" 585 "Value" 584 "Value" 583 "Value" 582 "Value" 581 "Value" 580 "Value" 579 "Value" 578 "Value" 577 "Value" 576 "Value" 575 "Value" 574 "Value" 573 "Value" 572 "Value" 571 "Value" 570 "Value" 569 "Value" 568 "Value" 567 "Value" 566 "Value" 565 "Value" 564 "Value" 563 "Value" 562 "Value" 561 "Value" 560 "Value" 559 "Value" 558 "Value" 557 "Value" 556 "Value" 555 "Value" 554 "Value" 553 "Value" 552 "Value" 551 "Value" 550 "Value" 549 "Value" 548 "Value" 547 "Value" 546 "Value" 545 "Value" 544 "Value" 543 "Value" 542 "Value" 541 "Value" 540 "Value" 539 "Value" 538 "Value" 537 "Value" 536 "Value" 535 "Value" 534 "Value" 533 "Value" 532 "Value" 531 "Value" 530 "Value" 529 "Value" 528 "Value" 527 "Value" 526 "Value" 525 "Value" 524 "Value" 523 "Value" 522 "Value" 521 "Value" 520 "Value" 519 "Value" 518 "Value" 517 "Value" 516 "Value" 515 "Value" 514 "Value" 513 "Value" 512 "Value" 511 "Value" 510 "Value" 509 "Value" 508 "Value" 507 "Value" 506 "Value" 505 "Value" 504 "Value" 503 "Value" 502 "Value" 501 "Value" 500 "Value" 499 "Value" 498 "Value" 497 "Value" 496 "Value" 495 "Value" 494 "Value" 493 "Value" 492 "Value" 491 "Value" 490 "Value" 489 "Value" 488 "Value" 487 "Value" 486 "Value" 485 "Value" 484 "Value" 483 "Value" 482 "Value" 481 "Value" 480 "Value" 479 "Value" 478 "Value" 477 "Value" 476 "Value" 475 "Value" 474 "Value" 473 "Value" 472 "Value" 471 "Value" 470 "Value" 469 "Value" 468 "Value" 467 "Value" 466 "Value" 465 "Value" 464 "Value" 463 "Value" 462 "Value" 461 "Value" 460 "Value" 459 "Value" 458 "Value" 457 "Value" 456 "Value" 455 "Value" 454 "Value" 453 "Value" 452 "Value" 451 "Value" 450 "Value" 449 "Value" 448 "Value" 447 "Value" 446 "Value" 445 "Value" 444 "Value" 443 "Value" 442 "Value" 441 "Value" 440 "Value" 439 "Value" 438 "Value" 437 "Value" 436 "Value" 435 "Value" 434 "Value" 433 "Value" 432 "Value" 431 "Value" 430 "Value" 429 "Value" 428 "Value" 427 "Value" 426 "Value" 425 "Value" 424 "Value" 423 "Value" 422 "Value" 421 "Value" 420 "Value" 419 "Value" 418 "Value" 417 "Value" 416 "Value" 415 "Value" 414 "Value" 413 "Value" 412 "Value" 411 "Value" 410 "Value" 409 "Value" 408 "Value" 407 "Value" 406 "Value" 405 "Value" 404 "Value" 403 "Value" 402 "Value" 401 "Value" 400 "Value" 399 "Value" 398 "Value" 397 "Value" 396 "Value" 395 "Value" 394 "Value" 393 "Value" 392 "Value" 391 "Value" 390 "Value" 389 "Value" 388 "Value" 387 "Value" 386 "Value" 385 "Value" 384 "Value" 383 "Value" 382 "Value" 381 "Value" 380 "Value" 379 "Value" 378 "Value" 377 "Value" 376 "Value" 375 "Value" 374 "Value" 373 "Value" 372 "Value" 371 "Value" 370 "Value" 369 "Value" 368 "Value" 367 "Value" 366 "Value" 365 "Value" 364 "Value" 363 "Value" 362 "Value" 361 "Value" 360 "Value" 359 "Value" 358 "Value" 357 "Value" 356 "Value" 355 "Value" 354 "Value" 353 "Value" 352 "Value" 351 "Value" 350 "Value" 349 "Value" 348 "Value" 347 "Value" 346 "Value" 345 "Value" 344 "Value" 343 "Value" 342 "Value" 341 "Value" 340 "Value" 339 "Value" 338 "Value" 337 "Value" 336 "Value" 335 "Value" 334 "Value" 333 "Value" 332 "Value" 331 "Value" 330 "Value" 329 "Value" 328 "Value" 327 "Value" 326 "Value" 325 "Value" 324 "Value" 323 "Value" 322 "Value" 321 "Value" 320 "Value" 319 "Value" 318 "Value" 317 "Value" 316 "Value" 315 "Value" 314 "Value" 313 "Value" 312 "Value" 311 "Value" 310 "Value" 309 "Value" 308 "Value" 307 "Value" 306 "Value" 305 "Value" 304 "Value" 303 "Value" 302 "Value" 301 "Value" 300 "Value" 299 "Value" 298 "Value" 297 "Value" 296 "Value" 295 "Value" 294 "Value" 293 "Value" 292 "Value" 291 "Value" 290 "Value" 289 "Value" 288 "Value" 287 "Value" 286 "Value" 285 "Value" 284 "Value" 283 "Value" 282 "Value" 281 "Value" 280 "Value" 279 "Value" 278 "Value" 277 "Value" 276 "Value" 275 "Value" 274 "Value" 273 "Value" 272 "Value" 271 "Value" 270 "Value" 269 "Value" 268 "Value" 267 "Value" 266 "Value" 265 "Value" 264 "Value" 263 "Value" 262 "Value" 261 "Value" 260 "Value" 259 "Value" 258 "Value" 257 "Value" 256 "Value" 255 "Value" 254 "Value" 253 "Value" 252 "Value" 251 "Value" 250 "Value" 249 "Value" 248 "Value" 247 "Value" 246 "Value" 245 "Value" 244 "Value" 243 "Value" 242 "Value" 241 "Value" 240 "Value" 239 "Value" 238 "Value" 237 "Value" 236 "Value" 235 "Value" 234 "Value" 233 "Value" 232 "Value" 231 "Value" 230 "Value" 229 "Value" 228 "Value" 227 "Value" 226 "Value" 225 "Value" 224 "Value" 223 "Value" 222 "Value" 221 "Value" 220 "Value" 219 "Value" 218 "Value" 217 "Value" 216 "Value" 215 "Value" 214 "Value" 213 "Value" 212 "Value" 211 "Value" 210 "Value" 209 "Value" 208 "Value" 207 "Value" 206 "Value" 205 "Value" 204 "Value" 203 "Value" 202 "Value" 201 "Value" 200 "Value" 199 "Value" 198 "Value" 197 "Value" 196 "Value" 195 "Value" 194 "Value" 193 "Value" 192 "Value" 191 "Value" 190 "Value" 189 "Value" 188 "Value" 187 "Value" 186 "Value" 185 "Value" 184 "Value" 183 "Value" 182 "Value" 181 "Value" 180 "Value" 179 "Value" 178 "Value" 177 "Value" 176 "Value" 175 "Value" 174 "Value" 173 "Value" 172 "Value" 171 "Value" 170 "Value" 169 "Value" 168 "Value" 167 "Value" 166 "Value" 165 "Value" 164 "Value" 163 "Value" 162 "Value" 161 "Value" 160 "Value" 159 "Value" 158 "Value" 157 "Value" 156 "Value" 155 "Value" 154 "Value" 153 "Value" 152 "Value" 151 "Value" 150 "Value" 149 "Value" 148 "Value" 147 "Value" 146 "Value" 145 "Value" 144 "Value" 143 "Value" 142 "Value" 141 "Value" 140 "Value" 139 "Value" 138 "Value" 137 "Value" 136 "Value" 135 "Value" 134 "Value" 133 "Value" 132 "Value" 131 "Value" 130 "Value" 129 "Value" 128 "Value" 127 "Value" 126 "Value" 125 "Value" 124 "Value" 123 "Value" 122 "Value" 121 "Value" 120 "Value" 119 "Value" 118 "Value" 117 "Value" 116 "Value" 115 "Value" 114 "Value" 113 "Value" 112 "Value" 111 "Value" 110 "Value" 109 "Value" 108 "Value" 107 "Value" 106 "Value" 105 "Value" 104 "Value" 103 "Value" 102 "Value" 101 "Value" 100 "Value" 99 "Value" 98 "Value" 97 "Value" 96 "Value" 95 "Value" 94 "Value" 93 "Value" 92 "Value" 91 "Value" 90 "Value" 89 "Value" 88 "Value" 87 "Value" 86 "Value" 85 "Value" 84 "Value" 83 "Value" 82 "Value" 81 "Value" 80 "Value" 79 "Value" 78 "Value" 77 "Value" 76 "Value" 75 "Value" 74 "Value" 73 "Value" 72 "Value" 71 "Value" 70 "Value" 69 "Value" 68 "Value" 67 "Value" 66 "Value" 65 "Value" 64 "Value" 63 "Value" 62 "Value" 61 "Value" 60 "Value" 59 "Value" 58 "Value" 57 "Value" 56 "Value" 55 "Value" 54 "Value" 53 "Value" 52 "Value" 51 "Value" 50 "Value" 49 "Value" 48 "Value" 47 "Value" 46 "Value" 45 "Value" 44 "Value" 43 "Value" 42 "Value" 41 "Value" 40 "Value" 39 "Value" 38 "Value" 37 "Value" 36 "Value" 35 "Value" 34 "Value" 33 "Value" 32 "Value" 31 "Value" 30 "Value" 29 "Value" 28 "Value" 27 "Value" 26 "Value" 25 "Value" 24 "Value" 23 "Value" 22 "Value" 21 "Value" 20 "Value" 19 "Value" 18 "Value" 17 "Value" 16 "Value" 15 "Value" 14 "Value" 13 "Value" 12 "Value" 11 "Value" 10 "Value" 9 "Value" 8 "Value" 7 "Value" 6 "Value" 5 "Value" 4 "Value" 3 "Value" 2 "Value" 1 "Value" 0 "Value" ;
VAL_ 563 ADCU3A_VertAcclVld 1 "Valid" 0 "Invalid" ;
